VERSION ""

NS_ :

BS_:

BU_: PowertrainControlModule AtmosphericSensor SafetyRestraintSystem2 Aftertreatment_2_GasOutlet Aftertreatment_2_GasIntake DieselPartFilterControl Turbocharger SafetyRestraintSystem1 CabDisplay2 Aftertreatment_1_GasOutlet Aftertreatment_1_GasIntake OnBoardDataLogger OffBoardDiagnosticTool2 OffBoardDiagnosticTool1 FileServer ParkingBrakeController SeatController2 FanDriveController SteeringColumnUnit CommunicationUnitRadio CommunicationUnitSatellite CommunicationUnitCellular PropulsionBatteryCharger ChassisController2 ChassisController1 EngineValveControl AuxiliaryHeater2 AuxiliaryHeater1 ClutchUnit RampControl InformationSystem1 SuspensionSystemController2 OilSensor VehicleDynamicStability ExhaustEmissionController TransmissionDisplay2 TransmissionDisplay1 ClimateControl2 WaterPumpController RearAxleSteeringController LightingOperatorControl SeatController1 IgnitionController2 IgnitionController1 TirePressureController CabController2 CabController1 PneumaticSystemController SuspensionSystemController1 HydraulicPumpController EnduranceBrakingSystem RetarderExhaustEngine2 OnBoardDiagnosticUnit HeadwayController RetarderExhaustEngine1 CabDisplay1 ManagementComputer VirtualTerminal OffVehicleGateway PowerTakeOffFront HitchControl AuxiliaryValveControl BodyController TractorTrailerBridge1 StarterSystem ElectricalSystem VehicleSecurity VehicleNavigation AerodynamicControl ElectricalChargingSystem ClimateControl1 TripRecorder InstrumentCluster SuspensionDriveAxle2 SuspensionDriveAxle1 SuspensionSteerAxle SteeringController FuelSystem CruiseControl RetarderDriveline RetarderEngine BrakesDriveAxle2 BrakesDriveAxle1 BrakesSystemController BrakesSteerAxle AxleDrive2 AxleDrive1 AxleSteering PowerTakeOff ShiftConsoleSecondary ShiftConsolePrimary Transmission2 Transmission1 Engine2 Engine1

BO_ 2566663422 BCLC: 8 Vector__XXX
 SG_ TrlrBrkClprLnngClranceAxle5Right : 38|2@1+ (1,0) [0|3] "" Vector__XXX
 SG_ TrlrBrkClprLnngClaranceAxle5Left : 36|2@1+ (1,0) [0|3] "" Vector__XXX
 SG_ TrlrBrkClprLnngClranceAxle4Right : 34|2@1+ (1,0) [0|3] "" Vector__XXX
 SG_ TrlrBrkClprLnngClaranceAxle4Left : 32|2@1+ (1,0) [0|3] "" Vector__XXX
 SG_ TrlrBrkClprLnngClranceAxle3Right : 30|2@1+ (1,0) [0|3] "" Vector__XXX
 SG_ TrlrBrkClprLnngClaranceAxle3Left : 28|2@1+ (1,0) [0|3] "" Vector__XXX
 SG_ TrlrBrkClprLnngClranceAxle2Right : 26|2@1+ (1,0) [0|3] "" Vector__XXX
 SG_ TrlrBrkClprLnngClaranceAxle2Left : 24|2@1+ (1,0) [0|3] "" Vector__XXX
 SG_ TrlrBrkClprLnngClranceAxle1Right : 22|2@1+ (1,0) [0|3] "" Vector__XXX
 SG_ TrlrBrkClprLnngClaranceAxle1Left : 20|2@1+ (1,0) [0|3] "" Vector__XXX
 SG_ TrctrBrkClprLnngClrnceAxle5Right : 18|2@1+ (1,0) [0|3] "" Vector__XXX
 SG_ TrctrBrkClprLnngClranceAxle5Left : 16|2@1+ (1,0) [0|3] "" Vector__XXX
 SG_ TrctrBrkClprLnngClrnceAxle4Right : 14|2@1+ (1,0) [0|3] "" Vector__XXX
 SG_ TrctrBrkClprLnngClranceAxle4Left : 12|2@1+ (1,0) [0|3] "" Vector__XXX
 SG_ TrctrBrkClprLnngClrnceAxle3Right : 10|2@1+ (1,0) [0|3] "" Vector__XXX
 SG_ TrctrBrkClprLnngClranceAxle3Left : 8|2@1+ (1,0) [0|3] "" Vector__XXX
 SG_ TrctrBrkClprLnngClrnceAxle2Right : 6|2@1+ (1,0) [0|3] "" Vector__XXX
 SG_ TrctrBrkClprLnngClranceAxle2Left : 4|2@1+ (1,0) [0|3] "" Vector__XXX
 SG_ TrctrBrkClprLnngClrnceAxle1Right : 2|2@1+ (1,0) [0|3] "" Vector__XXX
 SG_ TrctrBrkClprLnngClranceAxle1Left : 0|2@1+ (1,0) [0|3] "" Vector__XXX

BO_ 2566663166 CCVS4: 8 Vector__XXX
 SG_ CruiseCtrlAdjustedMaxSpeed : 16|16@1+ (0.00390625,0) [0|250.996] "km/h" Vector__XXX
 SG_ AppliedVehicleSpeedLimit : 0|16@1+ (0.00390625,0) [0|250.996] "km/h" Vector__XXX

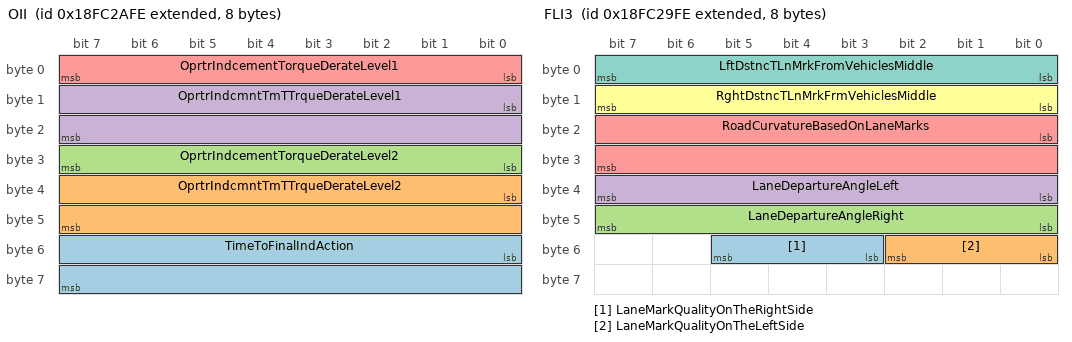
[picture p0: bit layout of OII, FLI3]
BO_ 2566662910 OII: 8 Vector__XXX
 SG_ TimeToFinalIndAction : 48|16@1+ (1,0) [0|64255] "min" Vector__XXX
 SG_ OprtrIndcmntTmTTrqueDerateLevel2 : 32|16@1+ (1,0) [0|64255] "min" Vector__XXX
 SG_ OprtrIndcementTorqueDerateLevel2 : 24|8@1+ (1,0) [0|250] "%" Vector__XXX
 SG_ OprtrIndcmntTmTTrqueDerateLevel1 : 8|16@1+ (1,0) [0|64255] "min" Vector__XXX
 SG_ OprtrIndcementTorqueDerateLevel1 : 0|8@1+ (1,0) [0|250] "%" Vector__XXX

BO_ 2566662654 FLI3: 8 Vector__XXX
 SG_ LaneMarkQualityOnTheRightSide : 51|3@1+ (1,0) [0|7] "" Vector__XXX
 SG_ LaneMarkQualityOnTheLeftSide : 48|3@1+ (1,0) [0|7] "" Vector__XXX
 SG_ LaneDepartureAngleRight : 40|8@1+ (0.1,-12.5) [-12.5|12.5] "deg" Vector__XXX
 SG_ LaneDepartureAngleLeft : 32|8@1+ (0.1,-12.5) [-12.5|12.5] "deg" Vector__XXX
 SG_ RoadCurvatureBasedOnLaneMarks : 16|16@1+ (0.0078125,-250) [-250|251.992] "1/km" Vector__XXX
 SG_ RghtDstncTLnMrkFrmVehiclesMiddle : 8|8@1+ (0.02,0) [0|5] "m" Vector__XXX
 SG_ LftDstncTLnMrkFromVehiclesMiddle : 0|8@1+ (0.02,0) [0|5] "m" Vector__XXX

BO_ 2566662142 A1DEFI2: 8 Vector__XXX
 SG_ Ctrl2Temp : 8|8@1+ (1,-40) [-40|210] "°C" Vector__XXX
 SG_ Ctrl1Temp : 0|8@1+ (1,-40) [-40|210] "°C" Vector__XXX

BO_ 2566661630 AT1T1I2: 8 Vector__XXX
 SG_ Htr2 : 16|8@1+ (0.4,0) [0|100] "%" Vector__XXX
 SG_ Temp2 : 8|8@1+ (1,-40) [-40|210] "°C" Vector__XXX
 SG_ Volume2 : 0|8@1+ (0.4,0) [0|100] "%" Vector__XXX

BO_ 2566661374 A2DEFT1: 8 Vector__XXX
 SG_ Ctrl2Temp : 8|8@1+ (1,-40) [-40|210] "°C" Vector__XXX
 SG_ CtrlTemp : 0|8@1+ (1,-40) [-40|210] "°C" Vector__XXX
 SG_ Htr2 : 16|8@1+ (0.4,0) [0|100] "%" Vector__XXX
 SG_ Temp2 : 8|8@1+ (1,-40) [-40|210] "°C" Vector__XXX
 SG_ Volume2 : 0|8@1+ (0.4,0) [0|100] "%" Vector__XXX

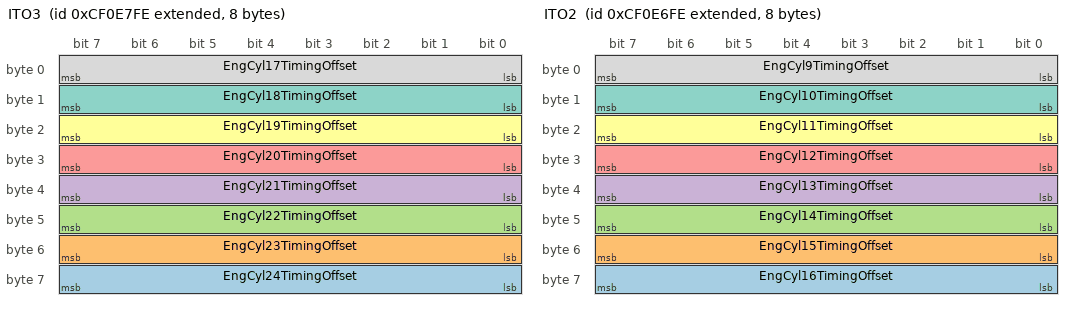
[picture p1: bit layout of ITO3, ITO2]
BO_ 2364598270 ITO3: 8 Vector__XXX
 SG_ EngCyl24TimingOffset : 56|8@1+ (0.1,-12.5) [-12.5|12.5] "deg" Vector__XXX
 SG_ EngCyl23TimingOffset : 48|8@1+ (0.1,-12.5) [-12.5|12.5] "deg" Vector__XXX
 SG_ EngCyl22TimingOffset : 40|8@1+ (0.1,-12.5) [-12.5|12.5] "deg" Vector__XXX
 SG_ EngCyl21TimingOffset : 32|8@1+ (0.1,-12.5) [-12.5|12.5] "deg" Vector__XXX
 SG_ EngCyl20TimingOffset : 24|8@1+ (0.1,-12.5) [-12.5|12.5] "deg" Vector__XXX
 SG_ EngCyl19TimingOffset : 16|8@1+ (0.1,-12.5) [-12.5|12.5] "deg" Vector__XXX
 SG_ EngCyl18TimingOffset : 8|8@1+ (0.1,-12.5) [-12.5|12.5] "deg" Vector__XXX
 SG_ EngCyl17TimingOffset : 0|8@1+ (0.1,-12.5) [-12.5|12.5] "deg" Vector__XXX

BO_ 2364598014 ITO2: 8 Vector__XXX
 SG_ EngCyl16TimingOffset : 56|8@1+ (0.1,-12.5) [-12.5|12.5] "deg" Vector__XXX
 SG_ EngCyl15TimingOffset : 48|8@1+ (0.1,-12.5) [-12.5|12.5] "deg" Vector__XXX
 SG_ EngCyl14TimingOffset : 40|8@1+ (0.1,-12.5) [-12.5|12.5] "deg" Vector__XXX
 SG_ EngCyl13TimingOffset : 32|8@1+ (0.1,-12.5) [-12.5|12.5] "deg" Vector__XXX
 SG_ EngCyl12TimingOffset : 24|8@1+ (0.1,-12.5) [-12.5|12.5] "deg" Vector__XXX
 SG_ EngCyl11TimingOffset : 16|8@1+ (0.1,-12.5) [-12.5|12.5] "deg" Vector__XXX
 SG_ EngCyl10TimingOffset : 8|8@1+ (0.1,-12.5) [-12.5|12.5] "deg" Vector__XXX
 SG_ EngCyl9TimingOffset : 0|8@1+ (0.1,-12.5) [-12.5|12.5] "deg" Vector__XXX

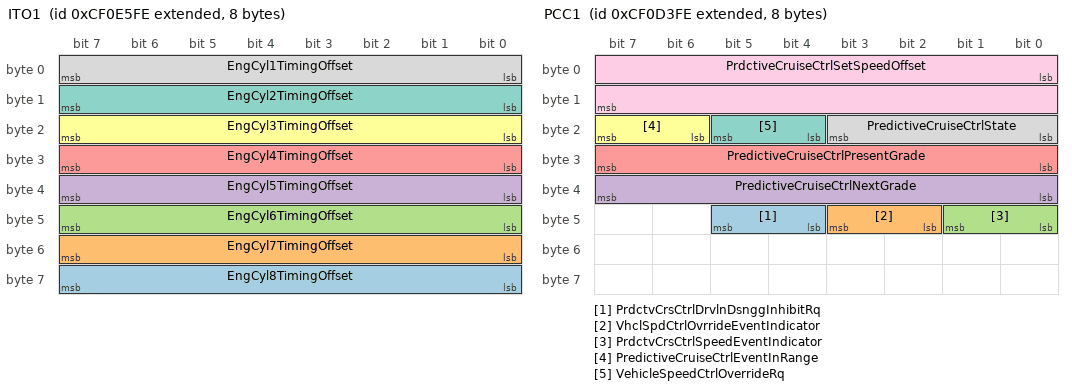
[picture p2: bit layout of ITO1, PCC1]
BO_ 2364597758 ITO1: 8 Vector__XXX
 SG_ EngCyl8TimingOffset : 56|8@1+ (0.1,-12.5) [-12.5|12.5] "deg" Vector__XXX
 SG_ EngCyl7TimingOffset : 48|8@1+ (0.1,-12.5) [-12.5|12.5] "deg" Vector__XXX
 SG_ EngCyl6TimingOffset : 40|8@1+ (0.1,-12.5) [-12.5|12.5] "deg" Vector__XXX
 SG_ EngCyl5TimingOffset : 32|8@1+ (0.1,-12.5) [-12.5|12.5] "deg" Vector__XXX
 SG_ EngCyl4TimingOffset : 24|8@1+ (0.1,-12.5) [-12.5|12.5] "deg" Vector__XXX
 SG_ EngCyl3TimingOffset : 16|8@1+ (0.1,-12.5) [-12.5|12.5] "deg" Vector__XXX
 SG_ EngCyl2TimingOffset : 8|8@1+ (0.1,-12.5) [-12.5|12.5] "deg" Vector__XXX
 SG_ EngCyl1TimingOffset : 0|8@1+ (0.1,-12.5) [-12.5|12.5] "deg" Vector__XXX

BO_ 2364593150 PCC1: 8 Vector__XXX
 SG_ PrdctvCrsCtrlDrvlnDsnggInhibitRq : 44|2@1+ (1,0) [0|3] "" Vector__XXX
 SG_ VhclSpdCtrlOvrrideEventIndicator : 42|2@1+ (1,0) [0|3] "" Vector__XXX
 SG_ PrdctvCrsCtrlSpeedEventIndicator : 40|2@1+ (1,0) [0|3] "" Vector__XXX
 SG_ PredictiveCruiseCtrlNextGrade : 32|8@1+ (0.125,-16) [-16|15.25] "%" Vector__XXX
 SG_ PredictiveCruiseCtrlPresentGrade : 24|8@1+ (0.125,-16) [-16|15.25] "%" Vector__XXX
 SG_ PredictiveCruiseCtrlEventInRange : 22|2@1+ (1,0) [0|3] "" Vector__XXX
 SG_ VehicleSpeedCtrlOverrideRq : 20|2@1+ (1,0) [0|3] "" Vector__XXX
 SG_ PredictiveCruiseCtrlState : 16|4@1+ (1,0) [0|15] "" Vector__XXX
 SG_ PrdctiveCruiseCtrlSetSpeedOffset : 0|16@1+ (0.00390625,-125) [-125|125.996] "km/h" Vector__XXX

BO_ 2364592894 EEC18: 8 Vector__XXX
 SG_ InAirSourceVlv : 16|2@1+ (1,0) [0|3] "" Vector__XXX
 SG_ EngCylHeadBypassActuator1Cmd : 0|16@1+ (0.0025,0) [0|160.6375] "%" Vector__XXX

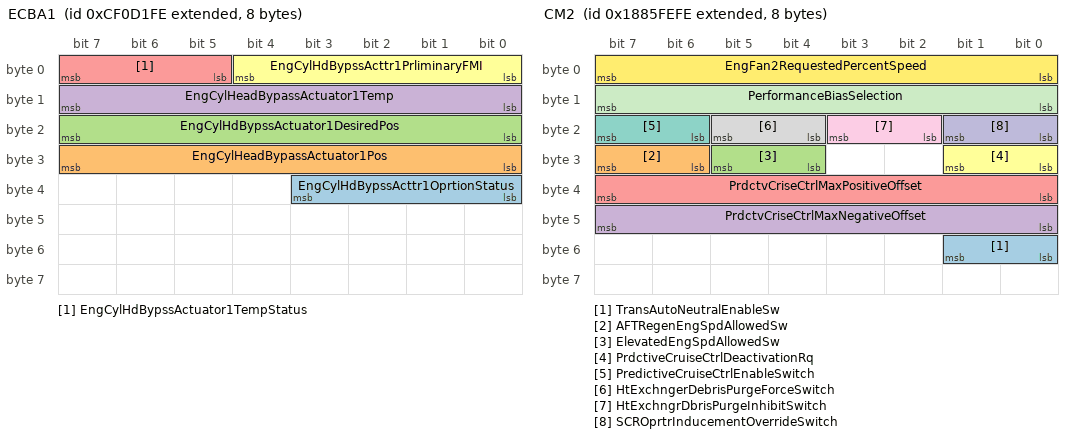
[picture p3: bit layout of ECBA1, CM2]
BO_ 2364592638 ECBA1: 8 Vector__XXX
 SG_ EngCylHdBypssActtr1OprtionStatus : 32|4@1+ (1,0) [0|15] "" Vector__XXX
 SG_ EngCylHeadBypassActuator1Pos : 24|8@1+ (0.4,0) [0|100] "%" Vector__XXX
 SG_ EngCylHdBypssActuator1DesiredPos : 16|8@1+ (0.4,0) [0|100] "%" Vector__XXX
 SG_ EngCylHeadBypassActuator1Temp : 8|8@1+ (1,-40) [-40|210] "°C" Vector__XXX
 SG_ EngCylHdBypssActuator1TempStatus : 5|3@1+ (1,0) [0|7] "" Vector__XXX
 SG_ EngCylHdBypssActtr1PrliminaryFMI : 0|5@1+ (1,0) [0|31] "" Vector__XXX

BO_ 2364592382 ECCR: 8 Vector__XXX
 SG_ EngCyl24ExcludeFromCombustionRq : 54|2@1+ (1,0) [0|3] "" Vector__XXX
 SG_ EngCyl23ExcludeFromCombustionRq : 52|2@1+ (1,0) [0|3] "" Vector__XXX
 SG_ EngCyl22ExcludeFromCombustionRq : 50|2@1+ (1,0) [0|3] "" Vector__XXX
 SG_ EngCyl21ExcludeFromCombustionRq : 48|2@1+ (1,0) [0|3] "" Vector__XXX
 SG_ EngCyl20ExcludeFromCombustionRq : 46|2@1+ (1,0) [0|3] "" Vector__XXX
 SG_ EngCyl19ExcludeFromCombustionRq : 44|2@1+ (1,0) [0|3] "" Vector__XXX
 SG_ EngCyl18ExcludeFromCombustionRq : 42|2@1+ (1,0) [0|3] "" Vector__XXX
 SG_ EngCyl17ExcludeFromCombustionRq : 40|2@1+ (1,0) [0|3] "" Vector__XXX
 SG_ EngCyl16ExcludeFromCombustionRq : 38|2@1+ (1,0) [0|3] "" Vector__XXX
 SG_ EngCyl15ExcludeFromCombustionRq : 36|2@1+ (1,0) [0|3] "" Vector__XXX
 SG_ EngCyl14ExcludeFromCombustionRq : 34|2@1+ (1,0) [0|3] "" Vector__XXX
 SG_ EngCyl13ExcludeFromCombustionRq : 32|2@1+ (1,0) [0|3] "" Vector__XXX
 SG_ EngCyl12ExcludeFromCombustionRq : 30|2@1+ (1,0) [0|3] "" Vector__XXX
 SG_ EngCyl11ExcludeFromCombustionRq : 28|2@1+ (1,0) [0|3] "" Vector__XXX
 SG_ EngCyl10ExcludeFromCombustionRq : 26|2@1+ (1,0) [0|3] "" Vector__XXX
 SG_ EngCyl9ExcludeFromCombustionRq : 24|2@1+ (1,0) [0|3] "" Vector__XXX
 SG_ EngCyl8ExcludeFromCombustionRq : 22|2@1+ (1,0) [0|3] "" Vector__XXX
 SG_ EngCyl7ExcludeFromCombustionRq : 20|2@1+ (1,0) [0|3] "" Vector__XXX
 SG_ EngCyl6ExcludeFromCombustionRq : 18|2@1+ (1,0) [0|3] "" Vector__XXX
 SG_ EngCyl5ExcludeFromCombustionRq : 16|2@1+ (1,0) [0|3] "" Vector__XXX
 SG_ EngCyl4ExcludeFromCombustionRq : 14|2@1+ (1,0) [0|3] "" Vector__XXX
 SG_ EngCyl3ExcludeFromCombustionRq : 12|2@1+ (1,0) [0|3] "" Vector__XXX
 SG_ EngCyl2ExcludeFromCombustionRq : 10|2@1+ (1,0) [0|3] "" Vector__XXX
 SG_ EngCyl1ExcludeFromCombustionRq : 8|2@1+ (1,0) [0|3] "" Vector__XXX
 SG_ NmbrOfEngCylndrsTExcldFrmCmbston : 0|8@1+ (1,0) [0|24] "" Vector__XXX

BO_ 2364567294 FPAC: 8 Vector__XXX
 SG_ EngFlInjctnPump2FuelCtrlValveCmd : 16|16@1+ (0.0025,0) [0|100] "%" Vector__XXX
 SG_ EngFlInjctnPump1FuelCtrlValveCmd : 0|16@1+ (0.0025,0) [0|100] "%" Vector__XXX

BO_ 2558918398 CM2: 8 Vector__XXX
 SG_ TransAutoNeutralEnableSw : 48|2@1+ (1,0) [0|3] "" Vector__XXX
 SG_ AFTRegenEngSpdAllowedSw : 30|2@1+ (1,0) [0|3] "" Vector__XXX
 SG_ ElevatedEngSpdAllowedSw : 28|2@1+ (1,0) [0|3] "" Vector__XXX
 SG_ PrdctvCriseCtrlMaxNegativeOffset : 40|8@1+ (0.125,-31.25) [-31.25|0] "km/h" Vector__XXX
 SG_ PrdctvCriseCtrlMaxPositiveOffset : 32|8@1+ (0.125,0) [0|31.25] "km/h" Vector__XXX
 SG_ PrdctiveCruiseCtrlDeactivationRq : 24|2@1+ (1,0) [0|3] "" Vector__XXX
 SG_ PredictiveCruiseCtrlEnableSwitch : 22|2@1+ (1,0) [0|3] "" Vector__XXX
 SG_ HtExchngerDebrisPurgeForceSwitch : 20|2@1+ (1,0) [0|3] "" Vector__XXX
 SG_ HtExchngrDbrisPurgeInhibitSwitch : 18|2@1+ (1,0) [0|3] "" Vector__XXX
 SG_ SCROprtrInducementOverrideSwitch : 16|2@1+ (1,0) [0|3] "" Vector__XXX
 SG_ PerformanceBiasSelection : 8|8@1+ (0.4,0) [0|100] "%" Vector__XXX
 SG_ EngFan2RequestedPercentSpeed : 0|8@1+ (0.4,0) [0|100] "%" Vector__XXX

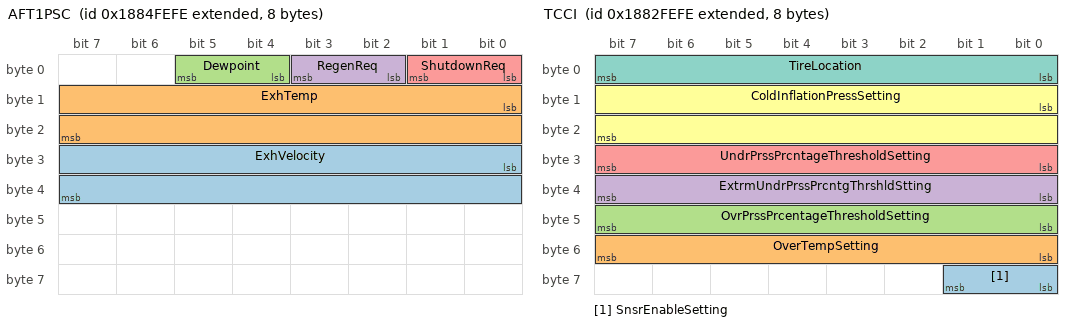
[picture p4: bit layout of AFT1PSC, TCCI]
BO_ 2558852862 AFT1PSC: 8 Vector__XXX
 SG_ ExhVelocity : 24|16@1+ (0.00390625,0) [0|250.996] "km/h" Vector__XXX
 SG_ ExhTemp : 8|16@1+ (0.03125,-273) [-273|1734.96875] "°C" Vector__XXX
 SG_ Dewpoint : 4|2@1+ (1,0) [0|3] "" Vector__XXX
 SG_ RegenReq : 2|2@1+ (1,0) [0|3] "" Vector__XXX
 SG_ ShutdownReq : 0|2@1+ (1,0) [0|3] "" Vector__XXX

BO_ 2558787326 PCIC: 8 Vector__XXX
 SG_ PayloadCorrectionFactorCmd : 24|8@1+ (1,-125) [-125|125] "%" Vector__XXX
 SG_ PayloadCalibCommandedWeight : 8|16@1+ (2,0) [0|128510] "kg" Vector__XXX
 SG_ PayloadCalibSetPointCmd : 0|4@1+ (1,0) [0|15] "" Vector__XXX

BO_ 2558721790 TCCI: 8 Vector__XXX
 SG_ SnsrEnableSetting : 56|2@1+ (1,0) [0|3] "" Vector__XXX
 SG_ OverTempSetting : 48|8@1+ (1,-40) [-40|210] "°C" Vector__XXX
 SG_ OvrPrssPrcentageThresholdSetting : 40|8@1+ (0.5,0) [0|125] "%" Vector__XXX
 SG_ ExtrmUndrPrssPrcntgThrshldStting : 32|8@1+ (0.5,0) [0|125] "%" Vector__XXX
 SG_ UndrPrssPrcntageThresholdSetting : 24|8@1+ (0.5,0) [0|125] "%" Vector__XXX
 SG_ ColdInflationPressSetting : 8|16@1+ (1,0) [0|64255] "kPa" Vector__XXX
 SG_ TireLocation : 0|8@1+ (1,0) [0|0] "" Vector__XXX

BO_ 2558656254 AFTSC: 8 Vector__XXX
 SG_ RqToPermitDEFDosingTestInjection : 4|3@1+ (1,0) [0|7] "" Vector__XXX
 SG_ RqToPermitDEFHydStiffnessCheck : 2|2@1+ (1,0) [0|3] "" Vector__XXX
 SG_ ThermalManagementInhReq : 0|2@1+ (1,0) [0|3] "" Vector__XXX

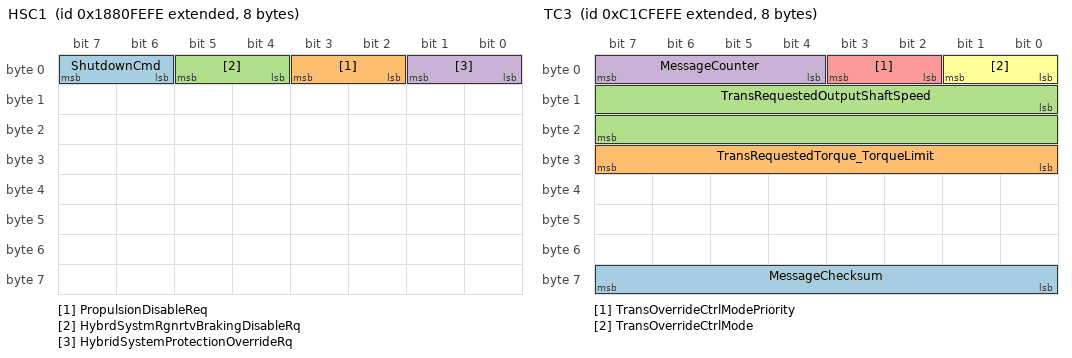
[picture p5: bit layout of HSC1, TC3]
BO_ 2558590718 HSC1: 8 Vector__XXX
 SG_ ShutdownCmd : 6|2@1+ (1,0) [0|3] "" Vector__XXX
 SG_ PropulsionDisableReq : 2|2@1+ (1,0) [0|3] "" Vector__XXX
 SG_ HybrdSystmRgnrtvBrakingDisableRq : 4|2@1+ (1,0) [0|3] "" Vector__XXX
 SG_ HybridSystemProtectionOverrideRq : 0|2@1+ (1,0) [0|3] "" Vector__XXX

BO_ 2350776062 EIC: 8 Vector__XXX
 SG_ EngTimingAdvance : 0|16@1+ (0.0078125,-200) [-200|301.99] "deg" Vector__XXX

BO_ 2350710526 TC3: 8 Vector__XXX
 SG_ MessageChecksum : 56|8@1+ (1,0) [0|255] "" Vector__XXX
 SG_ TransRequestedTorque_TorqueLimit : 24|8@1+ (1,-125) [-125|125] "%" Vector__XXX
 SG_ TransRequestedOutputShaftSpeed : 8|16@1+ (0.25,-8031.75) [-8031.375|8031.375] "rpm" Vector__XXX
 SG_ MessageCounter : 4|4@1+ (1,0) [0|15] "" Vector__XXX
 SG_ TransOverrideCtrlModePriority : 2|2@1+ (1,0) [0|3] "" Vector__XXX
 SG_ TransOverrideCtrlMode : 0|2@1+ (1,0) [0|3] "" Vector__XXX

BO_ 2582642430 PropA2: 8 Vector__XXX
 SG_ ManufacturerSpecificInformation : 0|64@1+ (1,0) [0|0] "" Vector__XXX

BO_ 2566836734 DM09: 8 Vector__XXX

BO_ 2566801918 GBSD: 8 Vector__XXX
 SG_ GroundBasedDirection : 56|2@1+ (1,0) [0|0] "" Vector__XXX
 SG_ GroundBasedImplementDistance : 16|32@1+ (1,0) [0|0] "" Vector__XXX
 SG_ GroundBasedImplementSpeed : 0|16@1+ (1,0) [0|0] "" Vector__XXX

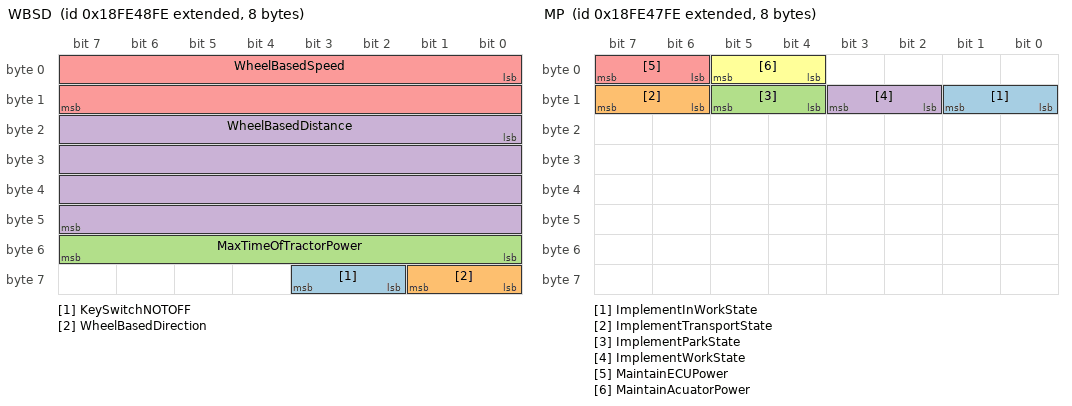
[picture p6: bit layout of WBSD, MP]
BO_ 2566801662 WBSD: 8 Vector__XXX
 SG_ KeySwitchNOTOFF : 58|2@1+ (1,0) [0|0] "" Vector__XXX
 SG_ WheelBasedDirection : 56|2@1+ (1,0) [0|0] "" Vector__XXX
 SG_ MaxTimeOfTractorPower : 48|8@1+ (1,0) [0|0] "" Vector__XXX
 SG_ WheelBasedDistance : 16|32@1+ (1,0) [0|0] "" Vector__XXX
 SG_ WheelBasedSpeed : 0|16@1+ (1,0) [0|0] "" Vector__XXX

BO_ 2566801406 MP: 8 Vector__XXX
 SG_ ImplementInWorkState : 8|2@1+ (1,0) [0|0] "" Vector__XXX
 SG_ ImplementTransportState : 14|2@1+ (1,0) [0|0] "" Vector__XXX
 SG_ ImplementParkState : 12|2@1+ (1,0) [0|0] "" Vector__XXX
 SG_ ImplementWorkState : 10|2@1+ (1,0) [0|0] "" Vector__XXX
 SG_ MaintainECUPower : 6|2@1+ (1,0) [0|0] "" Vector__XXX
 SG_ MaintainAcuatorPower : 4|2@1+ (1,0) [0|0] "" Vector__XXX

BO_ 2566801150 FHS: 8 Vector__XXX
 SG_ FrontDraft : 24|16@1+ (1,0) [0|0] "" Vector__XXX
 SG_ FrontNominalLowerLinkForce : 16|8@1+ (1,0) [0|0] "" Vector__XXX
 SG_ FrontHitchInworkIndication : 14|2@1+ (1,0) [0|0] "" Vector__XXX
 SG_ FrontHitchPos : 0|8@1+ (1,0) [0|0] "" Vector__XXX

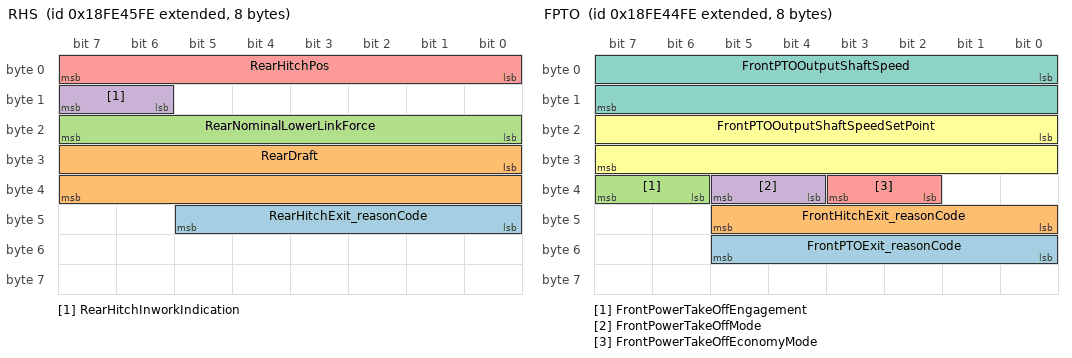
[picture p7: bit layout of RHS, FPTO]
BO_ 2566800894 RHS: 8 Vector__XXX
 SG_ RearHitchExit_reasonCode : 40|6@1+ (1,0) [0|0] "" Vector__XXX
 SG_ RearDraft : 24|16@1+ (1,0) [0|0] "" Vector__XXX
 SG_ RearNominalLowerLinkForce : 16|8@1+ (1,0) [0|0] "" Vector__XXX
 SG_ RearHitchInworkIndication : 14|2@1+ (1,0) [0|0] "" Vector__XXX
 SG_ RearHitchPos : 0|8@1+ (1,0) [0|0] "" Vector__XXX

BO_ 2566800638 FPTO: 8 Vector__XXX
 SG_ FrontPTOExit_reasonCode : 48|6@1+ (1,0) [0|0] "" Vector__XXX
 SG_ FrontHitchExit_reasonCode : 40|6@1+ (1,0) [0|0] "" Vector__XXX
 SG_ FrontPowerTakeOffEngagement : 38|2@1+ (1,0) [0|0] "" Vector__XXX
 SG_ FrontPowerTakeOffMode : 36|2@1+ (1,0) [0|0] "" Vector__XXX
 SG_ FrontPowerTakeOffEconomyMode : 34|2@1+ (1,0) [0|0] "" Vector__XXX
 SG_ FrontPTOOutputShaftSpeedSetPoint : 16|16@1+ (1,0) [0|0] "" Vector__XXX
 SG_ FrontPTOOutputShaftSpeed : 0|16@1+ (1,0) [0|0] "" Vector__XXX

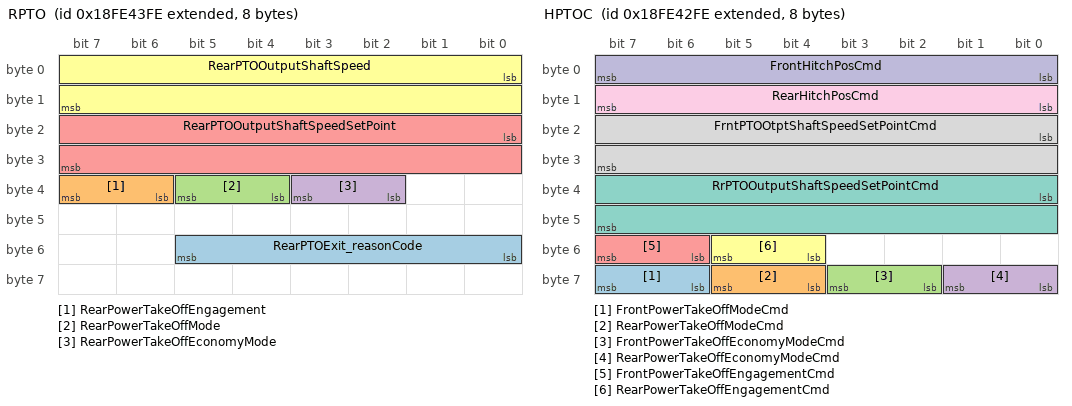
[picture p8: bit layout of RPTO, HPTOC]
BO_ 2566800382 RPTO: 8 Vector__XXX
 SG_ RearPTOExit_reasonCode : 48|6@1+ (1,0) [0|0] "" Vector__XXX
 SG_ RearPowerTakeOffEngagement : 38|2@1+ (1,0) [0|0] "" Vector__XXX
 SG_ RearPowerTakeOffMode : 36|2@1+ (1,0) [0|0] "" Vector__XXX
 SG_ RearPowerTakeOffEconomyMode : 34|2@1+ (1,0) [0|0] "" Vector__XXX
 SG_ RearPTOOutputShaftSpeedSetPoint : 16|16@1+ (1,0) [0|0] "" Vector__XXX
 SG_ RearPTOOutputShaftSpeed : 0|16@1+ (1,0) [0|0] "" Vector__XXX

BO_ 2566800126 HPTOC: 8 Vector__XXX
 SG_ FrontPowerTakeOffModeCmd : 62|2@1+ (1,0) [0|0] "" Vector__XXX
 SG_ RearPowerTakeOffModeCmd : 60|2@1+ (1,0) [0|0] "" Vector__XXX
 SG_ FrontPowerTakeOffEconomyModeCmd : 58|2@1+ (1,0) [0|0] "" Vector__XXX
 SG_ RearPowerTakeOffEconomyModeCmd : 56|2@1+ (1,0) [0|0] "" Vector__XXX
 SG_ FrontPowerTakeOffEngagementCmd : 54|2@1+ (1,0) [0|0] "" Vector__XXX
 SG_ RearPowerTakeOffEngagementCmd : 52|2@1+ (1,0) [0|0] "" Vector__XXX
 SG_ RrPTOOutputShaftSpeedSetPointCmd : 32|16@1+ (1,0) [0|0] "" Vector__XXX
 SG_ FrntPTOOtptShaftSpeedSetPointCmd : 16|16@1+ (1,0) [0|0] "" Vector__XXX
 SG_ RearHitchPosCmd : 8|8@1+ (1,0) [0|0] "" Vector__XXX
 SG_ FrontHitchPosCmd : 0|8@1+ (1,0) [0|0] "" Vector__XXX

BO_ 2566799358 AV15C: 8 Vector__XXX
 SG_ AuxValve15FailSafeModeCmd : 22|2@1+ (1,0) [0|0] "" Vector__XXX
 SG_ AuxValve15StateCmd : 16|4@1+ (1,0) [0|0] "" Vector__XXX
 SG_ AuxValve15PortFlowCmd : 0|8@1+ (1,0) [0|0] "" Vector__XXX

BO_ 2566799102 AV14C: 8 Vector__XXX
 SG_ AuxValve14FailSafeModeCmd : 22|2@1+ (1,0) [0|0] "" Vector__XXX
 SG_ AuxValve14StateCmd : 16|4@1+ (1,0) [0|0] "" Vector__XXX
 SG_ AuxValve14PortFlowCmd : 0|8@1+ (1,0) [0|0] "" Vector__XXX

BO_ 2566798846 AV13C: 8 Vector__XXX
 SG_ AuxValve13FailSafeModeCmd : 22|2@1+ (1,0) [0|0] "" Vector__XXX
 SG_ AuxValve13StateCmd : 16|4@1+ (1,0) [0|0] "" Vector__XXX
 SG_ AuxValve13PortFlowCmd : 0|8@1+ (1,0) [0|0] "" Vector__XXX

BO_ 2566798590 AV12C: 8 Vector__XXX
 SG_ AuxValve12FailSafeModeCmd : 22|2@1+ (1,0) [0|0] "" Vector__XXX
 SG_ AuxValve12StateCmd : 16|4@1+ (1,0) [0|0] "" Vector__XXX
 SG_ AuxValve12PortFlowCmd : 0|8@1+ (1,0) [0|0] "" Vector__XXX

BO_ 2566798334 AV11C: 8 Vector__XXX
 SG_ AuxValve11FailSafeModeCmd : 22|2@1+ (1,0) [0|0] "" Vector__XXX
 SG_ AuxValve11StateCmd : 16|4@1+ (1,0) [0|0] "" Vector__XXX
 SG_ AuxValve11PortFlowCmd : 0|8@1+ (1,0) [0|0] "" Vector__XXX

BO_ 2566798078 AV10C: 8 Vector__XXX
 SG_ AuxValve10FailSafeModeCmd : 22|2@1+ (1,0) [0|0] "" Vector__XXX
 SG_ AuxValve10StateCmd : 16|4@1+ (1,0) [0|0] "" Vector__XXX
 SG_ AuxValve10PortFlowCmd : 0|8@1+ (1,0) [0|0] "" Vector__XXX

BO_ 2566797822 AV09C: 8 Vector__XXX
 SG_ AuxValve9FailSafeModeCmd : 22|2@1+ (1,0) [0|0] "" Vector__XXX
 SG_ AuxValve9StateCmd : 16|4@1+ (1,0) [0|0] "" Vector__XXX
 SG_ AuxValve9PortFlowCmd : 0|8@1+ (1,0) [0|0] "" Vector__XXX

BO_ 2566797566 AV08C: 8 Vector__XXX
 SG_ AuxValve8FailSafeModeCmd : 22|2@1+ (1,0) [0|0] "" Vector__XXX
 SG_ AuxValve8StateCmd : 16|4@1+ (1,0) [0|0] "" Vector__XXX
 SG_ AuxValve8PortFlowCmd : 0|8@1+ (1,0) [0|0] "" Vector__XXX

BO_ 2566797310 AV07C: 8 Vector__XXX
 SG_ AuxValve7FailSafeModeCmd : 22|2@1+ (1,0) [0|0] "" Vector__XXX
 SG_ AuxValve7StateCmd : 16|4@1+ (1,0) [0|0] "" Vector__XXX
 SG_ AuxValve7PortFlowCmd : 0|8@1+ (1,0) [0|0] "" Vector__XXX

BO_ 2566797054 AV06C: 8 Vector__XXX
 SG_ AuxValve6FailSafeModeCmd : 22|2@1+ (1,0) [0|0] "" Vector__XXX
 SG_ AuxValve6StateCmd : 16|4@1+ (1,0) [0|0] "" Vector__XXX
 SG_ AuxValve6PortFlowCmd : 0|8@1+ (1,0) [0|0] "" Vector__XXX

BO_ 2566796798 AV05C: 8 Vector__XXX
 SG_ AuxValve5FailSafeModeCmd : 22|2@1+ (1,0) [0|0] "" Vector__XXX
 SG_ AuxValve5StateCmd : 16|4@1+ (1,0) [0|0] "" Vector__XXX
 SG_ AuxValve5PortFlowCmd : 0|8@1+ (1,0) [0|0] "" Vector__XXX

BO_ 2566796542 AV04C: 8 Vector__XXX
 SG_ AuxValve4FailSafeModeCmd : 22|2@1+ (1,0) [0|0] "" Vector__XXX
 SG_ AuxValve4StateCmd : 16|4@1+ (1,0) [0|0] "" Vector__XXX
 SG_ AuxValve4PortFlowCmd : 0|8@1+ (1,0) [0|0] "" Vector__XXX

BO_ 2566796286 AV03C: 8 Vector__XXX
 SG_ AuxValve3FailSafeModeCmd : 22|2@1+ (1,0) [0|0] "" Vector__XXX
 SG_ AuxValve3StateCmd : 16|4@1+ (1,0) [0|0] "" Vector__XXX
 SG_ AuxValve3PortFlowCmd : 0|8@1+ (1,0) [0|0] "" Vector__XXX

BO_ 2566796030 AV02C: 8 Vector__XXX
 SG_ AuxValve2FailSafeModeCmd : 22|2@1+ (1,0) [0|0] "" Vector__XXX
 SG_ AuxValve2StateCmd : 16|4@1+ (1,0) [0|0] "" Vector__XXX
 SG_ AuxValve2PortFlowCmd : 0|8@1+ (1,0) [0|0] "" Vector__XXX

BO_ 2566795774 AV01C: 8 Vector__XXX
 SG_ AuxValve1FailSafeModeCmd : 22|2@1+ (1,0) [0|0] "" Vector__XXX
 SG_ AuxValve1StateCmd : 16|4@1+ (1,0) [0|0] "" Vector__XXX
 SG_ AuxValve1PortFlowCmd : 0|8@1+ (1,0) [0|0] "" Vector__XXX

BO_ 2566795518 AV00C: 8 Vector__XXX
 SG_ AuxValve0FailSafeModeCmd : 22|2@1+ (1,0) [0|0] "" Vector__XXX
 SG_ AuxValve0StateCmd : 16|4@1+ (1,0) [0|0] "" Vector__XXX
 SG_ AuxValve0PortFlowCmd : 0|8@1+ (1,0) [0|0] "" Vector__XXX

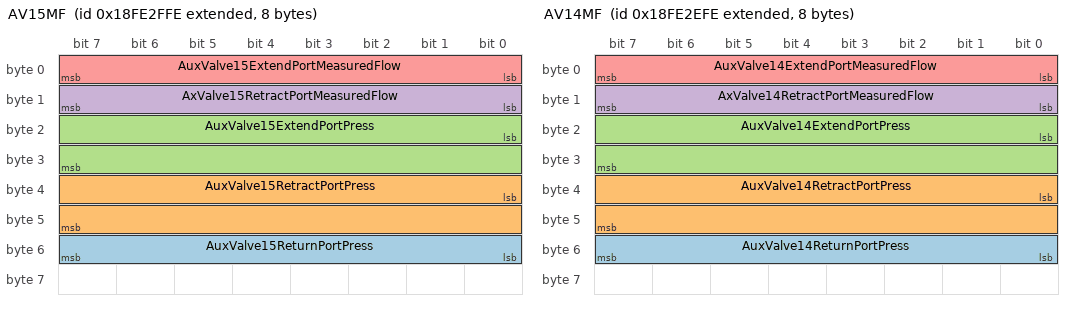
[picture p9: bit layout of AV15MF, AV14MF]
BO_ 2566795262 AV15MF: 8 Vector__XXX
 SG_ AuxValve15ReturnPortPress : 48|8@1+ (1,0) [0|0] "" Vector__XXX
 SG_ AuxValve15RetractPortPress : 32|16@1+ (1,0) [0|0] "" Vector__XXX
 SG_ AuxValve15ExtendPortPress : 16|16@1+ (1,0) [0|0] "" Vector__XXX
 SG_ AxValve15RetractPortMeasuredFlow : 8|8@1+ (1,0) [0|0] "" Vector__XXX
 SG_ AuxValve15ExtendPortMeasuredFlow : 0|8@1+ (1,0) [0|0] "" Vector__XXX

BO_ 2566795006 AV14MF: 8 Vector__XXX
 SG_ AuxValve14ReturnPortPress : 48|8@1+ (1,0) [0|0] "" Vector__XXX
 SG_ AuxValve14RetractPortPress : 32|16@1+ (1,0) [0|0] "" Vector__XXX
 SG_ AuxValve14ExtendPortPress : 16|16@1+ (1,0) [0|0] "" Vector__XXX
 SG_ AxValve14RetractPortMeasuredFlow : 8|8@1+ (1,0) [0|0] "" Vector__XXX
 SG_ AuxValve14ExtendPortMeasuredFlow : 0|8@1+ (1,0) [0|0] "" Vector__XXX

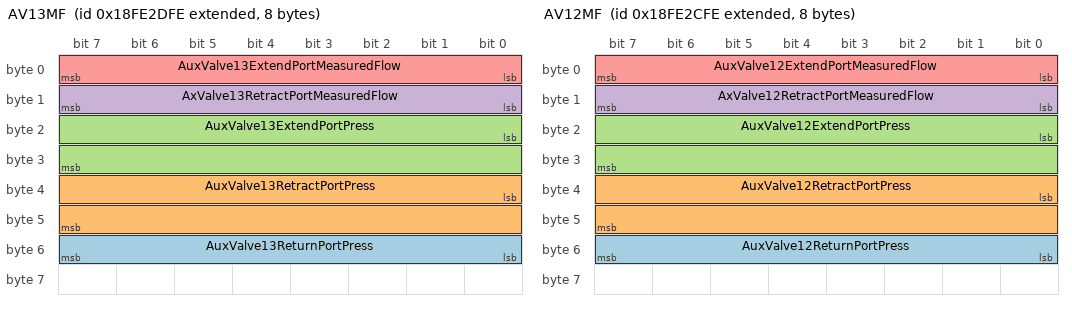
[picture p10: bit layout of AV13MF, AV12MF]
BO_ 2566794750 AV13MF: 8 Vector__XXX
 SG_ AuxValve13ReturnPortPress : 48|8@1+ (1,0) [0|0] "" Vector__XXX
 SG_ AuxValve13RetractPortPress : 32|16@1+ (1,0) [0|0] "" Vector__XXX
 SG_ AuxValve13ExtendPortPress : 16|16@1+ (1,0) [0|0] "" Vector__XXX
 SG_ AxValve13RetractPortMeasuredFlow : 8|8@1+ (1,0) [0|0] "" Vector__XXX
 SG_ AuxValve13ExtendPortMeasuredFlow : 0|8@1+ (1,0) [0|0] "" Vector__XXX

BO_ 2566794494 AV12MF: 8 Vector__XXX
 SG_ AuxValve12ReturnPortPress : 48|8@1+ (1,0) [0|0] "" Vector__XXX
 SG_ AuxValve12RetractPortPress : 32|16@1+ (1,0) [0|0] "" Vector__XXX
 SG_ AuxValve12ExtendPortPress : 16|16@1+ (1,0) [0|0] "" Vector__XXX
 SG_ AxValve12RetractPortMeasuredFlow : 8|8@1+ (1,0) [0|0] "" Vector__XXX
 SG_ AuxValve12ExtendPortMeasuredFlow : 0|8@1+ (1,0) [0|0] "" Vector__XXX

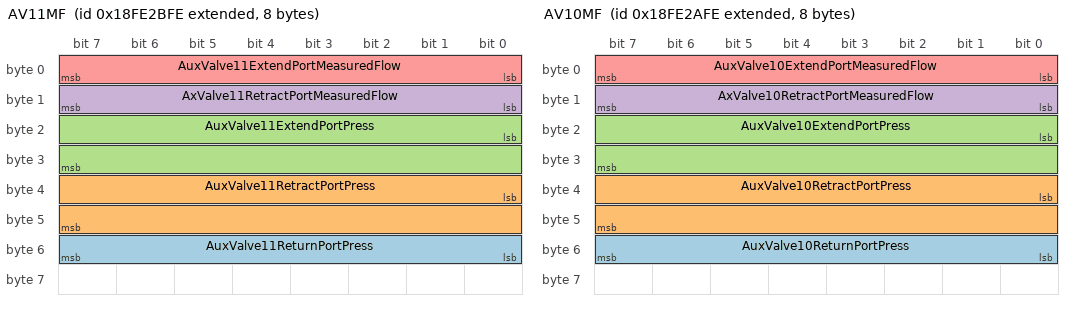
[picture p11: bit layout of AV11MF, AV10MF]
BO_ 2566794238 AV11MF: 8 Vector__XXX
 SG_ AuxValve11ReturnPortPress : 48|8@1+ (1,0) [0|0] "" Vector__XXX
 SG_ AuxValve11RetractPortPress : 32|16@1+ (1,0) [0|0] "" Vector__XXX
 SG_ AuxValve11ExtendPortPress : 16|16@1+ (1,0) [0|0] "" Vector__XXX
 SG_ AxValve11RetractPortMeasuredFlow : 8|8@1+ (1,0) [0|0] "" Vector__XXX
 SG_ AuxValve11ExtendPortMeasuredFlow : 0|8@1+ (1,0) [0|0] "" Vector__XXX

BO_ 2566793982 AV10MF: 8 Vector__XXX
 SG_ AuxValve10ReturnPortPress : 48|8@1+ (1,0) [0|0] "" Vector__XXX
 SG_ AuxValve10RetractPortPress : 32|16@1+ (1,0) [0|0] "" Vector__XXX
 SG_ AuxValve10ExtendPortPress : 16|16@1+ (1,0) [0|0] "" Vector__XXX
 SG_ AxValve10RetractPortMeasuredFlow : 8|8@1+ (1,0) [0|0] "" Vector__XXX
 SG_ AuxValve10ExtendPortMeasuredFlow : 0|8@1+ (1,0) [0|0] "" Vector__XXX

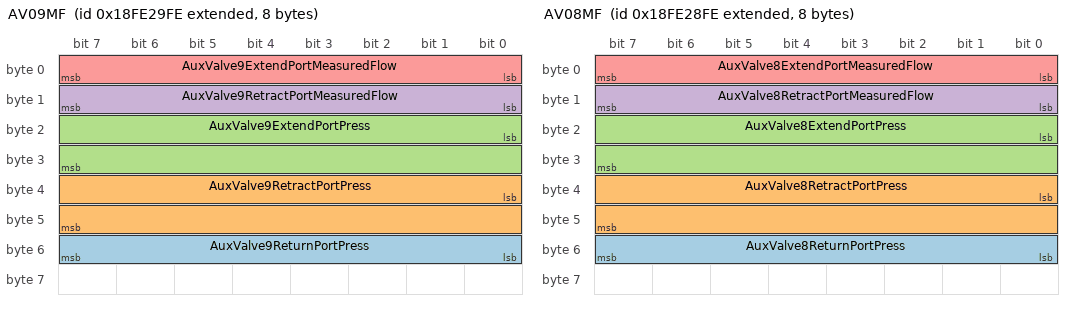
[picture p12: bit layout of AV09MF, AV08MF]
BO_ 2566793726 AV09MF: 8 Vector__XXX
 SG_ AuxValve9ReturnPortPress : 48|8@1+ (1,0) [0|0] "" Vector__XXX
 SG_ AuxValve9RetractPortPress : 32|16@1+ (1,0) [0|0] "" Vector__XXX
 SG_ AuxValve9ExtendPortPress : 16|16@1+ (1,0) [0|0] "" Vector__XXX
 SG_ AuxValve9RetractPortMeasuredFlow : 8|8@1+ (1,0) [0|0] "" Vector__XXX
 SG_ AuxValve9ExtendPortMeasuredFlow : 0|8@1+ (1,0) [0|0] "" Vector__XXX

BO_ 2566793470 AV08MF: 8 Vector__XXX
 SG_ AuxValve8ReturnPortPress : 48|8@1+ (1,0) [0|0] "" Vector__XXX
 SG_ AuxValve8RetractPortPress : 32|16@1+ (1,0) [0|0] "" Vector__XXX
 SG_ AuxValve8ExtendPortPress : 16|16@1+ (1,0) [0|0] "" Vector__XXX
 SG_ AuxValve8RetractPortMeasuredFlow : 8|8@1+ (1,0) [0|0] "" Vector__XXX
 SG_ AuxValve8ExtendPortMeasuredFlow : 0|8@1+ (1,0) [0|0] "" Vector__XXX

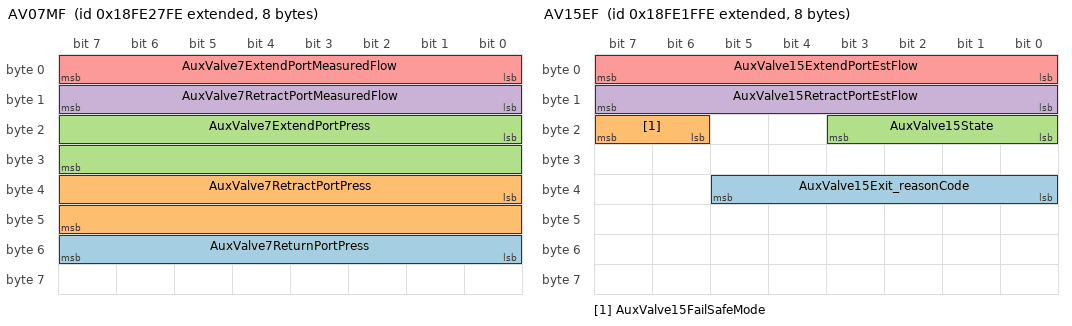
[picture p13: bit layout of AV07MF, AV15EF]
BO_ 2566793214 AV07MF: 8 Vector__XXX
 SG_ AuxValve7ReturnPortPress : 48|8@1+ (1,0) [0|0] "" Vector__XXX
 SG_ AuxValve7RetractPortPress : 32|16@1+ (1,0) [0|0] "" Vector__XXX
 SG_ AuxValve7ExtendPortPress : 16|16@1+ (1,0) [0|0] "" Vector__XXX
 SG_ AuxValve7RetractPortMeasuredFlow : 8|8@1+ (1,0) [0|0] "" Vector__XXX
 SG_ AuxValve7ExtendPortMeasuredFlow : 0|8@1+ (1,0) [0|0] "" Vector__XXX

BO_ 2566792958 AV06MF: 8 Vector__XXX
 SG_ AuxValve6ReturnPortPress : 48|8@1+ (1,0) [0|0] "" Vector__XXX
 SG_ AuxValve6RetractPortPress : 32|16@1+ (1,0) [0|0] "" Vector__XXX
 SG_ AuxValve6ExtendPortPress : 16|16@1+ (1,0) [0|0] "" Vector__XXX
 SG_ AuxValve6RetractPortMeasuredFlow : 8|8@1+ (1,0) [0|0] "" Vector__XXX
 SG_ AuxValve6ExtendPortMeasuredFlow : 0|8@1+ (1,0) [0|0] "" Vector__XXX

BO_ 2566792702 AV05MF: 8 Vector__XXX
 SG_ AuxValve5ReturnPortPress : 48|8@1+ (1,0) [0|0] "" Vector__XXX
 SG_ AuxValve5RetractPortPress : 32|16@1+ (1,0) [0|0] "" Vector__XXX
 SG_ AuxValve5ExtendPortPress : 16|16@1+ (1,0) [0|0] "" Vector__XXX
 SG_ AuxValve5RetractPortMeasuredFlow : 8|8@1+ (1,0) [0|0] "" Vector__XXX
 SG_ AuxValve5ExtendPortMeasuredFlow : 0|8@1+ (1,0) [0|0] "" Vector__XXX

BO_ 2566792446 AV04MF: 8 Vector__XXX
 SG_ AuxValve4ReturnPortPress : 48|8@1+ (1,0) [0|0] "" Vector__XXX
 SG_ AuxValve4RetractPortPress : 32|16@1+ (1,0) [0|0] "" Vector__XXX
 SG_ AuxValve4ExtendPortPress : 16|16@1+ (1,0) [0|0] "" Vector__XXX
 SG_ AuxValve4RetractPortMeasuredFlow : 8|8@1+ (1,0) [0|0] "" Vector__XXX
 SG_ AuxValve4ExtendPortMeasuredFlow : 0|8@1+ (1,0) [0|0] "" Vector__XXX

BO_ 2566792190 AV03MF: 8 Vector__XXX
 SG_ AuxValve3ReturnPortPress : 48|8@1+ (1,0) [0|0] "" Vector__XXX
 SG_ AuxValve3RetractPortPress : 32|16@1+ (1,0) [0|0] "" Vector__XXX
 SG_ AuxValve3ExtendPortPress : 16|16@1+ (1,0) [0|0] "" Vector__XXX
 SG_ AuxValve3RetractPortMeasuredFlow : 8|8@1+ (1,0) [0|0] "" Vector__XXX
 SG_ AuxValve3ExtendPortMeasuredFlow : 0|8@1+ (1,0) [0|0] "" Vector__XXX

BO_ 2566791934 AV02MF: 8 Vector__XXX
 SG_ AuxValve2ReturnPortPress : 48|8@1+ (1,0) [0|0] "" Vector__XXX
 SG_ AuxValve2RetractPortPress : 32|16@1+ (1,0) [0|0] "" Vector__XXX
 SG_ AuxValve2ExtendPortPress : 16|16@1+ (1,0) [0|0] "" Vector__XXX
 SG_ AuxValve2RetractPortMeasuredFlow : 8|8@1+ (1,0) [0|0] "" Vector__XXX
 SG_ AuxValve2ExtendPortMeasuredFlow : 0|8@1+ (1,0) [0|0] "" Vector__XXX

BO_ 2566791678 AV01MF: 8 Vector__XXX
 SG_ AuxValve1ReturnPortPress : 48|8@1+ (1,0) [0|0] "" Vector__XXX
 SG_ AuxValve1RetractPortPress : 32|16@1+ (1,0) [0|0] "" Vector__XXX
 SG_ AuxValve1ExtendPortPress : 16|16@1+ (1,0) [0|0] "" Vector__XXX
 SG_ AuxValve1RetractPortMeasuredFlow : 8|8@1+ (1,0) [0|0] "" Vector__XXX
 SG_ AuxValve1ExtendPortMeasuredFlow : 0|8@1+ (1,0) [0|0] "" Vector__XXX

BO_ 2566791422 AV00MF: 8 Vector__XXX
 SG_ AuxValve0ReturnPortPress : 48|8@1+ (1,0) [0|0] "" Vector__XXX
 SG_ AuxValve0RetractPortPress : 32|16@1+ (1,0) [0|0] "" Vector__XXX
 SG_ AuxValve0ExtendPortPress : 16|16@1+ (1,0) [0|0] "" Vector__XXX
 SG_ AuxValve0RetractPortMeasuredFlow : 8|8@1+ (1,0) [0|0] "" Vector__XXX
 SG_ AuxValve0ExtendPortMeasuredFlow : 0|8@1+ (1,0) [0|0] "" Vector__XXX

BO_ 2566791166 AV15EF: 8 Vector__XXX
 SG_ AuxValve15Exit_reasonCode : 32|6@1+ (1,0) [0|0] "" Vector__XXX
 SG_ AuxValve15FailSafeMode : 22|2@1+ (1,0) [0|0] "" Vector__XXX
 SG_ AuxValve15State : 16|4@1+ (1,0) [0|0] "" Vector__XXX
 SG_ AuxValve15RetractPortEstFlow : 8|8@1+ (1,0) [0|0] "" Vector__XXX
 SG_ AuxValve15ExtendPortEstFlow : 0|8@1+ (1,0) [0|0] "" Vector__XXX

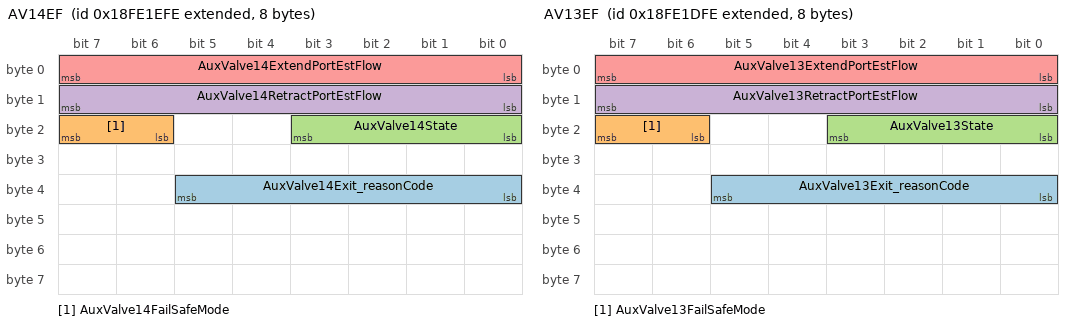
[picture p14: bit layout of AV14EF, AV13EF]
BO_ 2566790910 AV14EF: 8 Vector__XXX
 SG_ AuxValve14Exit_reasonCode : 32|6@1+ (1,0) [0|0] "" Vector__XXX
 SG_ AuxValve14FailSafeMode : 22|2@1+ (1,0) [0|0] "" Vector__XXX
 SG_ AuxValve14State : 16|4@1+ (1,0) [0|0] "" Vector__XXX
 SG_ AuxValve14RetractPortEstFlow : 8|8@1+ (1,0) [0|0] "" Vector__XXX
 SG_ AuxValve14ExtendPortEstFlow : 0|8@1+ (1,0) [0|0] "" Vector__XXX

BO_ 2566790654 AV13EF: 8 Vector__XXX
 SG_ AuxValve13Exit_reasonCode : 32|6@1+ (1,0) [0|0] "" Vector__XXX
 SG_ AuxValve13FailSafeMode : 22|2@1+ (1,0) [0|0] "" Vector__XXX
 SG_ AuxValve13State : 16|4@1+ (1,0) [0|0] "" Vector__XXX
 SG_ AuxValve13RetractPortEstFlow : 8|8@1+ (1,0) [0|0] "" Vector__XXX
 SG_ AuxValve13ExtendPortEstFlow : 0|8@1+ (1,0) [0|0] "" Vector__XXX

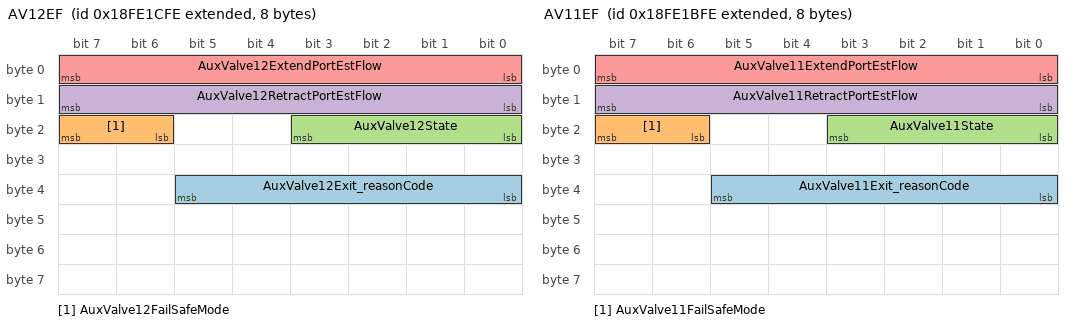
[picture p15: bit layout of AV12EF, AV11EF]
BO_ 2566790398 AV12EF: 8 Vector__XXX
 SG_ AuxValve12Exit_reasonCode : 32|6@1+ (1,0) [0|0] "" Vector__XXX
 SG_ AuxValve12FailSafeMode : 22|2@1+ (1,0) [0|0] "" Vector__XXX
 SG_ AuxValve12State : 16|4@1+ (1,0) [0|0] "" Vector__XXX
 SG_ AuxValve12RetractPortEstFlow : 8|8@1+ (1,0) [0|0] "" Vector__XXX
 SG_ AuxValve12ExtendPortEstFlow : 0|8@1+ (1,0) [0|0] "" Vector__XXX

BO_ 2566790142 AV11EF: 8 Vector__XXX
 SG_ AuxValve11Exit_reasonCode : 32|6@1+ (1,0) [0|0] "" Vector__XXX
 SG_ AuxValve11FailSafeMode : 22|2@1+ (1,0) [0|0] "" Vector__XXX
 SG_ AuxValve11State : 16|4@1+ (1,0) [0|0] "" Vector__XXX
 SG_ AuxValve11RetractPortEstFlow : 8|8@1+ (1,0) [0|0] "" Vector__XXX
 SG_ AuxValve11ExtendPortEstFlow : 0|8@1+ (1,0) [0|0] "" Vector__XXX

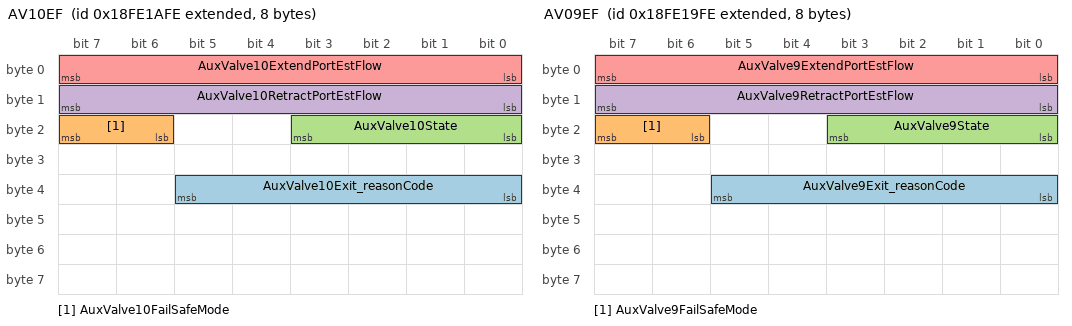
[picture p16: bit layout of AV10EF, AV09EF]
BO_ 2566789886 AV10EF: 8 Vector__XXX
 SG_ AuxValve10Exit_reasonCode : 32|6@1+ (1,0) [0|0] "" Vector__XXX
 SG_ AuxValve10FailSafeMode : 22|2@1+ (1,0) [0|0] "" Vector__XXX
 SG_ AuxValve10State : 16|4@1+ (1,0) [0|0] "" Vector__XXX
 SG_ AuxValve10RetractPortEstFlow : 8|8@1+ (1,0) [0|0] "" Vector__XXX
 SG_ AuxValve10ExtendPortEstFlow : 0|8@1+ (1,0) [0|0] "" Vector__XXX

BO_ 2566789630 AV09EF: 8 Vector__XXX
 SG_ AuxValve9Exit_reasonCode : 32|6@1+ (1,0) [0|0] "" Vector__XXX
 SG_ AuxValve9FailSafeMode : 22|2@1+ (1,0) [0|0] "" Vector__XXX
 SG_ AuxValve9State : 16|4@1+ (1,0) [0|0] "" Vector__XXX
 SG_ AuxValve9RetractPortEstFlow : 8|8@1+ (1,0) [0|0] "" Vector__XXX
 SG_ AuxValve9ExtendPortEstFlow : 0|8@1+ (1,0) [0|0] "" Vector__XXX

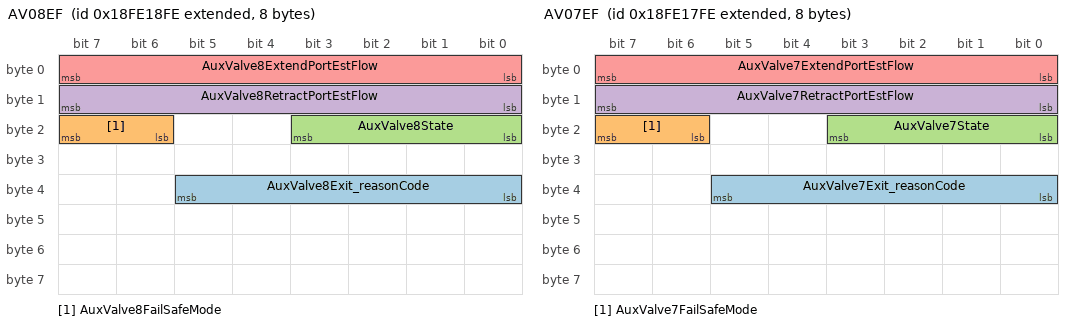
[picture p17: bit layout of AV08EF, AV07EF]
BO_ 2566789374 AV08EF: 8 Vector__XXX
 SG_ AuxValve8Exit_reasonCode : 32|6@1+ (1,0) [0|0] "" Vector__XXX
 SG_ AuxValve8FailSafeMode : 22|2@1+ (1,0) [0|0] "" Vector__XXX
 SG_ AuxValve8State : 16|4@1+ (1,0) [0|0] "" Vector__XXX
 SG_ AuxValve8RetractPortEstFlow : 8|8@1+ (1,0) [0|0] "" Vector__XXX
 SG_ AuxValve8ExtendPortEstFlow : 0|8@1+ (1,0) [0|0] "" Vector__XXX

BO_ 2566789118 AV07EF: 8 Vector__XXX
 SG_ AuxValve7Exit_reasonCode : 32|6@1+ (1,0) [0|0] "" Vector__XXX
 SG_ AuxValve7FailSafeMode : 22|2@1+ (1,0) [0|0] "" Vector__XXX
 SG_ AuxValve7State : 16|4@1+ (1,0) [0|0] "" Vector__XXX
 SG_ AuxValve7RetractPortEstFlow : 8|8@1+ (1,0) [0|0] "" Vector__XXX
 SG_ AuxValve7ExtendPortEstFlow : 0|8@1+ (1,0) [0|0] "" Vector__XXX

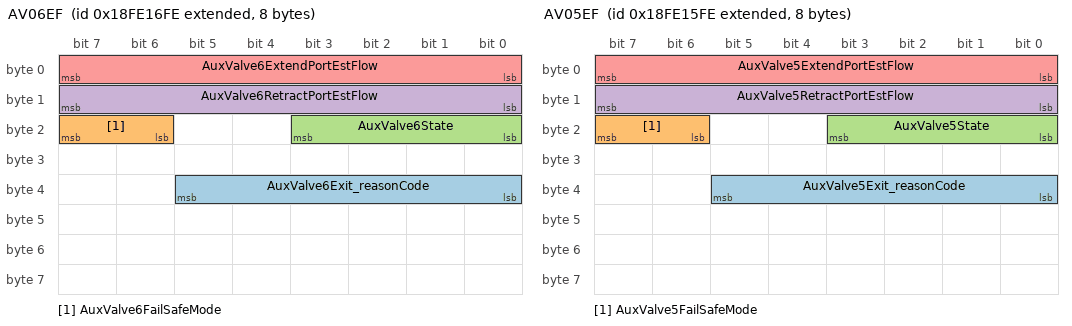
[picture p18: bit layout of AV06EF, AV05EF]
BO_ 2566788862 AV06EF: 8 Vector__XXX
 SG_ AuxValve6Exit_reasonCode : 32|6@1+ (1,0) [0|0] "" Vector__XXX
 SG_ AuxValve6FailSafeMode : 22|2@1+ (1,0) [0|0] "" Vector__XXX
 SG_ AuxValve6State : 16|4@1+ (1,0) [0|0] "" Vector__XXX
 SG_ AuxValve6RetractPortEstFlow : 8|8@1+ (1,0) [0|0] "" Vector__XXX
 SG_ AuxValve6ExtendPortEstFlow : 0|8@1+ (1,0) [0|0] "" Vector__XXX

BO_ 2566788606 AV05EF: 8 Vector__XXX
 SG_ AuxValve5Exit_reasonCode : 32|6@1+ (1,0) [0|0] "" Vector__XXX
 SG_ AuxValve5FailSafeMode : 22|2@1+ (1,0) [0|0] "" Vector__XXX
 SG_ AuxValve5State : 16|4@1+ (1,0) [0|0] "" Vector__XXX
 SG_ AuxValve5RetractPortEstFlow : 8|8@1+ (1,0) [0|0] "" Vector__XXX
 SG_ AuxValve5ExtendPortEstFlow : 0|8@1+ (1,0) [0|0] "" Vector__XXX

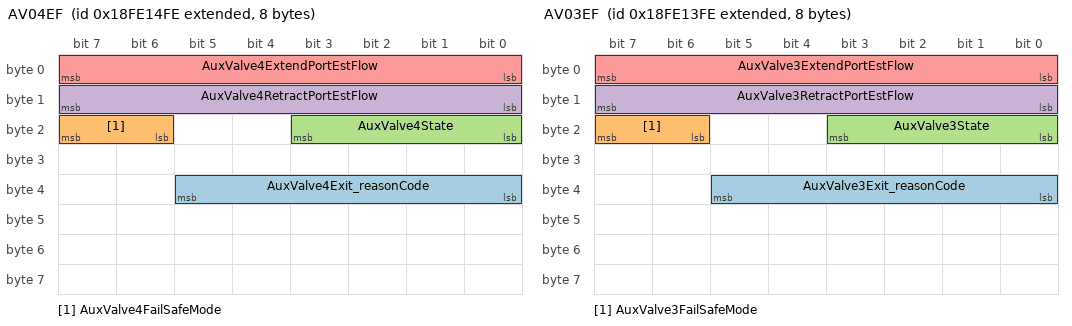
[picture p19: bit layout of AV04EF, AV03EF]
BO_ 2566788350 AV04EF: 8 Vector__XXX
 SG_ AuxValve4Exit_reasonCode : 32|6@1+ (1,0) [0|0] "" Vector__XXX
 SG_ AuxValve4FailSafeMode : 22|2@1+ (1,0) [0|0] "" Vector__XXX
 SG_ AuxValve4State : 16|4@1+ (1,0) [0|0] "" Vector__XXX
 SG_ AuxValve4RetractPortEstFlow : 8|8@1+ (1,0) [0|0] "" Vector__XXX
 SG_ AuxValve4ExtendPortEstFlow : 0|8@1+ (1,0) [0|0] "" Vector__XXX

BO_ 2566788094 AV03EF: 8 Vector__XXX
 SG_ AuxValve3Exit_reasonCode : 32|6@1+ (1,0) [0|0] "" Vector__XXX
 SG_ AuxValve3FailSafeMode : 22|2@1+ (1,0) [0|0] "" Vector__XXX
 SG_ AuxValve3State : 16|4@1+ (1,0) [0|0] "" Vector__XXX
 SG_ AuxValve3RetractPortEstFlow : 8|8@1+ (1,0) [0|0] "" Vector__XXX
 SG_ AuxValve3ExtendPortEstFlow : 0|8@1+ (1,0) [0|0] "" Vector__XXX

CM_ BO_ 2566663422 "Brake Caliper Lining Clearance
Refers to disc brake caliper lining clearance condition.";
CM_ SG_ 2566663422 TrlrBrkClprLnngClranceAxle5Right "Brake caliper lining clearance for right brake on trailer axle 5.

00 - Caliper lining clearance is adequate
01 - Caliper lining clearance is low
10 - Error
11 - Not available / not applicable";
CM_ SG_ 2566663422 TrlrBrkClprLnngClaranceAxle5Left "Brake caliper lining clearance for left brake on trailer axle 5.

00 - Caliper lining clearance is adequate
01 - Caliper lining clearance is low
10 - Error
11 - Not available / not applicable";
CM_ SG_ 2566663422 TrlrBrkClprLnngClranceAxle4Right "Brake caliper lining clearance for right brake on trailer axle 4.

00 - Caliper lining clearance is adequate
01 - Caliper lining clearance is low
10 - Error
11 - Not available / not applicable";
CM_ SG_ 2566663422 TrlrBrkClprLnngClaranceAxle4Left "Brake caliper lining clearance for left brake on trailer axle 4.

00 - Caliper lining clearance is adequate
01 - Caliper lining clearance is low
10 - Error
11 - Not available / not applicable";
CM_ SG_ 2566663422 TrlrBrkClprLnngClranceAxle3Right "Brake caliper lining clearance for right brake on trailer axle 3.

00 - Caliper lining clearance is adequate
01 - Caliper lining clearance is low
10 - Error
11 - Not available / not applicable";
CM_ SG_ 2566663422 TrlrBrkClprLnngClaranceAxle3Left "Brake caliper lining clearance for left brake on trailer axle 3.

00 - Caliper lining clearance is adequate
01 - Caliper lining clearance is low
10 - Error
11 - Not available / not applicable";
CM_ SG_ 2566663422 TrlrBrkClprLnngClranceAxle2Right "Brake caliper lining clearance for right brake on trailer axle 2.

00 - Caliper lining clearance is adequate
01 - Caliper lining clearance is low
10 - Error
11 - Not available / not applicable";
CM_ SG_ 2566663422 TrlrBrkClprLnngClaranceAxle2Left "Brake caliper lining clearance for left brake on trailer axle 2.

00 - Caliper lining clearance is adequate
01 - Caliper lining clearance is low
10 - Error
11 - Not available / not applicable";
CM_ SG_ 2566663422 TrlrBrkClprLnngClranceAxle1Right "Brake caliper lining clearance for right brake on trailer axle 1.

00 - Caliper lining clearance is adequate
01 - Caliper lining clearance is low
10 - Error
11 - Not available / not applicable";
CM_ SG_ 2566663422 TrlrBrkClprLnngClaranceAxle1Left "Brake caliper lining clearance for left brake on trailer axle 1.

00 - Caliper lining clearance is adequate
01 - Caliper lining clearance is low
10 - Error
11 - Not available / not applicable";
CM_ SG_ 2566663422 TrctrBrkClprLnngClrnceAxle5Right "Brake caliper lining clearance for right brake on tractor axle 5.

00 - Caliper lining clearance is adequate
01 - Caliper lining clearance is low
10 - Error
11 - Not available / not applicable";
CM_ SG_ 2566663422 TrctrBrkClprLnngClranceAxle5Left "Brake caliper lining clearance for left brake on tractor axle 5.

00 - Caliper lining clearance is adequate
01 - Caliper lining clearance is low
10 - Error
11 - Not available / not applicable";
CM_ SG_ 2566663422 TrctrBrkClprLnngClrnceAxle4Right "Brake caliper lining clearance for right brake on tractor axle 4.

00 - Caliper lining clearance is adequate
01 - Caliper lining clearance is low
10 - Error
11 - Not available / not applicable";
CM_ SG_ 2566663422 TrctrBrkClprLnngClranceAxle4Left "Brake caliper lining clearance for left brake on tractor axle 4.

00 - Caliper lining clearance is adequate
01 - Caliper lining clearance is low
10 - Error
11 - Not available / not applicable";
CM_ SG_ 2566663422 TrctrBrkClprLnngClrnceAxle3Right "Brake caliper lining clearance for right brake on tractor axle 3.

00 - Caliper lining clearance is adequate
01 - Caliper lining clearance is low
10 - Error
11 - Not available / not applicable";
CM_ SG_ 2566663422 TrctrBrkClprLnngClranceAxle3Left "Brake caliper lining clearance for left brake on tractor axle 3.

00 - Caliper lining clearance is adequate
01 - Caliper lining clearance is low
10 - Error
11 - Not available / not applicable";
CM_ SG_ 2566663422 TrctrBrkClprLnngClrnceAxle2Right "Brake caliper lining clearance for right brake on tractor axle 2.

00 - Caliper lining clearance is adequate
01 - Caliper lining clearance is low
10 - Error
11 - Not available / not applicable";
CM_ SG_ 2566663422 TrctrBrkClprLnngClranceAxle2Left "Brake caliper lining clearance for left brake on tractor axle 2.

00 - Caliper lining clearance is adequate
01 - Caliper lining clearance is low
10 - Error
11 - Not available / not applicable";
CM_ SG_ 2566663422 TrctrBrkClprLnngClrnceAxle1Right "Brake caliper lining clearance for right brake on tractor axle 1.

00 - Caliper lining clearance is adequate
01 - Caliper lining clearance is low
10 - Error
11 - Not available / not applicable";
CM_ SG_ 2566663422 TrctrBrkClprLnngClranceAxle1Left "Brake caliper lining clearance for left brake on tractor axle 1.

00 - Caliper lining clearance is adequate
01 - Caliper lining clearance is low
10 - Error
11 - Not available / not applicable";
CM_ BO_ 2566663166 "Cruise Control / Vehicle Speed 4
Cruise Control / Vehicle Speed 4";
CM_ SG_ 2566663166 CruiseCtrlAdjustedMaxSpeed "Present maximum vehicle velocity at which cruise can be set. This parameter is expected to change during run-time due to functionality that could influence the behavior of the cruise control algorithm. This functionality may include, but is not ...";
CM_ SG_ 2566663166 AppliedVehicleSpeedLimit "The vehicle speed limit in effect.

See SPN 2595 for alternate resolution.

Note:  If a maximum vehicle speed limit is not selected, then the first byte of this parameter will be equal to 0xFB.";
CM_ BO_ 2566662910 "Operator Inducement Information
Contains parameters related to operator inducement.";
CM_ SG_ 2566662910 TimeToFinalIndAction "Indicates the time until the inducement strategy enforces the final level of engine emissions operator inducement. The final level of inducement can include derating the engine, shutting down the engine, or restricting the engine to low idle.
See ...";
CM_ SG_ 2566662910 OprtrIndcmntTmTTrqueDerateLevel2 "This parameter provides the time until Operator Inducement Torque Derate Level 2 (SPN 7427) is activated.
When operator inducement is not active (SPN 5826 is 000), this parameter will be set to 0xFB00.  If this parameter decrements to 0, it will ...";
CM_ SG_ 2566662910 OprtrIndcementTorqueDerateLevel2 "The next torque derate that will be applied to the engine operation due to operator inducement after the torque derate specified in Operator Inducement Torque Derate Level 1 (SPN 7425) becomes active.
This parameter is a percentage of how much the ...";
CM_ SG_ 2566662910 OprtrIndcmntTmTTrqueDerateLevel1 "This parameter provides the time until Operator Inducement Torque Derate Level 1 (SPN 7425) is activated.
When operator inducement is not active (SPN 5826 is 000), this parameter will be set to 0xFB00.  If this parameter decrements to 0, it will ...";
CM_ SG_ 2566662910 OprtrIndcementTorqueDerateLevel1 "This is the first torque derate that will be applied to the engine operation due to operator inducement.  The torque derate indicated in this parameter will be applied when the value in Operator Inducement Time to Torque Derate Level 1 (SPN 7426) ...";
CM_ BO_ 2566662654 "Forward Lane Image 3
Forward Lane Image message 3 for computing results outside the optical sensor (e.g., data fusion)";
CM_ SG_ 2566662654 LaneMarkQualityOnTheRightSide "The quality of the nearest lane mark on the right side of the vehicle.
000 = no lane marks detected
001 = low reliablity of detected lane marks
010 = good reliablity of detected lane marks
011 = perfect recognition of lane marks
100 - 101 = ...";
CM_ SG_ 2566662654 LaneMarkQualityOnTheLeftSide "The quality of the nearest lane mark on the left side of the vehicle.
000 = no lane marks detected
001 = low reliablity of detected lane marks
010 = good reliablity of detected lane marks
011 = perfect recognition of lane marks
100 - 101 = ...";
CM_ SG_ 2566662654 LaneDepartureAngleRight "Angle between right lane mark and vehicle driving direction. The angle is positive while vehicle is moving towards the lane marks, and negative if not. Measured values outside the limits are represented by signal value 251.
Parameter specific ...";
CM_ SG_ 2566662654 LaneDepartureAngleLeft "Angle between left lane mark and vehicle driving direction. The angle is positive while vehicle is moving towards the lane marks, and negative if not. Measured values outside the limits are represented by signal value 251.
Parameter specific values ...";
CM_ SG_ 2566662654 RoadCurvatureBasedOnLaneMarks "The road curvature parameter is based on lane marks as measured by the FLI.  It is the mean value of the road curvature of the lane marks on the left and right side of the lane. In case one of the lane mark is not recognized anymore, the value is ...";
CM_ SG_ 2566662654 RghtDstncTLnMrkFrmVehiclesMiddle "Distance between middle of the vehicle front and the inner/left edge of the nearest lane mark on the right side as measured from the Forward Lane Imager. The value represents the lane width at camera position. Measured values greater than 5 m ...";
CM_ SG_ 2566662654 LftDstncTLnMrkFromVehiclesMiddle "Distance between middle of the vehicle front and the inner/right edge of the nearest lane mark on the left side as measured from the Forward Lane Imager. The value represents the lane width at camera position. Measured values greater than 5 m ...";
CM_ BO_ 2566662142 "Aftertreatment 1 Diesel Exhaust Fluid Information 2
Sensor Information which measures temperature, concentration, and conductivity of the diesel exhaust fluid of the aftertreatment 1 system.";
CM_ SG_ 2566662142 Ctrl2Temp "Temperature of the diesel exhaust fluid at the aftertreatment 1 diesel exhaust fluid controller 2.";
CM_ SG_ 2566662142 Ctrl1Temp "Temperature of the diesel exhaust fluid at the aftertreatment 1 diesel exhaust fluid controller.
For controllers that have more exhaust emissions control functions than only diesel exhaust fluid control, see SPN 5486 - exhaust emission control ECU ...";
CM_ BO_ 2566661630 "Aftertreatment 1 Diesel Exhaust Fluid Tank 1 Information 2
Contains information on various tank levels";
CM_ SG_ 2566661630 Htr2 "Percentage of heating applied to the second diesel exhaust fluid tank heater on aftertreatment 1. A value of 0% means no heating applied, a value of 100% means full heating applied. The diesel exhaust fluid tank heater warms the diesel exhaust fluid ...";
CM_ SG_ 2566661630 Temp2 "The second temperature of aftertreatment 1 diesel exhaust fluid in the storage tank.";
CM_ SG_ 2566661630 Volume2 "Second measurement of the ratio of volume of diesel exhaust fluid to the total volume of the diesel exhaust fluid storage container for aftertreatment system 1 (exhaust bank 1).  0% is empty and 100% is full.  See SPN 1761 and SPN 3517 for alternate ...";
CM_ BO_ 2566661374 "Aftertreatment 2 Diesel Exhaust Fluid Tank 1 Information 2
This message contains diesel exhaust fluid tank 1 information for aftertreatment system 2 (or bank 2).  The first tank for the aftertreatment sytem is primary reagent storage tank.";
CM_ SG_ 2566661374 Ctrl2Temp "Temperature of the diesel exhaust fluid at the aftertreatment 2 diesel exhaust fluid controller 2.";
CM_ SG_ 2566661374 CtrlTemp "Temperature of the diesel exhaust fluid at the aftertreatment 2 diesel exhaust fluid controller.";
CM_ SG_ 2566661374 Htr2 "Percentage of heating applied to the second diesel exhaust fluid tank heater on aftertreatment 2. A value of 0% means no heating applied, a value of 100% means full heating applied. The diesel exhaust fluid tank heater warms the diesel exhaust fluid ...";
CM_ SG_ 2566661374 Temp2 "The second temperature of aftertreatment 2 diesel exhaust fluid in the storage tank.";
CM_ SG_ 2566661374 Volume2 "Second measurement of the ratio of volume of diesel exhaust fluid to the total volume of the diesel exhaust fluid storage container for aftertreatment system 2 (exhaust bank 2).  0% is empty and 100% is full.  See SPN 4426 and SPN 4428 for alternate ...";
CM_ BO_ 2364598270 "Engine Ignition Timing Offset 3
This PGN contains timing offsets for cylinders 17-24.

These timing offsets are relative to the commanded engine timing advance (SPN 7355).";
CM_ SG_ 2364598270 EngCyl24TimingOffset "The ignition timing offset for Cylinder 24 from the engine timing advance (SPN 7355) as a command to the ignition control module. Positive values command an increasingly advanced timing.";
CM_ SG_ 2364598270 EngCyl23TimingOffset "The ignition timing offset for Cylinder 23 from the engine timing advance (SPN 7355) as a command to the ignition control module. Positive values command an increasingly advanced timing.";
CM_ SG_ 2364598270 EngCyl22TimingOffset "The ignition timing offset for Cylinder 22 from the engine timing advance (SPN 7355) as a command to the ignition control module. Positive values command an increasingly advanced timing.";
CM_ SG_ 2364598270 EngCyl21TimingOffset "The ignition timing offset for Cylinder 21 from the engine timing advance (SPN 7355) as a command to the ignition control module. Positive values command an increasingly advanced timing.";
CM_ SG_ 2364598270 EngCyl20TimingOffset "The ignition timing offset for Cylinder 20 from the engine timing advance (SPN 7355) as a command to the ignition control module. Positive values command an increasingly advanced timing.";
CM_ SG_ 2364598270 EngCyl19TimingOffset "The ignition timing offset for Cylinder 19 from the engine timing advance (SPN 7355) as a command to the ignition control module. Positive values command an increasingly advanced timing.";
CM_ SG_ 2364598270 EngCyl18TimingOffset "The ignition timing offset for Cylinder 18 from the engine timing advance (SPN 7355) as a command to the ignition control module. Positive values command an increasingly advanced timing.";
CM_ SG_ 2364598270 EngCyl17TimingOffset "The ignition timing offset for Cylinder 17 from the engine timing advance (SPN 7355) as a command to the ignition control module. Positive values command an increasingly advanced timing.";
CM_ BO_ 2364598014 "Engine Ignition Timing Offset 2
This PGN contains timing offsets for cylinders 9-16.

These timing offsets are relative to the commanded engine timing advance (SPN 7355).";
CM_ SG_ 2364598014 EngCyl16TimingOffset "The ignition timing offset for Cylinder 16 from the engine timing advance (SPN 7355) as a command to the ignition control module. Positive values command an increasingly advanced timing.";
CM_ SG_ 2364598014 EngCyl15TimingOffset "The ignition timing offset for Cylinder 15 from the engine timing advance (SPN 7355) as a command to the ignition control module. Positive values command an increasingly advanced timing.";
CM_ SG_ 2364598014 EngCyl14TimingOffset "The ignition timing offset for Cylinder 14 from the engine timing advance (SPN 7355) as a command to the ignition control module. Positive values command an increasingly advanced timing.";
CM_ SG_ 2364598014 EngCyl13TimingOffset "The ignition timing offset for Cylinder 13 from the engine timing advance (SPN 7355) as a command to the ignition control module. Positive values command an increasingly advanced timing.";
CM_ SG_ 2364598014 EngCyl12TimingOffset "The ignition timing offset for Cylinder 12 from the engine timing advance (SPN 7355) as a command to the ignition control module. Positive values command an increasingly advanced timing.";
CM_ SG_ 2364598014 EngCyl11TimingOffset "The ignition timing offset for Cylinder 11 from the engine timing advance (SPN 7355) as a command to the ignition control module. Positive values command an increasingly advanced timing.";
CM_ SG_ 2364598014 EngCyl10TimingOffset "The ignition timing offset for Cylinder 10 from the engine timing advance (SPN 7355) as a command to the ignition control module. Positive values command an increasingly advanced timing.";
CM_ SG_ 2364598014 EngCyl9TimingOffset "The ignition timing offset for Cylinder 9 from the engine timing advance (SPN 7355) as a command to the ignition control module. Positive values command an increasingly advanced timing.";
CM_ BO_ 2364597758 "Engine Ignition Timing Offset 1
This PGN contains timing offsets for cylinders 1-8.

These timing offsets are relative to the commanded engine timing advance (SPN 7355).";
CM_ SG_ 2364597758 EngCyl8TimingOffset "The ignition timing offset for Cylinder 8 from the engine timing advance (SPN 7355) as a command to the ignition control module. Positive values command an increasingly advanced timing.";
CM_ SG_ 2364597758 EngCyl7TimingOffset "The ignition timing offset for Cylinder 7 from the engine timing advance (SPN 7355) as a command to the ignition control module. Positive values command an increasingly advanced timing.";
CM_ SG_ 2364597758 EngCyl6TimingOffset "The ignition timing offset for Cylinder 6 from the engine timing advance (SPN 7355) as a command to the ignition control module. Positive values command an increasingly advanced timing.";
CM_ SG_ 2364597758 EngCyl5TimingOffset "The ignition timing offset for Cylinder 5 from the engine timing advance (SPN 7355) as a command to the ignition control module. Positive values command an increasingly advanced timing.";
CM_ SG_ 2364597758 EngCyl4TimingOffset "The ignition timing offset for Cylinder 4 from the engine timing advance (SPN 7355) as a command to the ignition control module. Positive values command an increasingly advanced timing.";
CM_ SG_ 2364597758 EngCyl3TimingOffset "The ignition timing offset for Cylinder 3 from the engine timing advance (SPN 7355) as a command to the ignition control module. Positive values command an increasingly advanced timing.";
CM_ SG_ 2364597758 EngCyl2TimingOffset "The ignition timing offset for Cylinder 2 from the engine timing advance (SPN 7355) as a command to the ignition control module. Positive values command an increasingly advanced timing.";
CM_ SG_ 2364597758 EngCyl1TimingOffset "The ignition timing offset for Cylinder 1 from the engine timing advance (SPN 7355) as a command to the ignition control module. Positive values command an increasingly advanced timing.";
CM_ BO_ 2364593150 "Predictive Cruise Control 1
Contains parameters related to predictive cruise control. Predictive cruise control is the process of varying the set point used by the cruise control algorithm based on external factors (e.g., anticipated road grade).";
CM_ SG_ 2364593150 PrdctvCrsCtrlDrvlnDsnggInhibitRq "Request to temporarily inhibit a fuel saving feature that would normally open the driveline. Under certain conditions and with knowledge of the terrain, inhibiting this feature may improve fuel economy.
SPN 683 Disengage Driveline Request has ...";
CM_ SG_ 2364593150 VhclSpdCtrlOvrrideEventIndicator "Indicates to the operator that a Speed Control override event is active.  'Speed Control' refers to retarders or methods of automatically limiting vehicle speed, for instance on downhill grades.  An active event indicates that vehicle speed may ...";
CM_ SG_ 2364593150 PrdctvCrsCtrlSpeedEventIndicator "Indicates to the operator that a predictive cruise control (PCC) speed event is active. Typically, this will correspond to a Predictive Cruise Control Set Speed Offset (SPN 7316) request to increase or decrease vehicle speed from the nominal cruise ...";
CM_ SG_ 2364593150 PredictiveCruiseCtrlNextGrade "Road grade at next predictive cruise control (PCC) event. Positive numbers indicate uphill grade, negative are downhill for vehicle direction of travel. For grades beyond the limits of the parameter, the limit value shall be reported.";
CM_ SG_ 2364593150 PredictiveCruiseCtrlPresentGrade "Road grade at present vehicle position. Positive numbers indicate uphill grade, negative are downhill for present vehicle direction of travel. For grades beyond the limits of the parameter, the limit value shall be reported.";
CM_ SG_ 2364593150 PredictiveCruiseCtrlEventInRange "Indicates that an event, such as a grade, is detected within the range of the predictive cruise control (PCC) look-ahead distance.
00 - No PCC event in range
01 - PCC event in range
10 - Error
11 - Not available
Note:  Intended to be sent ...";
CM_ SG_ 2364593150 VehicleSpeedCtrlOverrideRq "Speed control override requested. Indicates that the minimum restriction of speed is desired, for instance when travelling downhill towards an impending uphill grade. This is not a request to inhibit engine brakes (or other speed limiting device) ...";
CM_ SG_ 2364593150 PredictiveCruiseCtrlState "Indicates the state of the PCC controller.
If this parameter is 0001, the cruise control set point may be modified by the Predictive Cruise Control Set Speed Offset (SPN 7316) . For states other than 0001, the value in Predictive Cruise Control Set ...";
CM_ SG_ 2364593150 PrdctiveCruiseCtrlSetSpeedOffset "The amount by which the actual set point used by the cruise control algorithm should be changed as determined by external factors (e.g., anticipated road grade).
If SPN 7317 indicates Enabled (0001b) and if the cruise control algorithm determines ...";
CM_ BO_ 2364592894 "Engine Electronic Controller 18
Transmits command information for the actuators associated with engine.";
CM_ SG_ 2364592894 InAirSourceVlv "Status of the actuator/valve in the airbox used to source engine intake air from either the engine compartment or external to the vehicle.

00 - Off
01 - On
10 - Error
11 - Not available";
CM_ SG_ 2364592894 EngCylHeadBypassActuator1Cmd "Command to cylinder head bypass actuator 1, normalized to percent, where 0% nominally represents fully closed (No Flow) and 100% represents fully open (Max Flow). The purpose of the cylinder bypass valve is to release the air at the high pressure ...";
CM_ BO_ 2364592638 "Engine Cylinder Head Bypass Actuator 1
Transmits information about Engine Cylinder Head Bypass Actuator. The cylinder head bypass
valve is used to release the air at the high pressure compressor outlet into turbocharger turbine inlet
when intake ...";
CM_ SG_ 2364592638 EngCylHdBypssActtr1OprtionStatus "Identifies the status of Engine Cylinder Head Bypass Actuator 1.
Cylinder head bypass valve is used to release the air at the high pressure compressor outlet into turbocharger turbine inlet when intake pressure exceeds exhaust pressure at lower ...";
CM_ SG_ 2364592638 EngCylHeadBypassActuator1Pos "Actual position of Engine Cylinder Head Bypass actuator, where 0% represents fully closed and 100% represents fully open.
Cylinder Head bypass valve is used to release the air at the high pressure compressor outlet into turbocharger turbine inlet ...";
CM_ SG_ 2364592638 EngCylHdBypssActuator1DesiredPos "Requested position of Engine Cylinder Head Bypass actuator by engine ECM, where 0% represents bypass fully closed and 100% represents fully open. This is the position that the device is attempting to achieve.
Cylinder Head bypass valve is used to ...";
CM_ SG_ 2364592638 EngCylHeadBypassActuator1Temp "Temperature of the Engine Cylinder Head Bypass Actuator 1 drive circuitry. Temperature excursions may affect the torque output.
Cylinder Head bypass valve is used to release the air at the high pressure compressor outlet into turbocharger turbine ...";
CM_ SG_ 2364592638 EngCylHdBypssActuator1TempStatus "Identifies the status of the Engine Cylinder Head Bypass Blowoff Actuator 1 drive circuitry temperature. Temperature excursions may affect the torque output.
Cylinder Head bypass valve is used to release the air at the high pressure compressor ...";
CM_ SG_ 2364592638 EngCylHdBypssActtr1PrliminaryFMI "Identifies the applicable J1939-73 FMI detected in Engine Cylinder Head Bypass Actuator 1 by the manufacturer's software. When there is no failure FMI 31 is transmitted. When there are multiple failures, the most severe is transmitted.
Cylinder ...";
CM_ BO_ 2364592382 "Engine Cylinder Combustion Request
Transmits combustion related requests";
CM_ SG_ 2364592382 EngCyl24ExcludeFromCombustionRq "Request to the engine ECU to exclude (skip or cut-out) cylinder 24 from combustion.

00 Exclude from Combustion
01 Include for Combustion
10 Reserved
11 Not available/Do not care";
CM_ SG_ 2364592382 EngCyl23ExcludeFromCombustionRq "Request to the engine ECU to exclude (skip or cut-out) cylinder 23 from combustion.

00 Exclude from Combustion
01 Include for Combustion
10 Reserved
11 Not available/Do not care";
CM_ SG_ 2364592382 EngCyl22ExcludeFromCombustionRq "Request to the engine ECU to exclude (skip or cut-out) cylinder 22 from combustion.

00 Exclude from Combustion
01 Include for Combustion
10 Reserved
11 Not available/Do not care";
CM_ SG_ 2364592382 EngCyl21ExcludeFromCombustionRq "Request to the engine ECU to exclude (skip or cut-out) cylinder 21 from combustion.

00 Exclude from Combustion
01 Include for Combustion
10 Reserved
11 Not available/Do not care";
CM_ SG_ 2364592382 EngCyl20ExcludeFromCombustionRq "Request to the engine ECU to exclude (skip or cut-out) cylinder 20 from combustion.

00 Exclude from Combustion
01 Include for Combustion
10 Reserved
11 Not available/Do not care";
CM_ SG_ 2364592382 EngCyl19ExcludeFromCombustionRq "Request to the engine ECU to exclude (skip or cut-out) cylinder 19 from combustion.

00 Exclude from Combustion
01 Include for Combustion
10 Reserved
11 Not available/Do not care";
CM_ SG_ 2364592382 EngCyl18ExcludeFromCombustionRq "Request to the engine ECU to exclude (skip or cut-out) cylinder 18 from combustion.

00 Exclude from Combustion
01 Include for Combustion
10 Reserved
11 Not available/Do not care";
CM_ SG_ 2364592382 EngCyl17ExcludeFromCombustionRq "Request to the engine ECU to exclude (skip or cut-out) cylinder 17 from combustion.

00 Exclude from Combustion
01 Include for Combustion
10 Reserved
11 Not available/Do not care";
CM_ SG_ 2364592382 EngCyl16ExcludeFromCombustionRq "Request to the engine ECU to exclude (skip or cut-out) cylinder 16 from combustion.

00 Exclude from Combustion
01 Include for Combustion
10 Reserved
11 Not available/Do not care";
CM_ SG_ 2364592382 EngCyl15ExcludeFromCombustionRq "Request to the engine ECU to exclude (skip or cut-out) cylinder 15 from combustion.

00 Exclude from Combustion
01 Include for Combustion
10 Reserved
11 Not available/Do not care";
CM_ SG_ 2364592382 EngCyl14ExcludeFromCombustionRq "Request to the engine ECU to exclude (skip or cut-out) cylinder 14 from combustion.

00 Exclude from Combustion
01 Include for Combustion
10 Reserved
11 Not available/Do not care";
CM_ SG_ 2364592382 EngCyl13ExcludeFromCombustionRq "Request to the engine ECU to exclude (skip or cut-out) cylinder 13 from combustion.

00 Exclude from Combustion
01 Include for Combustion
10 Reserved
11 Not available/Do not care";
CM_ SG_ 2364592382 EngCyl12ExcludeFromCombustionRq "Request to the engine ECU to exclude (skip or cut-out) cylinder 12 from combustion.

00 Exclude from Combustion
01 Include for Combustion
10 Reserved
11 Not available/Do not care";
CM_ SG_ 2364592382 EngCyl11ExcludeFromCombustionRq "Request to the engine ECU to exclude (skip or cut-out) cylinder 11 from combustion.

00 Exclude from Combustion
01 Include for Combustion
10 Reserved
11 Not available/Do not care";
CM_ SG_ 2364592382 EngCyl10ExcludeFromCombustionRq "Request to the engine ECU to exclude (skip or cut-out) cylinder 10 from combustion.

00 Exclude from Combustion
01 Include for Combustion
10 Reserved
11 Not available/Do not care";
CM_ SG_ 2364592382 EngCyl9ExcludeFromCombustionRq "Request to the engine ECU to exclude (skip or cut-out) cylinder 9 from combustion.

00 Exclude from Combustion
01 Include for Combustion
10 Reserved
11 Not available/Do not care";
CM_ SG_ 2364592382 EngCyl8ExcludeFromCombustionRq "Request to the engine ECU to exclude (skip or cut-out) cylinder 8 from combustion.

00 Exclude from Combustion
01 Include for Combustion
10 Reserved
11 Not available/Do not care";
CM_ SG_ 2364592382 EngCyl7ExcludeFromCombustionRq "Request to the engine ECU to exclude (skip or cut-out) cylinder 7 from combustion.

00 Exclude from Combustion
01 Include for Combustion
10 Reserved
11 Not available/Do not care";
CM_ SG_ 2364592382 EngCyl6ExcludeFromCombustionRq "Request to the engine ECU to exclude (skip or cut-out) cylinder 6 from combustion.

00 Exclude from Combustion
01 Include for Combustion
10 Reserved
11 Not available/Do not care";
CM_ SG_ 2364592382 EngCyl5ExcludeFromCombustionRq "Request to the engine ECU to exclude (skip or cut-out) cylinder 5 from combustion.

00 Exclude from Combustion
01 Include for Combustion
10 Reserved
11 Not available/Do not care";
CM_ SG_ 2364592382 EngCyl4ExcludeFromCombustionRq "Request to the engine ECU to exclude (skip or cut-out) cylinder 4 from combustion.

00 Exclude from Combustion
01 Include for Combustion
10 Reserved
11 Not available/Do not care";
CM_ SG_ 2364592382 EngCyl3ExcludeFromCombustionRq "Request to the engine ECU to exclude (skip or cut-out) cylinder 3 from combustion.

00 Exclude from Combustion
01 Include for Combustion
10 Reserved
11 Not available/Do not care";
CM_ SG_ 2364592382 EngCyl2ExcludeFromCombustionRq "Request to the engine ECU to exclude (skip or cut-out) cylinder 2 from combustion.

00 Exclude from Combustion
01 Include for Combustion
10 Reserved
11 Not available/Do not care";
CM_ SG_ 2364592382 EngCyl1ExcludeFromCombustionRq "Request to the engine ECU to exclude (skip or cut-out) cylinder 1 from combustion.

00 Exclude from Combustion
01 Include for Combustion
10 Reserved
11 Not available/Do not care";
CM_ SG_ 2364592382 NmbrOfEngCylndrsTExcldFrmCmbston "Request to the engine ECU for the number of cylinders to exclude from combustion (cut-out or skip) for a given instance in time.  The engine ECU can decide on the cylinders to exclude from combustion.  One of the use cases would be sending this ...";
CM_ BO_ 2364567294 "Fuel Pump Actuator Control Command
Used to transmit the commanded % position for the Fuel Pump control valve.";
CM_ SG_ 2364567294 EngFlInjctnPump2FuelCtrlValveCmd "The control command to fuel control valve in fuel pump 2, normalized to percent, where 0% represents fully closed and 100% represents fully open.";
CM_ SG_ 2364567294 EngFlInjctnPump1FuelCtrlValveCmd "The control command to fuel control valve in fuel pump 1, normalized to percent, where 0% represents fully closed and 100% represents fully open.";
CM_ BO_ 2558918398 "Cab Message 2
Message containing parameters originating from the vehicle cab.";
CM_ SG_ 2558918398 TransAutoNeutralEnableSw "This enable switch is for optional use with interfaces using SPN 7695 [Transmission Auto-Neutral (Manual Return) Request] or another vehicle input configured for Auto-Neutral (Manual Return) functionality. When supported by the vehicle system and ...";
CM_ SG_ 2558918398 AFTRegenEngSpdAllowedSw "If this parameter is 01, then the aftertreatment control system is permitted to perform an aftertreatment regeneration, but the aftertreatment control system is not allowed to take control of the engine speed for the purposes of regeneration. A ...";
CM_ SG_ 2558918398 ElevatedEngSpdAllowedSw "Indicates the state of a switch to indicate the control system is permitted to automatically elevate the engine speed as needed for strategies such as cold mode, aftertreatment regeneration, etc. This is not a direct command to increase the engine ...";
CM_ SG_ 2558918398 PrdctvCriseCtrlMaxNegativeOffset "Maximum speed decrease that the predictive cruise control (PCC) is allowed to request. This may be adjusted by the operator (either directly or indirectly) to tailor the performance of the PCC system.
This parameter is used in conjunction with ...";
CM_ SG_ 2558918398 PrdctvCriseCtrlMaxPositiveOffset "Maximum speed increase that the predictive cruise control (PCC) is allowed to request. This may be adjusted by the operator (either directly or indirectly) to tailor the performance of the PCC system.
This parameter is used in conjunction with ...";
CM_ SG_ 2558918398 PrdctiveCruiseCtrlDeactivationRq "Indicates that the operator has requested to deactivate the predictive cruise control (PCC) function.
If enabled, the PCC device may still provide notification of events in range, road grade, and other information. But if requested to be ...";
CM_ SG_ 2558918398 PredictiveCruiseCtrlEnableSwitch "Indicates whether predictive cruise control (PCC) is enabled. When not enabled, the predictive cruise control does not calculate a speed offset or identify predictive cruise events, and the predictive cruise control state (SPN 7317) shall not be ...";
CM_ SG_ 2558918398 HtExchngerDebrisPurgeForceSwitch "Indicates the state of a switch available to the operator that forces the system to purge the debris from the heat exchanger.
00   not active
01   active
10   error
11   not available
This SPN would be 'not active' when purging the debris from ...";
CM_ SG_ 2558918398 HtExchngrDbrisPurgeInhibitSwitch "Indicates the state of a switch available to the operator that will inhibit the system from purging the debris from the heat exchanger.
00   not active
01   active
10   error
11   not available
This SPN would be 'not active' when purging the ...";
CM_ SG_ 2558918398 SCROprtrInducementOverrideSwitch "The position of the operator inducement override switch. This switch function allows the operator to override an operator inducement derate.
See EU Commission directive 2012/46/EU. Appendix 1 Section 5.5 for more information.
00 Off
01 On
10 ...";
CM_ SG_ 2558918398 PerformanceBiasSelection "Indicates the operating bias toward performance of the power source.
0% Functionality is biased toward fuel economy as much as possible.
50% Functionality is biased toward neither fuel economy or performance.
100% Functionality is biased toward ...";
CM_ SG_ 2558918398 EngFan2RequestedPercentSpeed "Fan speed of the second fan in the system as a ratio of the actual fan drive (current speed) to the fully engaged fan drive (maximum fan speed). A two state fan (off/on) will use 0% and 100% respectively.  A three state fan (off/intermediate/on) ...";
CM_ BO_ 2558852862 "Aftertreatment 1 Particulate Sensor Control
This PGN contains parameters used to control the particulate sensor and to provide data that the particulate sensor needs to operate.";
CM_ SG_ 2558852862 ExhVelocity "Velocity of the exhaust gas near the particulate sensor.";
CM_ SG_ 2558852862 ExhTemp "This is the temperature in the exhaust stream that is closest to the particulate sensor. This could be a calculated value or read from another sensor. The ECU transmitting this message to the particulate sensor controller will be aware of the ...";
CM_ SG_ 2558852862 Dewpoint "Indicates that the temperature near the particulate sensor has exceeded the dew point.

00 - Dewpoint has not been reached
01 - Dewpoint has been reached
10 - SAE reserved
11 - Not available";
CM_ SG_ 2558852862 RegenReq "Another ECU would send this to request that the particulate sensor perform a regeneration of the sensor.  A request would be considered active when this parameter transitions from 00 to 01.
00 - Regeneration not requested
01 - Regeneration ...";
CM_ SG_ 2558852862 ShutdownReq "Aftertreatment 1 particulate sensor shutdown request.

00 - Shutdown request not active
01 - Shutdown request active
10 - SAE reserved
11 - Not available";
CM_ BO_ 2558787326 "Payload Calibration Information Command
Calibration setting commands for the Payload Measurement System.";
CM_ SG_ 2558787326 PayloadCorrectionFactorCmd "The payload correction factor is used to fine tune the sensor gain value.
Correction factor calibration of the Payload Measurement system is performed through a Payload Calibration Set Point SPN value of Correction Point and the Payload Correction ...";
CM_ SG_ 2558787326 PayloadCalibCommandedWeight "The true known mass of real load weight applicable for the calibration point specified in SPN 6871 and used for calibrating Payload system.
Multipoint calibration of the Payload Measurement system is perfomed by loading the machine with up to 10 ...";
CM_ SG_ 2558787326 PayloadCalibSetPointCmd "Specifies the current payload point being calibrated. The data specified in the 'Payload Calibration Commanded Weight' SPN (SPN 6872) or 'Payload Correction Factor Command' SPN (SPN 6873) shall be used for calibrating this specified payload point ...";
CM_ BO_ 2558721790 "Tire Configuration Command Information
Details the attributes for the tire monitoring settings for the tires.";
CM_ SG_ 2558721790 SnsrEnableSetting "Command signal used to enable/disable the tire sensor. On receipt of this command, the tire sensor may either be enabled or disabled.

00 Off / Isolate / Disable
01 On / Enable
10 Reserved / Not Defined
11 Don't Care / Take No Action";
CM_ SG_ 2558721790 OverTempSetting "Configurable constant temperature above which an over temperature alert will trigger.";
CM_ SG_ 2558721790 OvrPrssPrcentageThresholdSetting "Configurable percentage deviation from the set cold inflation pressure, for the over tire pressure alert.";
CM_ SG_ 2558721790 ExtrmUndrPrssPrcntgThrshldStting "Configurable percent deviation from the set cold inflation pressure, for the extreme under tire pressure alert.";
CM_ SG_ 2558721790 UndrPrssPrcntageThresholdSetting "Configurable percent deviation from the set cold inflation pressure, for the under tire pressure alert.";
CM_ SG_ 2558721790 ColdInflationPressSetting "Configurable value of the cold inflation pressure of the tire. Cold inflation pressure is the default/reference inflation pressure suggested by the manufacturer for a specific tire.";
CM_ SG_ 2558721790 TireLocation "The location of monitored tire on the vehicle.
The high order 4 bits indicate the vehicle axle position of the tire, counting front to back on the vehicle, with the value 0 representing the front axle on the vehicle. If the upper 4 bits have a ...";
CM_ BO_ 2558656254 "Aftertreatment System Control
Used to request the aftertreatment system to perform or inhibit certain operations.";
CM_ SG_ 2558656254 RqToPermitDEFDosingTestInjection "A request to permit the DEF dosing test injection. The request continues to be broadcast until the test injection is finished or the corresponding permission status indicates an error.
000 = no request
001 = request to permit DEF Dosing Test ...";
CM_ SG_ 2558656254 RqToPermitDEFHydStiffnessCheck "A request to permit the DEF hydraulic stiffness check. The request continues to be broadcast until the stiffness check is finished or the corresponding permission status indicates an error.
00 = no request
01 = request to permit DEF hydraulic ...";
CM_ SG_ 2558656254 ThermalManagementInhReq "Provides state of inhibit request for Aftertreatment thermal management from external system.
Aftertreatment Thermal Management indicates that the exhaust temperatures have been controlled for expected functioning of the aftertreatment system - ...";
CM_ BO_ 2558590718 "Hybrid System Control 1
This messages is sent to the hybrid system to control hybrid related features.";
CM_ SG_ 2558590718 ShutdownCmd "Indicates the Hybrid System Shutdown Request state.  The signal gives network controllers the ability to disable all hybrid system functionality including propulsion, regenerative braking, and hybrid powered accessories.  For electric hybrids, the ...";
CM_ SG_ 2558590718 PropulsionDisableReq "Indicates the Hybrid System Disable Request state.  The signal gives network controllers the ability to disable the propulsion aspect of hybrid system operation when this request is on.  However, hybrid powered accessories may be on and the engine ...";
CM_ SG_ 2558590718 HybrdSystmRgnrtvBrakingDisableRq "Indicates the hybrid system regenerative braking disable request state.  This signal gives network controllers the ability to disable all regenerative braking.  This is not the operator controlled switch that performs regenerative braking disable ...";
CM_ SG_ 2558590718 HybridSystemProtectionOverrideRq "Indicates the hybrid system protection override request state.  This request allows overriding of hybrid system protection
features and failure modes allowing hybrid systems to continue to operate, if possible. This is not the physical switch that ...";
CM_ BO_ 2350776062 "Engine Ignition Controller
Commanded engine ignition timing advance";
CM_ SG_ 2350776062 EngTimingAdvance "Ignition timing as a command to the ignition control module.  Positive values command an increasingly advanced timing from TDC. The same timing applies to all cylinders. Use SPN 7356 - SPN 7379 for cylinder specific timing offsets from this timing.";
CM_ BO_ 2350710526 "Transmission Control 3
This message is used to control the output speed and/or torque of a transmission.
For example, this message could be directed toward a continuously variable transmission (CVT) where output speed and torque are not directly ...";
CM_ SG_ 2350710526 MessageChecksum "The message checksum is used to verify the signal path from the transmitting device to the receiving device.
The message checksum is calculated using the first 7 data bytes, the message counter and the bytes of the message identifier. It is ...";
CM_ SG_ 2350710526 TransRequestedTorque_TorqueLimit "Parameter provided to the transmission in the torque/speed control message for controlling or limiting the output torque.
Note:  0% to 125% for (positive) powered torque requests, -125% to 0% for (negative) retarding torque requests.  Does not ...";
CM_ SG_ 2350710526 TransRequestedOutputShaftSpeed "Used to request output shaft speed of the transmission which has a output through a driveline to the wheels of a machine/vehicle.";
CM_ SG_ 2350710526 MessageCounter "The message counter is used to detect situations where the transmitting ECU malfunction repeats the same frame all the time.  The receiver of the information may use the counter parameter to detect this situation.
Note:  The initial value of the 4 ...";
CM_ SG_ 2350710526 TransOverrideCtrlModePriority "This field is used as an input to the transmission to determine the priority of the Override Control Mode received in the Torque/Speed Control message.  The default is 11 (Low priority).  It is not required to use the same priority during the entire ...";
CM_ SG_ 2350710526 TransOverrideCtrlMode "The override control mode defines the type of control mode used to control transmission operation.
00 = Override disabled - Disable any existing control commanded by the source of this command.
01 = Speed control - Control speed to the included ...";
CM_ BO_ 2582642430 "Proprietary A2
This proprietary PG uses the Destination Specific PDU Format allowing manufacturers to direct their proprietary communications to a specific destination node.";
CM_ BO_ 2566836734 "Oxygen Sensor Test Results
SAE J1939 will not specify an implementation for this DM.  Oxygen sensor test and results should be communicated using DM7 and DM8";
CM_ BO_ 2566801918 "Ground-based Speed and Distance
This message is normally sent by the Tractor ECU on the implement bus on construction and agricultural implements and provides to connected systems, the current measured ground speed.";
CM_ SG_ 2566801918 GroundBasedDirection "A measured signal indicating either forward or reverse as the direction of travel.  When speed is zero, indicate the last travel direction until a different direction is detected.

00 Reverse
01 Forward
10 Error indication
11 Not available";
CM_ SG_ 2566801918 GroundBasedImplementDistance "Actual distance travelled by a machine based on measurements from a sensor such as RADAR.  When distance exceeds 4 211 081.215 m, the value should be reset to zero and incremented as additional distance accrues.";
CM_ SG_ 2566801918 GroundBasedImplementSpeed "Actual ground speed of a machine, measured by a sensor such as RADAR.";
CM_ BO_ 2566801662 "Wheel-based Speed and Distance
This message is sent by the Tractor ECU on the implement bus on construction and agricultural implements and provides to connected systems, the current measured wheel-based speed.";
CM_ SG_ 2566801662 KeySwitchNOTOFF "Indicates the Key Switch of the tractor or power unit is NOT in the Off position. This does not indicate unforeseen power interruption such as those caused by starting the engine or due to connector intermittents.
00 Key Switch Off
01 Key Switch ...";
CM_ SG_ 2566801662 WheelBasedDirection "A measured signal indicating either forward or reverse as the direction of travel.  When speed is zero, indicate the last travel direction until a different direction is detected or selected and engaged.
00 Reverse
01 Forward
10 Error indication
 ...";
CM_ SG_ 2566801662 MaxTimeOfTractorPower "The maximum time of remaining tractor or power unit supplied electrical power at the current load.";
CM_ SG_ 2566801662 WheelBasedDistance "The distance travelled by a machine as calculated from wheel or tail shaft speed.  When distance exceeds 4211081,215 m, the value should be reset to zero and incremented as additional distance accrues.";
CM_ SG_ 2566801662 WheelBasedSpeed "A value of the speed of a machine as calculated from the measured wheel or tail shaft speed.";
CM_ BO_ 2566801406 "Maintain Power
This message is sent by any ECU connected to the implement bus requesting that the Tractor ECU not switch off the power for the next 2 seconds.";
CM_ SG_ 2566801406 ImplementInWorkState "Indicates that an implement is connected to a tractor or power unit and is 'in-work'.

00   Implement is 'out of work'
01   Implement is 'in-work'
10   Error indication
11   Not available";
CM_ SG_ 2566801406 ImplementTransportState "Indicates the transport state of an implement connected to a tractor or power unit.

00 Implement may Not be transported 
01 Implement may be transported
10 Error indication
11 Not available";
CM_ SG_ 2566801406 ImplementParkState "Indicates the state of an implement where it may be disconnected from a tractor or power unit.

00 Implement may Not be disconnected 
01 Implement may be disconnected
10 Error indication
11 Not available";
CM_ SG_ 2566801406 ImplementWorkState "Indicates that an implement is connected to a tractor or power unit and is ready for work

00 Implement is Not ready for field work 
01 Implement is ready for field work
10 Error indication
11 Not available";
CM_ SG_ 2566801406 MaintainECUPower "Request to the Tractor ECU to maintain ECU_PWR power for the next 2 seconds.

00 No Further Requirement for ECU_PWR
01 Requirement for 2 more seconds of ECU_PWR
10 Reserved 
11 Don't Care";
CM_ SG_ 2566801406 MaintainAcuatorPower "Request to the Tractor ECU to maintain PWR power for the next 2 seconds.

00 No Further Requirement for PWR
01 Requirement for 2 more seconds of PWR
10 Reserved 
11 Don't Care";
CM_ BO_ 2566801150 "Secondary or Front Hitch Status
This message provides the measurement of the current front hitch parameters.";
CM_ SG_ 2566801150 FrontDraft "The apparent horizontal force applied to the front hitch by an implement.  A positive value indicates force applied to the tractor opposed to heading.";
CM_ SG_ 2566801150 FrontNominalLowerLinkForce "This measurement provides an indication of draft at the lower links of the front three point hitch. Nominal lower link force may be expected to be approximately linear with respect to draft and may be proportional to draft for a single hitch ...";
CM_ SG_ 2566801150 FrontHitchInworkIndication "A measured signal indicating that the front hitch is positioned below (in-work) or above (out-of-work) an adjustable switching threshold.

00 Hitch position is out-of-work 
01 Hitch position is in-work
10 Error indication
11 Not available";
CM_ SG_ 2566801150 FrontHitchPos "The measured position of the front three-point-hitch.  Expressed as a percentage of full travel.  Zero percent indicates the full down position, and 100%, the full up position.";
CM_ BO_ 2566800894 "Primary or Rear Hitch Status
This message provides the measurement of the current rear hitch parameters.";
CM_ SG_ 2566800894 RearHitchExit_reasonCode "This parameter indicates why the Rear Hitch cannot accept remote commands or has most recently stopped accepting remote commands.
0-No reason/all clear
1-Operator presence not detected
2-Implement released control of function
3-Operator override ...";
CM_ SG_ 2566800894 RearDraft "The apparent horizontal force applied to the rear hitch by an implement.  A positive value indicates force applied to the tractor opposed to heading.";
CM_ SG_ 2566800894 RearNominalLowerLinkForce "This measurement provides an indication of draft at the lower links of the rear three point hitch. Nominal lower link force may be expected to be approximately linear with respect to draft and may be proportional to draft for a single hitch ...";
CM_ SG_ 2566800894 RearHitchInworkIndication "A measured signal indicating that the rear hitch is positioned below (in-work) or above (out-of-work) an adjustable switching threshold.  The method of determining switching threshold is not standardise and will be determined by machine designers.
 ...";
CM_ SG_ 2566800894 RearHitchPos "The measured position of the rear three-point-hitch.  Expressed as a percentage of full travel.  Zero percent indicates the full down position, and 100%, the full up position.";
CM_ BO_ 2566800638 "Secondary or Front Power Take off Output Shaft
This message provides the measurement of the current secondary or front PTO output shaft parameters.";
CM_ SG_ 2566800638 FrontPTOExit_reasonCode "This parameter indicates why the Front PTO cannot accept remote commands or has most recently stopped accepting remote commands.
0-No reason/all clear
1-Operator presence not detected
2-Implement released control of function
3-Operator override ...";
CM_ SG_ 2566800638 FrontHitchExit_reasonCode "This parameter indicates why the Front Hitch cannot accept remote commands or has most recently stopped accepting remote commands.
0-No reason/all clear
1-Operator presence not detected
2-Implement released control of function
3-Operator ...";
CM_ SG_ 2566800638 FrontPowerTakeOffEngagement "A measured signal indicating that the front power take off is engaged or disengage.

00 Power take off disengaged
01 Power take off engaged
10 Error indication
11 Not available";
CM_ SG_ 2566800638 FrontPowerTakeOffMode "A measured signal indicating that the front power take off mode is either 540 or 1000 rpm. 

00 Power take off mode is 540
01 Power take off mode is 1000
10 Error indication
11 Not available";
CM_ SG_ 2566800638 FrontPowerTakeOffEconomyMode "A measured signal indicating that the front power take off economy mode is engaged or disengaged. Economy mode PTO operate at 540 or 1000 rpm at a lower engine rpm.
00 Power take off economy mode is disengaged
01 Power take off economy mode is ...";
CM_ SG_ 2566800638 FrontPTOOutputShaftSpeedSetPoint "The measured value of the set point of the rotational speed of the front power take off (PTO) output shaft.";
CM_ SG_ 2566800638 FrontPTOOutputShaftSpeed "The measured rotational speed of the front power take off (PTO) output shaft. For existing tractors that monitor PTO speed prior to the engagement clutch, the PTO speed would only be valid when PTO is engaged and not available when PTO disengaged.";
CM_ BO_ 2566800382 "Primary or Rear Power Take off Output Shaft
This message provides the measurement of the current primary or rear PTO output shaft parameters.";
CM_ SG_ 2566800382 RearPTOExit_reasonCode "This parameter indicates why the Rear PTO cannot accept remote commands or has most recently stopped accepting remote commands.
0-No reason/all clear
1-Operator presence not detected
2-Implement released control of function
3-Operator override ...";
CM_ SG_ 2566800382 RearPowerTakeOffEngagement "A measured signal indicating that the rear power take off is engaged or disengage.

00 Power take off disengaged
01 Power take off engaged
10 Error indication
11 Not available";
CM_ SG_ 2566800382 RearPowerTakeOffMode "A measured signal indicating that the rear power take off mode is either 540 or 1000 rpm. 

00 Power take off mode is 540
01 Power take off mode is 1000
10 Error indication
11 Not available";
CM_ SG_ 2566800382 RearPowerTakeOffEconomyMode "A measured signal indicating that the rear power take off economy mode is engaged or disengaged. Economy mode PTO operate at 540 or 1000 rpm at a lower engine rpm.
00 Power take off economy mode is disengaged
01 Power take off economy mode is ...";
CM_ SG_ 2566800382 RearPTOOutputShaftSpeedSetPoint "The measured value of the set point of the rotational speed of the rear power take off (PTO) output shaft.";
CM_ SG_ 2566800382 RearPTOOutputShaftSpeed "The measured rotational speed of the rear power take off (PTO) output shaft. For existing tractors that monitor PTO speed prior to the engagement clutch, the PTO speed would only be valid when PTO is engaged and not available when PTO disengaged.";
CM_ BO_ 2566800126 "Hitch and PTO Commands
This message provides control of the hitch position, PTO shaft set point speed and PTO engagement.";
CM_ SG_ 2566800126 FrontPowerTakeOffModeCmd "The command to select the mode of the front power take off .

00 Select 540 rpm mode
01 Select 1000 rpm mode 
10 Reserved
11 Don't Care";
CM_ SG_ 2566800126 RearPowerTakeOffModeCmd "The command to select the mode of the rear power take off .

00 Select 540 rpm mode
01 Select 1000 rpm mode 
10 Reserved
11 Don't Care";
CM_ SG_ 2566800126 FrontPowerTakeOffEconomyModeCmd "The command to engage or disengage the front power take off‘s economy mode.

00 Disengage Power take off‘s economy mode
01 Engage Power take off‘s economy mode
10 Reserved
11 Don't Care";
CM_ SG_ 2566800126 RearPowerTakeOffEconomyModeCmd "The command to engage or disengage the rear power take off‘s economy mode.

00 Disengage Power take off‘s economy mode
01 Engage Power take off‘s economy mode
10 Reserved
11 Don't Care";
CM_ SG_ 2566800126 FrontPowerTakeOffEngagementCmd "The command to engage or disengage the front power take off .

00 Disengage Power take off
01 Engage Power take off 
10 Reserved
11 Don't Care";
CM_ SG_ 2566800126 RearPowerTakeOffEngagementCmd "The command to engage or disengage the rear power take off .

00 Disengage Power take off
01 Engage Power take off 
10 Reserved
11 Don't Care";
CM_ SG_ 2566800126 RrPTOOutputShaftSpeedSetPointCmd "The command to set the rotational speed of the rear power take off (PTO) output shaft.";
CM_ SG_ 2566800126 FrntPTOOtptShaftSpeedSetPointCmd "The command to set the rotational speed of the front power take off (PTO) output shaft.";
CM_ SG_ 2566800126 RearHitchPosCmd "Command to allow the position of the rear three-point-hitch to be set.  Expressed as a percentage of full travel.  Zero percent indicates the full down position, and 100%, the full up position.";
CM_ SG_ 2566800126 FrontHitchPosCmd "Command to allow the position of the front three-point-hitch to be set.  Expressed as a percentage of full travel.  Zero percent indicates the full down position, and 100%, the full up position.";
CM_ BO_ 2566799358 "Auxiliary Valve Number 15 Command
This message provides control of the flow through the auxiliary valves.";
CM_ SG_ 2566799358 AuxValve15FailSafeModeCmd "Command for setting the fail safe mode of an auxiliary valve.

00 Block
01 Float
10 Reserved
11 Don't Care";
CM_ SG_ 2566799358 AuxValve15StateCmd "Command for setting the auxiliary valve state.  With float enabled, hydraulic fluid may flow to or from the tractor as driven by the implement.

0000 Block
0001 Extend
0010 Retract
0011 Float
0100-1110 Reserved
1111 Don't Care";
CM_ SG_ 2566799358 AuxValve15PortFlowCmd "The command to set the flow through the  extend or retract port of an auxiliary valve of a tractor, expressed as a percentage of full flow.  Zero percent indicates no flow, 100% indicates maximum flow, flow returns to the tractor through the ...";
CM_ BO_ 2566799102 "Auxiliary Valve Number 14 Command
This message provides control of the flow through the auxiliary valves.";
CM_ SG_ 2566799102 AuxValve14FailSafeModeCmd "Command for setting the fail safe mode of an auxiliary valve.

00 Block
01 Float
10 Reserved
11 Don't Care";
CM_ SG_ 2566799102 AuxValve14StateCmd "Command for setting the auxiliary valve state.  With float enabled, hydraulic fluid may flow to or from the tractor as driven by the implement.

0000 Block
0001 Extend
0010 Retract
0011 Float
0100-1110 Reserved
1111 Don't Care";
CM_ SG_ 2566799102 AuxValve14PortFlowCmd "The command to set the flow through the  extend or retract port of an auxiliary valve of a tractor, expressed as a percentage of full flow.  Zero percent indicates no flow, 100% indicates maximum flow, flow returns to the tractor through the ...";
CM_ BO_ 2566798846 "Auxiliary Valve Number 13 Command
This message provides control of the flow through the auxiliary valves.";
CM_ SG_ 2566798846 AuxValve13FailSafeModeCmd "Command for setting the fail safe mode of an auxiliary valve.

00 Block
01 Float
10 Reserved
11 Don't Care";
CM_ SG_ 2566798846 AuxValve13StateCmd "Command for setting the auxiliary valve state.  With float enabled, hydraulic fluid may flow to or from the tractor as driven by the implement.

0000 Block
0001 Extend
0010 Retract
0011 Float
0100-1110 Reserved
1111 Don't Care";
CM_ SG_ 2566798846 AuxValve13PortFlowCmd "The command to set the flow through the  extend or retract port of an auxiliary valve of a tractor, expressed as a percentage of full flow.  Zero percent indicates no flow, 100% indicates maximum flow, flow returns to the tractor through the ...";
CM_ BO_ 2566798590 "Auxiliary Valve Number 12 Command
This message provides control of the flow through the auxiliary valves.";
CM_ SG_ 2566798590 AuxValve12FailSafeModeCmd "Command for setting the fail safe mode of an auxiliary valve.

00 Block
01 Float
10 Reserved
11 Don't Care";
CM_ SG_ 2566798590 AuxValve12StateCmd "Command for setting the auxiliary valve state.  With float enabled, hydraulic fluid may flow to or from the tractor as driven by the implement.

0000 Block
0001 Extend
0010 Retract
0011 Float
0100-1110 Reserved
1111 Don't Care";
CM_ SG_ 2566798590 AuxValve12PortFlowCmd "The command to set the flow through the  extend or retract port of an auxiliary valve of a tractor, expressed as a percentage of full flow.  Zero percent indicates no flow, 100% indicates maximum flow, flow returns to the tractor through the ...";
CM_ BO_ 2566798334 "Auxiliary Valve Number 11 Command
This message provides control of the flow through the auxiliary valves.";
CM_ SG_ 2566798334 AuxValve11FailSafeModeCmd "Command for setting the fail safe mode of an auxiliary valve.

00 Block
01 Float
10 Reserved
11 Don't Care";
CM_ SG_ 2566798334 AuxValve11StateCmd "Command for setting the auxiliary valve state.  With float enabled, hydraulic fluid may flow to or from the tractor as driven by the implement.

0000 Block
0001 Extend
0010 Retract
0011 Float
0100-1110 Reserved
1111 Don't Care";
CM_ SG_ 2566798334 AuxValve11PortFlowCmd "The command to set the flow through the  extend or retract port of an auxiliary valve of a tractor, expressed as a percentage of full flow.  Zero percent indicates no flow, 100% indicates maximum flow, flow returns to the tractor through the ...";
CM_ BO_ 2566798078 "Auxiliary Valve Number 10 Command
This message provides control of the flow through the auxiliary valves.";
CM_ SG_ 2566798078 AuxValve10FailSafeModeCmd "Command for setting the fail safe mode of an auxiliary valve.

00 Block
01 Float
10 Reserved
11 Don't Care";
CM_ SG_ 2566798078 AuxValve10StateCmd "Command for setting the auxiliary valve state.  With float enabled, hydraulic fluid may flow to or from the tractor as driven by the implement.

0000 Block
0001 Extend
0010 Retract
0011 Float
0100-1110 Reserved
1111 Don't Care";
CM_ SG_ 2566798078 AuxValve10PortFlowCmd "The command to set the flow through the  extend or retract port of an auxiliary valve of a tractor, expressed as a percentage of full flow.  Zero percent indicates no flow, 100% indicates maximum flow, flow returns to the tractor through the ...";
CM_ BO_ 2566797822 "Auxiliary Valve Number 9 Command
This message provides control of the flow through the auxiliary valves.";
CM_ SG_ 2566797822 AuxValve9FailSafeModeCmd "Command for setting the fail safe mode of an auxiliary valve.

00 Block
01 Float
10 Reserved
11 Don't Care";
CM_ SG_ 2566797822 AuxValve9StateCmd "Command for setting the auxiliary valve state.  With float enabled, hydraulic fluid may flow to or from the tractor as driven by the implement.

0000 Block
0001 Extend
0010 Retract
0011 Float
0100-1110 Reserved
1111 Don't Care";
CM_ SG_ 2566797822 AuxValve9PortFlowCmd "The command to set the flow through the  extend or retract port of an auxiliary valve of a tractor, expressed as a percentage of full flow.  Zero percent indicates no flow, 100% indicates maximum flow, flow returns to the tractor through the ...";
CM_ BO_ 2566797566 "Auxiliary Valve Number 8 Command
This message provides control of the flow through the auxiliary valves.";
CM_ SG_ 2566797566 AuxValve8FailSafeModeCmd "Command for setting the fail safe mode of an auxiliary valve.

00 Block
01 Float
10 Reserved
11 Don't Care";
CM_ SG_ 2566797566 AuxValve8StateCmd "Command for setting the auxiliary valve state.  With float enabled, hydraulic fluid may flow to or from the tractor as driven by the implement.

0000 Block
0001 Extend
0010 Retract
0011 Float
0100-1110 Reserved
1111 Don't Care";
CM_ SG_ 2566797566 AuxValve8PortFlowCmd "The command to set the flow through the  extend or retract port of an auxiliary valve of a tractor, expressed as a percentage of full flow.  Zero percent indicates no flow, 100% indicates maximum flow, flow returns to the tractor through the ...";
CM_ BO_ 2566797310 "Auxiliary Valve Number 7 Command
This message provides control of the flow through the auxiliary valves.";
CM_ SG_ 2566797310 AuxValve7FailSafeModeCmd "Command for setting the fail safe mode of an auxiliary valve.

00 Block
01 Float
10 Reserved
11 Don't Care";
CM_ SG_ 2566797310 AuxValve7StateCmd "Command for setting the auxiliary valve state.  With float enabled, hydraulic fluid may flow to or from the tractor as driven by the implement.

0000 Block
0001 Extend
0010 Retract
0011 Float
0100-1110 Reserved
1111 Don't Care";
CM_ SG_ 2566797310 AuxValve7PortFlowCmd "The command to set the flow through the  extend or retract port of an auxiliary valve of a tractor, expressed as a percentage of full flow.  Zero percent indicates no flow, 100% indicates maximum flow, flow returns to the tractor through the ...";
CM_ BO_ 2566797054 "Auxiliary Valve Number 6 Command
This message provides control of the flow through the auxiliary valves.";
CM_ SG_ 2566797054 AuxValve6FailSafeModeCmd "Command for setting the fail safe mode of an auxiliary valve.

00 Block
01 Float
10 Reserved
11 Don't Care";
CM_ SG_ 2566797054 AuxValve6StateCmd "Command for setting the auxiliary valve state.  With float enabled, hydraulic fluid may flow to or from the tractor as driven by the implement.

0000 Block
0001 Extend
0010 Retract
0011 Float
0100-1110 Reserved
1111 Don't Care";
CM_ SG_ 2566797054 AuxValve6PortFlowCmd "The command to set the flow through the  extend or retract port of an auxiliary valve of a tractor, expressed as a percentage of full flow.  Zero percent indicates no flow, 100% indicates maximum flow, flow returns to the tractor through the ...";
CM_ BO_ 2566796798 "Auxiliary Valve Number 5 Command
This message provides control of the flow through the auxiliary valves.";
CM_ SG_ 2566796798 AuxValve5FailSafeModeCmd "Command for setting the fail safe mode of an auxiliary valve.

00 Block
01 Float
10 Reserved
11 Don't Care";
CM_ SG_ 2566796798 AuxValve5StateCmd "Command for setting the auxiliary valve state.  With float enabled, hydraulic fluid may flow to or from the tractor as driven by the implement.

0000 Block
0001 Extend
0010 Retract
0011 Float
0100-1110 Reserved
1111 Don't Care";
CM_ SG_ 2566796798 AuxValve5PortFlowCmd "The command to set the flow through the  extend or retract port of an auxiliary valve of a tractor, expressed as a percentage of full flow.  Zero percent indicates no flow, 100% indicates maximum flow, flow returns to the tractor through the ...";
CM_ BO_ 2566796542 "Auxiliary Valve Number 4 Command
This message provides control of the flow through the auxiliary valves.";
CM_ SG_ 2566796542 AuxValve4FailSafeModeCmd "Command for setting the fail safe mode of an auxiliary valve.

00 Block
01 Float
10 Reserved
11 Don't Care";
CM_ SG_ 2566796542 AuxValve4StateCmd "Command for setting the auxiliary valve state.  With float enabled, hydraulic fluid may flow to or from the tractor as driven by the implement.

0000 Block
0001 Extend
0010 Retract
0011 Float
0100-1110 Reserved
1111 Don't Care";
CM_ SG_ 2566796542 AuxValve4PortFlowCmd "The command to set the flow through the  extend or retract port of an auxiliary valve of a tractor, expressed as a percentage of full flow.  Zero percent indicates no flow, 100% indicates maximum flow, flow returns to the tractor through the ...";
CM_ BO_ 2566796286 "Auxiliary Valve Number 3 Command
This message provides control of the flow through the auxiliary valves.";
CM_ SG_ 2566796286 AuxValve3FailSafeModeCmd "Command for setting the fail safe mode of an auxiliary valve.

00 Block
01 Float
10 Reserved
11 Don't Care";
CM_ SG_ 2566796286 AuxValve3StateCmd "Command for setting the auxiliary valve state.  With float enabled, hydraulic fluid may flow to or from the tractor as driven by the implement.

0000 Block
0001 Extend
0010 Retract
0011 Float
0100-1110 Reserved
1111 Don't Care";
CM_ SG_ 2566796286 AuxValve3PortFlowCmd "The command to set the flow through the  extend or retract port of an auxiliary valve of a tractor, expressed as a percentage of full flow.  Zero percent indicates no flow, 100% indicates maximum flow, flow returns to the tractor through the ...";
CM_ BO_ 2566796030 "Auxiliary Valve Number 2 Command
This message provides control of the flow through the auxiliary valves.";
CM_ SG_ 2566796030 AuxValve2FailSafeModeCmd "Command for setting the fail safe mode of an auxiliary valve.

00 Block
01 Float
10 Reserved
11 Don't Care";
CM_ SG_ 2566796030 AuxValve2StateCmd "Command for setting the auxiliary valve state.  With float enabled, hydraulic fluid may flow to or from the tractor as driven by the implement.

0000 Block
0001 Extend
0010 Retract
0011 Float
0100-1110 Reserved
1111 Don't Care";
CM_ SG_ 2566796030 AuxValve2PortFlowCmd "The command to set the flow through the  extend or retract port of an auxiliary valve of a tractor, expressed as a percentage of full flow.  Zero percent indicates no flow, 100% indicates maximum flow, flow returns to the tractor through the ...";
CM_ BO_ 2566795774 "Auxiliary Valve Number 1 Command
This message provides control of the flow through the auxiliary valves.";
CM_ SG_ 2566795774 AuxValve1FailSafeModeCmd "Command for setting the fail safe mode of an auxiliary valve.

00 Block
01 Float
10 Reserved
11 Don't Care";
CM_ SG_ 2566795774 AuxValve1StateCmd "Command for setting the auxiliary valve state.  With float enabled, hydraulic fluid may flow to or from the tractor as driven by the implement.

0000 Block
0001 Extend
0010 Retract
0011 Float
0100-1110 Reserved
1111 Don't Care";
CM_ SG_ 2566795774 AuxValve1PortFlowCmd "The command to set the flow through the  extend or retract port of an auxiliary valve of a tractor, expressed as a percentage of full flow.  Zero percent indicates no flow, 100% indicates maximum flow, flow returns to the tractor through the ...";
CM_ BO_ 2566795518 "Auxiliary Valve Number 0 Command
This message provides control of the flow through the auxiliary valves.";
CM_ SG_ 2566795518 AuxValve0FailSafeModeCmd "Command for setting the fail safe mode of an auxiliary valve.

00 Block
01 Float
10 Reserved
11 Don't Care";
CM_ SG_ 2566795518 AuxValve0StateCmd "Command for setting the auxiliary valve state.  With float enabled, hydraulic fluid may flow to or from the tractor as driven by the implement.

0000 Block
0001 Extend
0010 Retract
0011 Float
0100-1110 Reserved
1111 Don't Care";
CM_ SG_ 2566795518 AuxValve0PortFlowCmd "The command to set the flow through the  extend or retract port of an auxiliary valve of a tractor, expressed as a percentage of full flow.  Zero percent indicates no flow, 100% indicates maximum flow, flow returns to the tractor through the ...";
CM_ BO_ 2566795262 "Auxiliary Valve Number 15 Measured Flow
This message provides the measurement of specified auxiliary valve.";
CM_ SG_ 2566795262 AuxValve15ReturnPortPress "The measured nominal pressure at the return port of an auxiliary valve of a tractor.";
CM_ SG_ 2566795262 AuxValve15RetractPortPress "The measured nominal pressure at the retract port of an auxiliary valve of a tractor.";
CM_ SG_ 2566795262 AuxValve15ExtendPortPress "The measured nominal pressure at the extend port of an auxiliary valve of a tractor.";
CM_ SG_ 2566795262 AxValve15RetractPortMeasuredFlow "The measured flow through the retract port of an auxiliary valve of a tractor, expressed as a percentage of full flow.  Zero percent indicates no flow, 100% indicates maximum flow, -100% indicates maximum flow returning to the tractor through the ...";
CM_ SG_ 2566795262 AuxValve15ExtendPortMeasuredFlow "The measured flow through the extend port of an auxiliary valve of a tractor, expressed as a percentage of full flow.  Zero percent indicates no flow, 100% indicates maximum flow, -100% indicates maximum flow returning to the tractor through the ...";
CM_ BO_ 2566795006 "Auxiliary Valve Number 14 Measured Flow
This message provides the measurement of specified auxiliary valve.";
CM_ SG_ 2566795006 AuxValve14ReturnPortPress "The measured nominal pressure at the return port of an auxiliary valve of a tractor.";
CM_ SG_ 2566795006 AuxValve14RetractPortPress "The measured nominal pressure at the retract port of an auxiliary valve of a tractor.";
CM_ SG_ 2566795006 AuxValve14ExtendPortPress "The measured nominal pressure at the extend port of an auxiliary valve of a tractor.";
CM_ SG_ 2566795006 AxValve14RetractPortMeasuredFlow "The measured flow through the retract port of an auxiliary valve of a tractor, expressed as a percentage of full flow.  Zero percent indicates no flow, 100% indicates maximum flow, -100% indicates maximum flow returning to the tractor through the ...";
CM_ SG_ 2566795006 AuxValve14ExtendPortMeasuredFlow "The measured flow through the extend port of an auxiliary valve of a tractor, expressed as a percentage of full flow.  Zero percent indicates no flow, 100% indicates maximum flow, -100% indicates maximum flow returning to the tractor through the ...";
CM_ BO_ 2566794750 "Auxiliary Valve Number 13 Measured Flow
This message provides the measurement of specified auxiliary valve.";
CM_ SG_ 2566794750 AuxValve13ReturnPortPress "The measured nominal pressure at the return port of an auxiliary valve of a tractor.";
CM_ SG_ 2566794750 AuxValve13RetractPortPress "The measured nominal pressure at the retract port of an auxiliary valve of a tractor.";
CM_ SG_ 2566794750 AuxValve13ExtendPortPress "The measured nominal pressure at the extend port of an auxiliary valve of a tractor.";
CM_ SG_ 2566794750 AxValve13RetractPortMeasuredFlow "The measured flow through the retract port of an auxiliary valve of a tractor, expressed as a percentage of full flow.  Zero percent indicates no flow, 100% indicates maximum flow, -100% indicates maximum flow returning to the tractor through the ...";
CM_ SG_ 2566794750 AuxValve13ExtendPortMeasuredFlow "The measured flow through the extend port of an auxiliary valve of a tractor, expressed as a percentage of full flow.  Zero percent indicates no flow, 100% indicates maximum flow, -100% indicates maximum flow returning to the tractor through the ...";
CM_ BO_ 2566794494 "Auxiliary Valve Number 12 Measured Flow
This message provides the measurement of specified auxiliary valve.";
CM_ SG_ 2566794494 AuxValve12ReturnPortPress "The measured nominal pressure at the return port of an auxiliary valve of a tractor.";
CM_ SG_ 2566794494 AuxValve12RetractPortPress "The measured nominal pressure at the retract port of an auxiliary valve of a tractor.";
CM_ SG_ 2566794494 AuxValve12ExtendPortPress "The measured nominal pressure at the extend port of an auxiliary valve of a tractor.";
CM_ SG_ 2566794494 AxValve12RetractPortMeasuredFlow "The measured flow through the retract port of an auxiliary valve of a tractor, expressed as a percentage of full flow.  Zero percent indicates no flow, 100% indicates maximum flow, -100% indicates maximum flow returning to the tractor through the ...";
CM_ SG_ 2566794494 AuxValve12ExtendPortMeasuredFlow "The measured flow through the extend port of an auxiliary valve of a tractor, expressed as a percentage of full flow.  Zero percent indicates no flow, 100% indicates maximum flow, -100% indicates maximum flow returning to the tractor through the ...";
CM_ BO_ 2566794238 "Auxiliary Valve Number 11 Measured Flow
This message provides the measurement of specified auxiliary valve.";
CM_ SG_ 2566794238 AuxValve11ReturnPortPress "The measured nominal pressure at the return port of an auxiliary valve of a tractor.";
CM_ SG_ 2566794238 AuxValve11RetractPortPress "The measured nominal pressure at the retract port of an auxiliary valve of a tractor.";
CM_ SG_ 2566794238 AuxValve11ExtendPortPress "The measured nominal pressure at the extend port of an auxiliary valve of a tractor.";
CM_ SG_ 2566794238 AxValve11RetractPortMeasuredFlow "The measured flow through the retract port of an auxiliary valve of a tractor, expressed as a percentage of full flow.  Zero percent indicates no flow, 100% indicates maximum flow, -100% indicates maximum flow returning to the tractor through the ...";
CM_ SG_ 2566794238 AuxValve11ExtendPortMeasuredFlow "The measured flow through the extend port of an auxiliary valve of a tractor, expressed as a percentage of full flow.  Zero percent indicates no flow, 100% indicates maximum flow, -100% indicates maximum flow returning to the tractor through the ...";
CM_ BO_ 2566793982 "Auxiliary Valve Number 10 Measured Flow
This message provides the measurement of specified auxiliary valve.";
CM_ SG_ 2566793982 AuxValve10ReturnPortPress "The measured nominal pressure at the return port of an auxiliary valve of a tractor.";
CM_ SG_ 2566793982 AuxValve10RetractPortPress "The measured nominal pressure at the retract port of an auxiliary valve of a tractor.";
CM_ SG_ 2566793982 AuxValve10ExtendPortPress "The measured nominal pressure at the extend port of an auxiliary valve of a tractor.";
CM_ SG_ 2566793982 AxValve10RetractPortMeasuredFlow "The measured flow through the retract port of an auxiliary valve of a tractor, expressed as a percentage of full flow.  Zero percent indicates no flow, 100% indicates maximum flow, -100% indicates maximum flow returning to the tractor through the ...";
CM_ SG_ 2566793982 AuxValve10ExtendPortMeasuredFlow "The measured flow through the extend port of an auxiliary valve of a tractor, expressed as a percentage of full flow.  Zero percent indicates no flow, 100% indicates maximum flow, -100% indicates maximum flow returning to the tractor through the ...";
CM_ BO_ 2566793726 "Auxiliary Valve Number 9 Measured Flow
This message provides the measurement of specified auxiliary valve.";
CM_ SG_ 2566793726 AuxValve9ReturnPortPress "The measured nominal pressure at the return port of an auxiliary valve of a tractor.";
CM_ SG_ 2566793726 AuxValve9RetractPortPress "The measured nominal pressure at the retract port of an auxiliary valve of a tractor.";
CM_ SG_ 2566793726 AuxValve9ExtendPortPress "The measured nominal pressure at the extend port of an auxiliary valve of a tractor.";
CM_ SG_ 2566793726 AuxValve9RetractPortMeasuredFlow "The measured flow through the retract port of an auxiliary valve of a tractor, expressed as a percentage of full flow.  Zero percent indicates no flow, 100% indicates maximum flow, -100% indicates maximum flow returning to the tractor through the ...";
CM_ SG_ 2566793726 AuxValve9ExtendPortMeasuredFlow "The measured flow through the extend port of an auxiliary valve of a tractor, expressed as a percentage of full flow.  Zero percent indicates no flow, 100% indicates maximum flow, -100% indicates maximum flow returning to the tractor through the ...";
CM_ BO_ 2566793470 "Auxiliary Valve Number 8 Measured Flow
This message provides the measurement of specified auxiliary valve.";
CM_ SG_ 2566793470 AuxValve8ReturnPortPress "The measured nominal pressure at the return port of an auxiliary valve of a tractor.";
CM_ SG_ 2566793470 AuxValve8RetractPortPress "The measured nominal pressure at the retract port of an auxiliary valve of a tractor.";
CM_ SG_ 2566793470 AuxValve8ExtendPortPress "The measured nominal pressure at the extend port of an auxiliary valve of a tractor.";
CM_ SG_ 2566793470 AuxValve8RetractPortMeasuredFlow "The measured flow through the retract port of an auxiliary valve of a tractor, expressed as a percentage of full flow.  Zero percent indicates no flow, 100% indicates maximum flow, -100% indicates maximum flow returning to the tractor through the ...";
CM_ SG_ 2566793470 AuxValve8ExtendPortMeasuredFlow "The measured flow through the extend port of an auxiliary valve of a tractor, expressed as a percentage of full flow.  Zero percent indicates no flow, 100% indicates maximum flow, -100% indicates maximum flow returning to the tractor through the ...";
CM_ BO_ 2566793214 "Auxiliary Valve Number 7 Measured Flow
This message provides the measurement of specified auxiliary valve.";
CM_ SG_ 2566793214 AuxValve7ReturnPortPress "The measured nominal pressure at the return port of an auxiliary valve of a tractor.";
CM_ SG_ 2566793214 AuxValve7RetractPortPress "The measured nominal pressure at the retract port of an auxiliary valve of a tractor.";
CM_ SG_ 2566793214 AuxValve7ExtendPortPress "The measured nominal pressure at the extend port of an auxiliary valve of a tractor.";
CM_ SG_ 2566793214 AuxValve7RetractPortMeasuredFlow "The measured flow through the retract port of an auxiliary valve of a tractor, expressed as a percentage of full flow.  Zero percent indicates no flow, 100% indicates maximum flow, -100% indicates maximum flow returning to the tractor through the ...";
CM_ SG_ 2566793214 AuxValve7ExtendPortMeasuredFlow "The measured flow through the extend port of an auxiliary valve of a tractor, expressed as a percentage of full flow.  Zero percent indicates no flow, 100% indicates maximum flow, -100% indicates maximum flow returning to the tractor through the ...";
CM_ BO_ 2566792958 "Auxiliary Valve Number 6 Measured Flow
This message provides the measurement of specified auxiliary valve.";
CM_ SG_ 2566792958 AuxValve6ReturnPortPress "The measured nominal pressure at the return port of an auxiliary valve of a tractor.";
CM_ SG_ 2566792958 AuxValve6RetractPortPress "The measured nominal pressure at the retract port of an auxiliary valve of a tractor.";
CM_ SG_ 2566792958 AuxValve6ExtendPortPress "The measured nominal pressure at the extend port of an auxiliary valve of a tractor.";
CM_ SG_ 2566792958 AuxValve6RetractPortMeasuredFlow "The measured flow through the retract port of an auxiliary valve of a tractor, expressed as a percentage of full flow.  Zero percent indicates no flow, 100% indicates maximum flow, -100% indicates maximum flow returning to the tractor through the ...";
CM_ SG_ 2566792958 AuxValve6ExtendPortMeasuredFlow "The measured flow through the extend port of an auxiliary valve of a tractor, expressed as a percentage of full flow.  Zero percent indicates no flow, 100% indicates maximum flow, -100% indicates maximum flow returning to the tractor through the ...";
CM_ BO_ 2566792702 "Auxiliary Valve Number 5 Measured Flow
This message provides the measurement of specified auxiliary valve.";
CM_ SG_ 2566792702 AuxValve5ReturnPortPress "The measured nominal pressure at the return port of an auxiliary valve of a tractor.";
CM_ SG_ 2566792702 AuxValve5RetractPortPress "The measured nominal pressure at the retract port of an auxiliary valve of a tractor.";
CM_ SG_ 2566792702 AuxValve5ExtendPortPress "The measured nominal pressure at the extend port of an auxiliary valve of a tractor.";
CM_ SG_ 2566792702 AuxValve5RetractPortMeasuredFlow "The measured flow through the retract port of an auxiliary valve of a tractor, expressed as a percentage of full flow.  Zero percent indicates no flow, 100% indicates maximum flow, -100% indicates maximum flow returning to the tractor through the ...";
CM_ SG_ 2566792702 AuxValve5ExtendPortMeasuredFlow "The measured flow through the extend port of an auxiliary valve of a tractor, expressed as a percentage of full flow.  Zero percent indicates no flow, 100% indicates maximum flow, -100% indicates maximum flow returning to the tractor through the ...";
CM_ BO_ 2566792446 "Auxiliary Valve Number 4 Measured Flow
This message provides the measurement of specified auxiliary valve.";
CM_ SG_ 2566792446 AuxValve4ReturnPortPress "The measured nominal pressure at the return port of an auxiliary valve of a tractor.";
CM_ SG_ 2566792446 AuxValve4RetractPortPress "The measured nominal pressure at the retract port of an auxiliary valve of a tractor.";
CM_ SG_ 2566792446 AuxValve4ExtendPortPress "The measured nominal pressure at the extend port of an auxiliary valve of a tractor.";
CM_ SG_ 2566792446 AuxValve4RetractPortMeasuredFlow "The measured flow through the retract port of an auxiliary valve of a tractor, expressed as a percentage of full flow.  Zero percent indicates no flow, 100% indicates maximum flow, -100% indicates maximum flow returning to the tractor through the ...";
CM_ SG_ 2566792446 AuxValve4ExtendPortMeasuredFlow "The measured flow through the extend port of an auxiliary valve of a tractor, expressed as a percentage of full flow.  Zero percent indicates no flow, 100% indicates maximum flow, -100% indicates maximum flow returning to the tractor through the ...";
CM_ BO_ 2566792190 "Auxiliary Valve Number 3 Measured Flow
This message provides the measurement of specified auxiliary valve.";
CM_ SG_ 2566792190 AuxValve3ReturnPortPress "The measured nominal pressure at the return port of an auxiliary valve of a tractor.";
CM_ SG_ 2566792190 AuxValve3RetractPortPress "The measured nominal pressure at the retract port of an auxiliary valve of a tractor.";
CM_ SG_ 2566792190 AuxValve3ExtendPortPress "The measured nominal pressure at the extend port of an auxiliary valve of a tractor.";
CM_ SG_ 2566792190 AuxValve3RetractPortMeasuredFlow "The measured flow through the retract port of an auxiliary valve of a tractor, expressed as a percentage of full flow.  Zero percent indicates no flow, 100% indicates maximum flow, -100% indicates maximum flow returning to the tractor through the ...";
CM_ SG_ 2566792190 AuxValve3ExtendPortMeasuredFlow "The measured flow through the extend port of an auxiliary valve of a tractor, expressed as a percentage of full flow.  Zero percent indicates no flow, 100% indicates maximum flow, -100% indicates maximum flow returning to the tractor through the ...";
CM_ BO_ 2566791934 "Auxiliary Valve Number 2 Measured Flow
This message provides the measurement of specified auxiliary valve.";
CM_ SG_ 2566791934 AuxValve2ReturnPortPress "The measured nominal pressure at the return port of an auxiliary valve of a tractor.";
CM_ SG_ 2566791934 AuxValve2RetractPortPress "The measured nominal pressure at the retract port of an auxiliary valve of a tractor.";
CM_ SG_ 2566791934 AuxValve2ExtendPortPress "The measured nominal pressure at the extend port of an auxiliary valve of a tractor.";
CM_ SG_ 2566791934 AuxValve2RetractPortMeasuredFlow "The measured flow through the retract port of an auxiliary valve of a tractor, expressed as a percentage of full flow.  Zero percent indicates no flow, 100% indicates maximum flow, -100% indicates maximum flow returning to the tractor through the ...";
CM_ SG_ 2566791934 AuxValve2ExtendPortMeasuredFlow "The measured flow through the extend port of an auxiliary valve of a tractor, expressed as a percentage of full flow.  Zero percent indicates no flow, 100% indicates maximum flow, -100% indicates maximum flow returning to the tractor through the ...";
CM_ BO_ 2566791678 "Auxiliary Valve Number 1 Measured Flow
This message provides the measurement of specified auxiliary valve.";
CM_ SG_ 2566791678 AuxValve1ReturnPortPress "The measured nominal pressure at the return port of an auxiliary valve of a tractor.";
CM_ SG_ 2566791678 AuxValve1RetractPortPress "The measured nominal pressure at the retract port of an auxiliary valve of a tractor.";
CM_ SG_ 2566791678 AuxValve1ExtendPortPress "The measured nominal pressure at the extend port of an auxiliary valve of a tractor.";
CM_ SG_ 2566791678 AuxValve1RetractPortMeasuredFlow "The measured flow through the retract port of an auxiliary valve of a tractor, expressed as a percentage of full flow.  Zero percent indicates no flow, 100% indicates maximum flow, -100% indicates maximum flow returning to the tractor through the ...";
CM_ SG_ 2566791678 AuxValve1ExtendPortMeasuredFlow "The measured flow through the extend port of an auxiliary valve of a tractor, expressed as a percentage of full flow.  Zero percent indicates no flow, 100% indicates maximum flow, -100% indicates maximum flow returning to the tractor through the ...";
CM_ BO_ 2566791422 "Auxiliary Valve Number 0 Measured Flow
This message provides the measurement of specified auxiliary valve.";
CM_ SG_ 2566791422 AuxValve0ReturnPortPress "The measured nominal pressure at the return port of an auxiliary valve of a tractor.";
CM_ SG_ 2566791422 AuxValve0RetractPortPress "The measured nominal pressure at the retract port of an auxiliary valve of a tractor.";
CM_ SG_ 2566791422 AuxValve0ExtendPortPress "The measured nominal pressure at the extend port of an auxiliary valve of a tractor.";
CM_ SG_ 2566791422 AuxValve0RetractPortMeasuredFlow "The measured flow through the retract port of an auxiliary valve of a tractor, expressed as a percentage of full flow.  Zero percent indicates no flow, 100% indicates maximum flow, -100% indicates maximum flow returning to the tractor through the ...";
CM_ SG_ 2566791422 AuxValve0ExtendPortMeasuredFlow "The measured flow through the extend port of an auxiliary valve of a tractor, expressed as a percentage of full flow.  Zero percent indicates no flow, 100% indicates maximum flow, -100% indicates maximum flow returning to the tractor through the ...";
CM_ BO_ 2566791166 "Auxiliary Valve Number 15 Estimated Flow
This message provides the estimated flow of specified auxiliary valve.";
CM_ SG_ 2566791166 AuxValve15Exit_reasonCode "This parameter indicates why the Auxiliary Valve 15 cannot accept remote commands or has most recently stopped accepting remote commands.
0-No reason/all clear
1-Operator presence not detected
2-Implement released control of function
3-Operator ...";
CM_ SG_ 2566791166 AuxValve15FailSafeMode "The measured state the fail safe mode of an auxiliary valve.

00 Block
01 Float
10 Error
11 Not available";
CM_ SG_ 2566791166 AuxValve15State "The measured state of the auxiliary valve.   With float enabled, hydraulic fluid may flow to or from the tractor as driven by the implement.

0000 Blocked
0001 Extend
0010 Retract
0011 Floating
0100-1110 Reserved
1111 Don't Care";
CM_ SG_ 2566791166 AuxValve15RetractPortEstFlow "The value reported by the controller of flow through the retract port of an auxiliary valve of a tractor which could be based on the commanded position of the valve.  Zero percent indicates no flow, 100%, maximum flow, -100% maximum flow returning ...";
CM_ SG_ 2566791166 AuxValve15ExtendPortEstFlow "The value reported by the controller of flow through the extend port of an auxiliary valve of a tractor which could be based on the commanded position of the valve.  Zero percent indicates no flow, 100%, maximum flow, -100% maximum flow returning to ...";
CM_ BO_ 2566790910 "Auxiliary Valve Number 14 Estimated Flow
This message provides the estimated flow of specified auxiliary valve.";
CM_ SG_ 2566790910 AuxValve14Exit_reasonCode "This parameter indicates why the Auxiliary Valve 14 cannot accept remote commands or has most recently stopped accepting remote commands.
0-No reason/all clear
1-Operator presence not detected
2-Implement released control of function
3-Operator ...";
CM_ SG_ 2566790910 AuxValve14FailSafeMode "The measured state the fail safe mode of an auxiliary valve.

00 Block
01 Float
10 Error indication
11 Not available";
CM_ SG_ 2566790910 AuxValve14State "The measured state of the auxiliary valve.   With float enabled, hydraulic fluid may flow to or from the tractor as driven by the implement.

0000 Blocked
0001 Extend
0010 Retract
0011 Floating
0100-1110 Reserved
1111 Don't Care";
CM_ SG_ 2566790910 AuxValve14RetractPortEstFlow "The value reported by the controller of flow through the retract port of an auxiliary valve of a tractor which could be based on the commanded position of the valve.  Zero percent indicates no flow, 100%, maximum flow, -100% maximum flow returning ...";
CM_ SG_ 2566790910 AuxValve14ExtendPortEstFlow "The value reported by the controller of flow through the extend port of an auxiliary valve of a tractor which could be based on the commanded position of the valve.  Zero percent indicates no flow, 100%, maximum flow, -100% maximum flow returning to ...";
CM_ BO_ 2566790654 "Auxiliary Valve Number 13 Estimated Flow
This message provides the estimated flow of specified auxiliary valve.";
CM_ SG_ 2566790654 AuxValve13Exit_reasonCode "This parameter indicates why the Auxiliary Valve 13 cannot accept remote commands or has most recently stopped accepting remote commands.
0-No reason/all clear
1-Operator presence not detected
2-Implement released control of function
3-Operator ...";
CM_ SG_ 2566790654 AuxValve13FailSafeMode "The measured state the fail safe mode of an auxiliary valve.

00 Block
01 Float
10 Error indication
11 Not available";
CM_ SG_ 2566790654 AuxValve13State "The measured state of the auxiliary valve.   With float enabled, hydraulic fluid may flow to or from the tractor as driven by the implement.

0000 Blocked
0001 Extend
0010 Retract
0011 Floating
0100-1110 Reserved
1111 Don't Care";
CM_ SG_ 2566790654 AuxValve13RetractPortEstFlow "The value reported by the controller of flow through the retract port of an auxiliary valve of a tractor which could be based on the commanded position of the valve.  Zero percent indicates no flow, 100%, maximum flow, -100% maximum flow returning ...";
CM_ SG_ 2566790654 AuxValve13ExtendPortEstFlow "The value reported by the controller of flow through the extend port of an auxiliary valve of a tractor which could be based on the commanded position of the valve.  Zero percent indicates no flow, 100%, maximum flow, -100% maximum flow returning to ...";
CM_ BO_ 2566790398 "Auxiliary Valve Number 12 Estimated Flow
This message provides the estimated flow of specified auxiliary valve.";
CM_ SG_ 2566790398 AuxValve12Exit_reasonCode "This parameter indicates why the Auxiliary Valve 12 cannot accept remote commands or has most recently stopped accepting remote commands.
0-No reason/all clear
1-Operator presence not detected
2-Implement released control of function
3-Operator ...";
CM_ SG_ 2566790398 AuxValve12FailSafeMode "The measured state the fail safe mode of an auxiliary valve.

00 Block
01 Float
10 Error indication
11 Not available";
CM_ SG_ 2566790398 AuxValve12State "The measured state of the auxiliary valve.   With float enabled, hydraulic fluid may flow to or from the tractor as driven by the implement.

0000 Blocked
0001 Extend
0010 Retract
0011 Floating
0100-1110 Reserved
1111 Don't Care";
CM_ SG_ 2566790398 AuxValve12RetractPortEstFlow "The value reported by the controller of flow through the retract port of an auxiliary valve of a tractor which could be based on the commanded position of the valve.  Zero percent indicates no flow, 100%, maximum flow, -100% maximum flow returning ...";
CM_ SG_ 2566790398 AuxValve12ExtendPortEstFlow "The value reported by the controller of flow through the extend port of an auxiliary valve of a tractor which could be based on the commanded position of the valve.  Zero percent indicates no flow, 100%, maximum flow, -100% maximum flow returning to ...";
CM_ BO_ 2566790142 "Auxiliary Valve Number 11 Estimated Flow
This message provides the estimated flow of specified auxiliary valve.";
CM_ SG_ 2566790142 AuxValve11Exit_reasonCode "This parameter indicates why the Auxiliary Valve 11 cannot accept remote commands or has most recently stopped accepting remote commands.
0-No reason/all clear
1-Operator presence not detected
2-Implement released control of function
3-Operator ...";
CM_ SG_ 2566790142 AuxValve11FailSafeMode "The measured state the fail safe mode of an auxiliary valve.

00 Block
01 Float
10 Error indication
11 Not available";
CM_ SG_ 2566790142 AuxValve11State "The measured state of the auxiliary valve.   With float enabled, hydraulic fluid may flow to or from the tractor as driven by the implement.

0000 Blocked
0001 Extend
0010 Retract
0011 Floating
0100-1110 Reserved
1111 Don't Care";
CM_ SG_ 2566790142 AuxValve11RetractPortEstFlow "The value reported by the controller of flow through the retract port of an auxiliary valve of a tractor which could be based on the commanded position of the valve.  Zero percent indicates no flow, 100%, maximum flow, -100% maximum flow returning ...";
CM_ SG_ 2566790142 AuxValve11ExtendPortEstFlow "The value reported by the controller of flow through the extend port of an auxiliary valve of a tractor which could be based on the commanded position of the valve.  Zero percent indicates no flow, 100%, maximum flow, -100% maximum flow returning to ...";
CM_ BO_ 2566789886 "Auxiliary Valve Number 10 Estimated Flow
This message provides the estimated flow of specified auxiliary valve.";
CM_ SG_ 2566789886 AuxValve10Exit_reasonCode "This parameter indicates why the Auxiliary Valve 10 cannot accept remote commands or has most recently stopped accepting remote commands.
0-No reason/all clear
1-Operator presence not detected
2-Implement released control of function
3-Operator ...";
CM_ SG_ 2566789886 AuxValve10FailSafeMode "The measured state the fail safe mode of an auxiliary valve.

00 Block
01 Float
10 Error indication
11 Not available";
CM_ SG_ 2566789886 AuxValve10State "The measured state of the auxiliary valve.   With float enabled, hydraulic fluid may flow to or from the tractor as driven by the implement.

0000 Blocked
0001 Extend
0010 Retract
0011 Floating
0100-1110 Reserved
1111 Don't Care";
CM_ SG_ 2566789886 AuxValve10RetractPortEstFlow "The value reported by the controller of flow through the retract port of an auxiliary valve of a tractor which could be based on the commanded position of the valve.  Zero percent indicates no flow, 100%, maximum flow, -100% maximum flow returning ...";
CM_ SG_ 2566789886 AuxValve10ExtendPortEstFlow "The value reported by the controller of flow through the extend port of an auxiliary valve of a tractor which could be based on the commanded position of the valve.  Zero percent indicates no flow, 100%, maximum flow, -100% maximum flow returning to ...";
CM_ BO_ 2566789630 "Auxiliary Valve Number 9 Estimated Flow
This message provides the estimated flow of specified auxiliary valve.";
CM_ SG_ 2566789630 AuxValve9Exit_reasonCode "This parameter indicates why the Auxiliary Valve 9 cannot accept remote commands or has most recently stopped accepting remote commands.
0-No reason/all clear
1-Operator presence not detected
2-Implement released control of function
3-Operator ...";
CM_ SG_ 2566789630 AuxValve9FailSafeMode "The measured state the fail safe mode of an auxiliary valve.

00 Block
01 Float
10 Error indication
11 Not available";
CM_ SG_ 2566789630 AuxValve9State "The measured state of the auxiliary valve.   With float enabled, hydraulic fluid may flow to or from the tractor as driven by the implement.

0000 Blocked
0001 Extend
0010 Retract
0011 Floating
0100-1110 Reserved
1111 Don't Care";
CM_ SG_ 2566789630 AuxValve9RetractPortEstFlow "The value reported by the controller of flow through the retract port of an auxiliary valve of a tractor which could be based on the commanded position of the valve.  Zero percent indicates no flow, 100%, maximum flow, -100% maximum flow returning ...";
CM_ SG_ 2566789630 AuxValve9ExtendPortEstFlow "The value reported by the controller of flow through the extend port of an auxiliary valve of a tractor which could be based on the commanded position of the valve.  Zero percent indicates no flow, 100%, maximum flow, -100% maximum flow returning to ...";
CM_ BO_ 2566789374 "Auxiliary Valve Number 8 Estimated Flow
This message provides the estimated flow of specified auxiliary valve.";
CM_ SG_ 2566789374 AuxValve8Exit_reasonCode "This parameter indicates why the Auxiliary Valve 8 cannot accept remote commands or has most recently stopped accepting remote commands.
0-No reason/all clear
1-Operator presence not detected
2-Implement released control of function
3-Operator ...";
CM_ SG_ 2566789374 AuxValve8FailSafeMode "The measured state the fail safe mode of an auxiliary valve.

00 Block
01 Float
10 Error indication
11 Not available";
CM_ SG_ 2566789374 AuxValve8State "The measured state of the auxiliary valve.   With float enabled, hydraulic fluid may flow to or from the tractor as driven by the implement.

0000 Blocked
0001 Extend
0010 Retract
0011 Floating
0100-1110 Reserved
1111 Don't Care";
CM_ SG_ 2566789374 AuxValve8RetractPortEstFlow "The value reported by the controller of flow through the retract port of an auxiliary valve of a tractor which could be based on the commanded position of the valve.  Zero percent indicates no flow, 100%, maximum flow, -100% maximum flow returning ...";
CM_ SG_ 2566789374 AuxValve8ExtendPortEstFlow "The value reported by the controller of flow through the extend port of an auxiliary valve of a tractor which could be based on the commanded position of the valve.  Zero percent indicates no flow, 100%, maximum flow, -100% maximum flow returning to ...";
CM_ BO_ 2566789118 "Auxiliary Valve Number 7 Estimated Flow
This message provides the estimated flow of specified auxiliary valve.";
CM_ SG_ 2566789118 AuxValve7Exit_reasonCode "This parameter indicates why the Auxiliary Valve 7 cannot accept remote commands or has most recently stopped accepting remote commands.
0-No reason/all clear
1-Operator presence not detected
2-Implement released control of function
3-Operator ...";
CM_ SG_ 2566789118 AuxValve7FailSafeMode "The measured state the fail safe mode of an auxiliary valve.

00 Block
01 Float
10 Error indication
11 Not available";
CM_ SG_ 2566789118 AuxValve7State "The measured state of the auxiliary valve.   With float enabled, hydraulic fluid may flow to or from the tractor as driven by the implement.

0000 Blocked
0001 Extend
0010 Retract
0011 Floating
0100-1110 Reserved
1111 Don't Care";
CM_ SG_ 2566789118 AuxValve7RetractPortEstFlow "The value reported by the controller of flow through the retract port of an auxiliary valve of a tractor which could be based on the commanded position of the valve.  Zero percent indicates no flow, 100%, maximum flow, -100% maximum flow returning ...";
CM_ SG_ 2566789118 AuxValve7ExtendPortEstFlow "The value reported by the controller of flow through the extend port of an auxiliary valve of a tractor which could be based on the commanded position of the valve.  Zero percent indicates no flow, 100%, maximum flow, -100% maximum flow returning to ...";
CM_ BO_ 2566788862 "Auxiliary Valve Number 6 Estimated Flow
This message provides the estimated flow of specified auxiliary valve.";
CM_ SG_ 2566788862 AuxValve6Exit_reasonCode "This parameter indicates why the Auxiliary Valve 6 cannot accept remote commands or has most recently stopped accepting remote commands.
0-No reason/all clear
1-Operator presence not detected
2-Implement released control of function
3-Operator ...";
CM_ SG_ 2566788862 AuxValve6FailSafeMode "The measured state the fail safe mode of an auxiliary valve.

00 Block
01 Float
10 Error indication
11 Not available";
CM_ SG_ 2566788862 AuxValve6State "The measured state of the auxiliary valve.   With float enabled, hydraulic fluid may flow to or from the tractor as driven by the implement.

0000 Blocked
0001 Extend
0010 Retract
0011 Floating
0100-1110 Reserved
1111 Don't Care";
CM_ SG_ 2566788862 AuxValve6RetractPortEstFlow "The value reported by the controller of flow through the retract port of an auxiliary valve of a tractor which could be based on the commanded position of the valve.  Zero percent indicates no flow, 100%, maximum flow, -100% maximum flow returning ...";
CM_ SG_ 2566788862 AuxValve6ExtendPortEstFlow "The value reported by the controller of flow through the extend port of an auxiliary valve of a tractor which could be based on the commanded position of the valve.  Zero percent indicates no flow, 100%, maximum flow, -100% maximum flow returning to ...";
CM_ BO_ 2566788606 "Auxiliary Valve Number 5 Estimated Flow
This message provides the estimated flow of specified auxiliary valve.";
CM_ SG_ 2566788606 AuxValve5Exit_reasonCode "This parameter indicates why the Auxiliary Valve 5 cannot accept remote commands or has most recently stopped accepting remote commands.
0-No reason/all clear
1-Operator presence not detected
2-Implement released control of function
3-Operator ...";
CM_ SG_ 2566788606 AuxValve5FailSafeMode "The measured state the fail safe mode of an auxiliary valve.

00 Block
01 Float
10 Error indication
11 Not available";
CM_ SG_ 2566788606 AuxValve5State "The measured state of the auxiliary valve.   With float enabled, hydraulic fluid may flow to or from the tractor as driven by the implement.

0000 Blocked
0001 Extend
0010 Retract
0011 Floating
0100-1110 Reserved
1111 Don't Care";
CM_ SG_ 2566788606 AuxValve5RetractPortEstFlow "The value reported by the controller of flow through the retract port of an auxiliary valve of a tractor which could be based on the commanded position of the valve.  Zero percent indicates no flow, 100%, maximum flow, -100% maximum flow returning ...";
CM_ SG_ 2566788606 AuxValve5ExtendPortEstFlow "The value reported by the controller of flow through the extend port of an auxiliary valve of a tractor which could be based on the commanded position of the valve.  Zero percent indicates no flow, 100%, maximum flow, -100% maximum flow returning to ...";
CM_ BO_ 2566788350 "Auxiliary Valve Number 4 Estimated Flow
This message provides the estimated flow of specified auxiliary valve.";
CM_ SG_ 2566788350 AuxValve4Exit_reasonCode "This parameter indicates why the Auxiliary Valve 4 cannot accept remote commands or has most recently stopped accepting remote commands.
0-No reason/all clear
1-Operator presence not detected
2-Implement released control of function
3-Operator ...";
CM_ SG_ 2566788350 AuxValve4FailSafeMode "The measured state the fail safe mode of an auxiliary valve.

00 Block
01 Float
10 Error indication
11 Not available";
CM_ SG_ 2566788350 AuxValve4State "The measured state of the auxiliary valve.   With float enabled, hydraulic fluid may flow to or from the tractor as driven by the implement.

0000 Blocked
0001 Extend
0010 Retract
0011 Floating
0100-1110 Reserved
1111 Don't Care";
CM_ SG_ 2566788350 AuxValve4RetractPortEstFlow "The value reported by the controller of flow through the retract port of an auxiliary valve of a tractor which could be based on the commanded position of the valve.  Zero percent indicates no flow, 100%, maximum flow, -100% maximum flow returning ...";
CM_ SG_ 2566788350 AuxValve4ExtendPortEstFlow "The value reported by the controller of flow through the extend port of an auxiliary valve of a tractor which could be based on the commanded position of the valve.  Zero percent indicates no flow, 100%, maximum flow, -100% maximum flow returning to ...";
CM_ BO_ 2566788094 "Auxiliary Valve Number 3 Estimated Flow
This message provides the estimated flow of specified auxiliary valve.";
CM_ SG_ 2566788094 AuxValve3Exit_reasonCode "This parameter indicates why the Auxiliary Valve 3 cannot accept remote commands or has most recently stopped accepting remote commands.
0-No reason/all clear
1-Operator presence not detected
2-Implement released control of function
3-Operator ...";
CM_ SG_ 2566788094 AuxValve3FailSafeMode "The measured state the fail safe mode of an auxiliary valve.

00 Block
01 Float
10 Error indication
11 Not available";
CM_ SG_ 2566788094 AuxValve3State "The measured state of the auxiliary valve.   With float enabled, hydraulic fluid may flow to or from the tractor as driven by the implement.

0000 Blocked
0001 Extend
0010 Retract
0011 Floating
0100-1110 Reserved
1111 Don't Care";
CM_ SG_ 2566788094 AuxValve3RetractPortEstFlow "The value reported by the controller of flow through the retract port of an auxiliary valve of a tractor which could be based on the commanded position of the valve.  Zero percent indicates no flow, 100%, maximum flow, -100% maximum flow returning ...";
CM_ SG_ 2566788094 AuxValve3ExtendPortEstFlow "The value reported by the controller of flow through the extend port of an auxiliary valve of a tractor which could be based on the commanded position of the valve.  Zero percent indicates no flow, 100%, maximum flow, -100% maximum flow returning to ...";
BA_DEF_ SG_  "SigType" ENUM  "Default","Range","RangeSigned","ASCII","Discrete","Control","ReferencePGN","DTC","StringDelimiter","StringLength","StringLengthControl","MessageCounter","MessageChecksum";
BA_DEF_ SG_  "GenSigStartValue" INT 0 2147483647;
BA_DEF_ SG_  "GenSigSendType" ENUM  "Cyclic","OnWrite","OnWriteWithRepetition","OnChange","OnChangeWithRepetition","IfActive","IfActiveWithRepetition","NoSigSendType";
BA_DEF_ SG_  "GenSigILSupport" ENUM  "No","Yes";
BA_DEF_ SG_  "GenSigEVName" STRING ;
BA_DEF_ SG_  "SPN" INT 0 524287;
BA_DEF_ BO_  "TpJ1939VarDlc" ENUM  "No","Yes";
BA_DEF_ BO_  "GenMsgStartDelayTime" INT 0 100000;
BA_DEF_ BO_  "GenMsgILSupport" ENUM  "No","Yes";
BA_DEF_ BO_  "GenMsgDelayTime" INT 0 1000;
BA_DEF_ BO_  "GenMsgRequestable" INT 0 1;
BA_DEF_ BO_  "GenMsgSendType" ENUM  "cyclic","NotUsed","NotUsed","NotUsed","NotUsed","NotUsed","NotUsed","IfActive","noMsgSendType";
BA_DEF_ BO_  "VFrameFormat" ENUM  "StandardCAN","ExtendedCAN","reserved","J1939PG";
BA_DEF_ BO_  "GenMsgCycleTime" INT 0 3600000;
BA_DEF_ BO_  "SendOnChange" ENUM  "No","Yes";
BA_DEF_ SG_  "SystemSignalLongSymbol" STRING ;
BA_DEF_DEF_  "SigType" "Default";
BA_DEF_DEF_  "GenSigStartValue" 0;
BA_DEF_DEF_  "GenSigSendType" "NoSigSendType";
BA_DEF_DEF_  "GenSigILSupport" "Yes";
BA_DEF_DEF_  "GenSigEVName" "Env@Nodename_@Signame";
BA_DEF_DEF_  "SPN" 0;
BA_DEF_DEF_  "TpJ1939VarDlc" "No";
BA_DEF_DEF_  "GenMsgStartDelayTime" 0;
BA_DEF_DEF_  "GenMsgILSupport" "Yes";
BA_DEF_DEF_  "GenMsgDelayTime" 0;
BA_DEF_DEF_  "GenMsgRequestable" 1;
BA_DEF_DEF_  "GenMsgSendType" "noMsgSendType";
BA_DEF_DEF_  "VFrameFormat" "J1939PG";
BA_DEF_DEF_  "GenMsgCycleTime" 0;
BA_DEF_DEF_  "SendOnChange" "No";
BA_DEF_DEF_  "SystemSignalLongSymbol" "";
BA_ "GenMsgSendType" BO_ 2566663422 0;
BA_ "GenMsgCycleTime" BO_ 2566663422 1000;
BA_ "GenMsgSendType" BO_ 2566663166 0;
BA_ "GenMsgCycleTime" BO_ 2566663166 1000;
BA_ "GenMsgSendType" BO_ 2566662910 0;
BA_ "GenMsgCycleTime" BO_ 2566662910 10000;
BA_ "GenMsgSendType" BO_ 2566662654 0;
BA_ "GenMsgCycleTime" BO_ 2566662654 100;
BA_ "GenMsgSendType" BO_ 2566662142 0;
BA_ "GenMsgCycleTime" BO_ 2566662142 1000;
BA_ "GenMsgSendType" BO_ 2566661630 0;
BA_ "GenMsgCycleTime" BO_ 2566661630 1000;
BA_ "GenMsgSendType" BO_ 2566661374 0;
BA_ "GenMsgCycleTime" BO_ 2566661374 1000;
BA_ "GenMsgSendType" BO_ 2364593150 0;
BA_ "GenMsgCycleTime" BO_ 2364593150 100;
BA_ "GenMsgSendType" BO_ 2364592894 0;
BA_ "GenMsgCycleTime" BO_ 2364592894 100;
BA_ "GenMsgSendType" BO_ 2364592638 0;
BA_ "GenMsgCycleTime" BO_ 2364592638 100;
BA_ "GenMsgSendType" BO_ 2364592382 0;
BA_ "GenMsgCycleTime" BO_ 2364592382 1000;
BA_ "GenMsgSendType" BO_ 2364567294 0;
BA_ "GenMsgCycleTime" BO_ 2364567294 50;
BA_ "GenMsgDelayTime" BO_ 2558918398 100;
BA_ "GenMsgSendType" BO_ 2558918398 0;
BA_ "GenMsgCycleTime" BO_ 2558918398 1000;
BA_ "GenMsgSendType" BO_ 2558852862 0;
BA_ "GenMsgCycleTime" BO_ 2558852862 200;
BA_ "GenMsgDelayTime" BO_ 2558656254 100;
BA_ "GenMsgSendType" BO_ 2558656254 0;
BA_ "GenMsgCycleTime" BO_ 2558656254 1000;
BA_ "GenMsgDelayTime" BO_ 2558590718 100;
BA_ "GenMsgSendType" BO_ 2558590718 0;
BA_ "GenMsgCycleTime" BO_ 2558590718 1000;
BA_ "GenMsgDelayTime" BO_ 2350710526 10;
BA_ "GenMsgSendType" BO_ 2350710526 0;
BA_ "GenMsgCycleTime" BO_ 2350710526 100;
BA_ "TpJ1939VarDlc" BO_ 2582642430 1;
BA_ "SigType" SG_ 2566663422 TrlrBrkClprLnngClranceAxle5Right 4;
BA_ "SPN" SG_ 2566663422 TrlrBrkClprLnngClranceAxle5Right 7415;
BA_ "SigType" SG_ 2566663422 TrlrBrkClprLnngClaranceAxle5Left 4;
BA_ "SPN" SG_ 2566663422 TrlrBrkClprLnngClaranceAxle5Left 7414;
BA_ "SigType" SG_ 2566663422 TrlrBrkClprLnngClranceAxle4Right 4;
BA_ "SPN" SG_ 2566663422 TrlrBrkClprLnngClranceAxle4Right 7413;
BA_ "SigType" SG_ 2566663422 TrlrBrkClprLnngClaranceAxle4Left 4;
BA_ "SPN" SG_ 2566663422 TrlrBrkClprLnngClaranceAxle4Left 7412;
BA_ "SigType" SG_ 2566663422 TrlrBrkClprLnngClranceAxle3Right 4;
BA_ "SPN" SG_ 2566663422 TrlrBrkClprLnngClranceAxle3Right 7411;
BA_ "SigType" SG_ 2566663422 TrlrBrkClprLnngClaranceAxle3Left 4;
BA_ "SPN" SG_ 2566663422 TrlrBrkClprLnngClaranceAxle3Left 7410;
BA_ "SigType" SG_ 2566663422 TrlrBrkClprLnngClranceAxle2Right 4;
BA_ "SPN" SG_ 2566663422 TrlrBrkClprLnngClranceAxle2Right 7409;
BA_ "SigType" SG_ 2566663422 TrlrBrkClprLnngClaranceAxle2Left 4;
BA_ "SPN" SG_ 2566663422 TrlrBrkClprLnngClaranceAxle2Left 7408;
BA_ "SigType" SG_ 2566663422 TrlrBrkClprLnngClranceAxle1Right 4;
BA_ "SPN" SG_ 2566663422 TrlrBrkClprLnngClranceAxle1Right 7407;
BA_ "SigType" SG_ 2566663422 TrlrBrkClprLnngClaranceAxle1Left 4;
BA_ "SPN" SG_ 2566663422 TrlrBrkClprLnngClaranceAxle1Left 7406;
BA_ "SigType" SG_ 2566663422 TrctrBrkClprLnngClrnceAxle5Right 4;
BA_ "SPN" SG_ 2566663422 TrctrBrkClprLnngClrnceAxle5Right 7405;
BA_ "SigType" SG_ 2566663422 TrctrBrkClprLnngClranceAxle5Left 4;
BA_ "SPN" SG_ 2566663422 TrctrBrkClprLnngClranceAxle5Left 7404;
BA_ "SigType" SG_ 2566663422 TrctrBrkClprLnngClrnceAxle4Right 4;
BA_ "SPN" SG_ 2566663422 TrctrBrkClprLnngClrnceAxle4Right 7403;
BA_ "SigType" SG_ 2566663422 TrctrBrkClprLnngClranceAxle4Left 4;
BA_ "SPN" SG_ 2566663422 TrctrBrkClprLnngClranceAxle4Left 7402;
BA_ "SigType" SG_ 2566663422 TrctrBrkClprLnngClrnceAxle3Right 4;
BA_ "SPN" SG_ 2566663422 TrctrBrkClprLnngClrnceAxle3Right 7401;
BA_ "SigType" SG_ 2566663422 TrctrBrkClprLnngClranceAxle3Left 4;
BA_ "SPN" SG_ 2566663422 TrctrBrkClprLnngClranceAxle3Left 7400;
BA_ "SigType" SG_ 2566663422 TrctrBrkClprLnngClrnceAxle2Right 4;
BA_ "SPN" SG_ 2566663422 TrctrBrkClprLnngClrnceAxle2Right 7399;
BA_ "SigType" SG_ 2566663422 TrctrBrkClprLnngClranceAxle2Left 4;
BA_ "SPN" SG_ 2566663422 TrctrBrkClprLnngClranceAxle2Left 7398;
BA_ "SigType" SG_ 2566663422 TrctrBrkClprLnngClrnceAxle1Right 4;
BA_ "SPN" SG_ 2566663422 TrctrBrkClprLnngClrnceAxle1Right 7397;
BA_ "SigType" SG_ 2566663422 TrctrBrkClprLnngClranceAxle1Left 4;
BA_ "SPN" SG_ 2566663422 TrctrBrkClprLnngClranceAxle1Left 7396;
BA_ "SigType" SG_ 2566663166 CruiseCtrlAdjustedMaxSpeed 1;
BA_ "SPN" SG_ 2566663166 CruiseCtrlAdjustedMaxSpeed 7495;
BA_ "SigType" SG_ 2566663166 AppliedVehicleSpeedLimit 1;
BA_ "SPN" SG_ 2566663166 AppliedVehicleSpeedLimit 7420;
BA_ "SigType" SG_ 2566662910 TimeToFinalIndAction 1;
BA_ "SPN" SG_ 2566662910 TimeToFinalIndAction 7719;
BA_ "SigType" SG_ 2566662910 OprtrIndcmntTmTTrqueDerateLevel2 1;
BA_ "SPN" SG_ 2566662910 OprtrIndcmntTmTTrqueDerateLevel2 7428;
BA_ "SigType" SG_ 2566662910 OprtrIndcementTorqueDerateLevel2 1;
BA_ "SPN" SG_ 2566662910 OprtrIndcementTorqueDerateLevel2 7427;
BA_ "SigType" SG_ 2566662910 OprtrIndcmntTmTTrqueDerateLevel1 1;
BA_ "SPN" SG_ 2566662910 OprtrIndcmntTmTTrqueDerateLevel1 7426;
BA_ "SigType" SG_ 2566662910 OprtrIndcementTorqueDerateLevel1 1;
BA_ "SPN" SG_ 2566662910 OprtrIndcementTorqueDerateLevel1 7425;
BA_ "SPN" SG_ 2566662654 LaneMarkQualityOnTheRightSide 7482;
BA_ "SPN" SG_ 2566662654 LaneMarkQualityOnTheLeftSide 7481;
BA_ "SigType" SG_ 2566662654 LaneDepartureAngleRight 1;
BA_ "SPN" SG_ 2566662654 LaneDepartureAngleRight 7480;
BA_ "SigType" SG_ 2566662654 LaneDepartureAngleLeft 1;
BA_ "SPN" SG_ 2566662654 LaneDepartureAngleLeft 7479;
BA_ "SigType" SG_ 2566662654 RoadCurvatureBasedOnLaneMarks 1;
BA_ "SPN" SG_ 2566662654 RoadCurvatureBasedOnLaneMarks 7478;
BA_ "SigType" SG_ 2566662654 RghtDstncTLnMrkFrmVehiclesMiddle 1;
BA_ "SPN" SG_ 2566662654 RghtDstncTLnMrkFrmVehiclesMiddle 7477;
BA_ "SigType" SG_ 2566662654 LftDstncTLnMrkFromVehiclesMiddle 1;
BA_ "SPN" SG_ 2566662654 LftDstncTLnMrkFromVehiclesMiddle 7476;
BA_ "SigType" SG_ 2566662142 Ctrl2Temp 1;
BA_ "SPN" SG_ 2566662142 Ctrl2Temp 7528;
BA_ "SigType" SG_ 2566662142 Ctrl1Temp 1;
BA_ "SPN" SG_ 2566662142 Ctrl1Temp 5480;
BA_ "SigType" SG_ 2566661630 Htr2 1;
BA_ "SPN" SG_ 2566661630 Htr2 7573;
BA_ "SigType" SG_ 2566661630 Temp2 1;
BA_ "SPN" SG_ 2566661630 Temp2 7572;
BA_ "SigType" SG_ 2566661630 Volume2 1;
BA_ "SPN" SG_ 2566661630 Volume2 7530;
BA_ "SigType" SG_ 2566661374 Ctrl2Temp 1;
BA_ "SPN" SG_ 2566661374 Ctrl2Temp 7535;
BA_ "SigType" SG_ 2566661374 CtrlTemp 1;
BA_ "SPN" SG_ 2566661374 CtrlTemp 7529;
BA_ "SigType" SG_ 2566661374 Htr2 1;
BA_ "SPN" SG_ 2566661374 Htr2 7575;
BA_ "SigType" SG_ 2566661374 Temp2 1;
BA_ "SPN" SG_ 2566661374 Temp2 7574;
BA_ "SigType" SG_ 2566661374 Volume2 1;
BA_ "SPN" SG_ 2566661374 Volume2 7531;
BA_ "SigType" SG_ 2364598270 EngCyl24TimingOffset 1;
BA_ "SPN" SG_ 2364598270 EngCyl24TimingOffset 7379;
BA_ "SigType" SG_ 2364598270 EngCyl23TimingOffset 1;
BA_ "SPN" SG_ 2364598270 EngCyl23TimingOffset 7378;
BA_ "SigType" SG_ 2364598270 EngCyl22TimingOffset 1;
BA_ "SPN" SG_ 2364598270 EngCyl22TimingOffset 7377;
BA_ "SigType" SG_ 2364598270 EngCyl21TimingOffset 1;
BA_ "SPN" SG_ 2364598270 EngCyl21TimingOffset 7376;
BA_ "SigType" SG_ 2364598270 EngCyl20TimingOffset 1;
BA_ "SPN" SG_ 2364598270 EngCyl20TimingOffset 7375;
BA_ "SigType" SG_ 2364598270 EngCyl19TimingOffset 1;
BA_ "SPN" SG_ 2364598270 EngCyl19TimingOffset 7374;
BA_ "SigType" SG_ 2364598270 EngCyl18TimingOffset 1;
BA_ "SPN" SG_ 2364598270 EngCyl18TimingOffset 7373;
BA_ "SigType" SG_ 2364598270 EngCyl17TimingOffset 1;
BA_ "SPN" SG_ 2364598270 EngCyl17TimingOffset 7372;
BA_ "SigType" SG_ 2364598014 EngCyl16TimingOffset 1;
BA_ "SPN" SG_ 2364598014 EngCyl16TimingOffset 7371;
BA_ "SigType" SG_ 2364598014 EngCyl15TimingOffset 1;
BA_ "SPN" SG_ 2364598014 EngCyl15TimingOffset 7370;
BA_ "SigType" SG_ 2364598014 EngCyl14TimingOffset 1;
BA_ "SPN" SG_ 2364598014 EngCyl14TimingOffset 7369;
BA_ "SigType" SG_ 2364598014 EngCyl13TimingOffset 1;
BA_ "SPN" SG_ 2364598014 EngCyl13TimingOffset 7368;
BA_ "SigType" SG_ 2364598014 EngCyl12TimingOffset 1;
BA_ "SPN" SG_ 2364598014 EngCyl12TimingOffset 7367;
BA_ "SigType" SG_ 2364598014 EngCyl11TimingOffset 1;
BA_ "SPN" SG_ 2364598014 EngCyl11TimingOffset 7366;
BA_ "SigType" SG_ 2364598014 EngCyl10TimingOffset 1;
BA_ "SPN" SG_ 2364598014 EngCyl10TimingOffset 7365;
BA_ "SigType" SG_ 2364598014 EngCyl9TimingOffset 1;
BA_ "SPN" SG_ 2364598014 EngCyl9TimingOffset 7364;
BA_ "SigType" SG_ 2364597758 EngCyl8TimingOffset 1;
BA_ "SPN" SG_ 2364597758 EngCyl8TimingOffset 7363;
BA_ "SigType" SG_ 2364597758 EngCyl7TimingOffset 1;
BA_ "SPN" SG_ 2364597758 EngCyl7TimingOffset 7362;
BA_ "SigType" SG_ 2364597758 EngCyl6TimingOffset 1;
BA_ "SPN" SG_ 2364597758 EngCyl6TimingOffset 7361;
BA_ "SigType" SG_ 2364597758 EngCyl5TimingOffset 1;
BA_ "SPN" SG_ 2364597758 EngCyl5TimingOffset 7360;
BA_ "SigType" SG_ 2364597758 EngCyl4TimingOffset 1;
BA_ "SPN" SG_ 2364597758 EngCyl4TimingOffset 7359;
BA_ "SigType" SG_ 2364597758 EngCyl3TimingOffset 1;
BA_ "SPN" SG_ 2364597758 EngCyl3TimingOffset 7358;
BA_ "SigType" SG_ 2364597758 EngCyl2TimingOffset 1;
BA_ "SPN" SG_ 2364597758 EngCyl2TimingOffset 7357;
BA_ "SigType" SG_ 2364597758 EngCyl1TimingOffset 1;
BA_ "SPN" SG_ 2364597758 EngCyl1TimingOffset 7356;
BA_ "SigType" SG_ 2364593150 PrdctvCrsCtrlDrvlnDsnggInhibitRq 5;
BA_ "SPN" SG_ 2364593150 PrdctvCrsCtrlDrvlnDsnggInhibitRq 7430;
BA_ "SigType" SG_ 2364593150 VhclSpdCtrlOvrrideEventIndicator 5;
BA_ "SPN" SG_ 2364593150 VhclSpdCtrlOvrrideEventIndicator 7435;
BA_ "SigType" SG_ 2364593150 PrdctvCrsCtrlSpeedEventIndicator 5;
BA_ "SPN" SG_ 2364593150 PrdctvCrsCtrlSpeedEventIndicator 7434;
BA_ "SigType" SG_ 2364593150 PredictiveCruiseCtrlNextGrade 1;
BA_ "SPN" SG_ 2364593150 PredictiveCruiseCtrlNextGrade 7433;
BA_ "SigType" SG_ 2364593150 PredictiveCruiseCtrlPresentGrade 1;
BA_ "SPN" SG_ 2364593150 PredictiveCruiseCtrlPresentGrade 7432;
BA_ "SigType" SG_ 2364593150 PredictiveCruiseCtrlEventInRange 4;
BA_ "SPN" SG_ 2364593150 PredictiveCruiseCtrlEventInRange 7431;
BA_ "SigType" SG_ 2364593150 VehicleSpeedCtrlOverrideRq 5;
BA_ "SPN" SG_ 2364593150 VehicleSpeedCtrlOverrideRq 7429;
BA_ "SPN" SG_ 2364593150 PredictiveCruiseCtrlState 7317;
BA_ "SigType" SG_ 2364593150 PrdctiveCruiseCtrlSetSpeedOffset 1;
BA_ "SPN" SG_ 2364593150 PrdctiveCruiseCtrlSetSpeedOffset 7316;
BA_ "SigType" SG_ 2364592894 InAirSourceVlv 4;
BA_ "SPN" SG_ 2364592894 InAirSourceVlv 6330;
BA_ "SigType" SG_ 2364592894 EngCylHeadBypassActuator1Cmd 1;
BA_ "SPN" SG_ 2364592894 EngCylHeadBypassActuator1Cmd 7094;
BA_ "SPN" SG_ 2364592638 EngCylHdBypssActtr1OprtionStatus 7093;
BA_ "SigType" SG_ 2364592638 EngCylHeadBypassActuator1Pos 1;
BA_ "SPN" SG_ 2364592638 EngCylHeadBypassActuator1Pos 7092;
BA_ "SigType" SG_ 2364592638 EngCylHdBypssActuator1DesiredPos 1;
BA_ "SPN" SG_ 2364592638 EngCylHdBypssActuator1DesiredPos 7091;
BA_ "SigType" SG_ 2364592638 EngCylHeadBypassActuator1Temp 1;
BA_ "SPN" SG_ 2364592638 EngCylHeadBypassActuator1Temp 7090;
BA_ "SPN" SG_ 2364592638 EngCylHdBypssActuator1TempStatus 7089;
BA_ "SPN" SG_ 2364592638 EngCylHdBypssActtr1PrliminaryFMI 7088;
BA_ "SigType" SG_ 2364592382 EngCyl24ExcludeFromCombustionRq 5;
BA_ "SPN" SG_ 2364592382 EngCyl24ExcludeFromCombustionRq 7015;
BA_ "SigType" SG_ 2364592382 EngCyl23ExcludeFromCombustionRq 5;
BA_ "SPN" SG_ 2364592382 EngCyl23ExcludeFromCombustionRq 7014;
BA_ "SigType" SG_ 2364592382 EngCyl22ExcludeFromCombustionRq 5;
BA_ "SPN" SG_ 2364592382 EngCyl22ExcludeFromCombustionRq 7013;
BA_ "SigType" SG_ 2364592382 EngCyl21ExcludeFromCombustionRq 5;
BA_ "SPN" SG_ 2364592382 EngCyl21ExcludeFromCombustionRq 7012;
BA_ "SigType" SG_ 2364592382 EngCyl20ExcludeFromCombustionRq 5;
BA_ "SPN" SG_ 2364592382 EngCyl20ExcludeFromCombustionRq 7011;
BA_ "SigType" SG_ 2364592382 EngCyl19ExcludeFromCombustionRq 5;
BA_ "SPN" SG_ 2364592382 EngCyl19ExcludeFromCombustionRq 7010;
BA_ "SigType" SG_ 2364592382 EngCyl18ExcludeFromCombustionRq 5;
BA_ "SPN" SG_ 2364592382 EngCyl18ExcludeFromCombustionRq 7009;
BA_ "SigType" SG_ 2364592382 EngCyl17ExcludeFromCombustionRq 5;
BA_ "SPN" SG_ 2364592382 EngCyl17ExcludeFromCombustionRq 7008;
BA_ "SigType" SG_ 2364592382 EngCyl16ExcludeFromCombustionRq 5;
BA_ "SPN" SG_ 2364592382 EngCyl16ExcludeFromCombustionRq 7007;
BA_ "SigType" SG_ 2364592382 EngCyl15ExcludeFromCombustionRq 5;
BA_ "SPN" SG_ 2364592382 EngCyl15ExcludeFromCombustionRq 7006;
BA_ "SigType" SG_ 2364592382 EngCyl14ExcludeFromCombustionRq 5;
BA_ "SPN" SG_ 2364592382 EngCyl14ExcludeFromCombustionRq 7005;
BA_ "SigType" SG_ 2364592382 EngCyl13ExcludeFromCombustionRq 5;
BA_ "SPN" SG_ 2364592382 EngCyl13ExcludeFromCombustionRq 7004;
BA_ "SigType" SG_ 2364592382 EngCyl12ExcludeFromCombustionRq 5;
BA_ "SPN" SG_ 2364592382 EngCyl12ExcludeFromCombustionRq 7003;
BA_ "SigType" SG_ 2364592382 EngCyl11ExcludeFromCombustionRq 5;
BA_ "SPN" SG_ 2364592382 EngCyl11ExcludeFromCombustionRq 7002;
BA_ "SigType" SG_ 2364592382 EngCyl10ExcludeFromCombustionRq 5;
BA_ "SPN" SG_ 2364592382 EngCyl10ExcludeFromCombustionRq 7001;
BA_ "SigType" SG_ 2364592382 EngCyl9ExcludeFromCombustionRq 5;
BA_ "SPN" SG_ 2364592382 EngCyl9ExcludeFromCombustionRq 7000;
BA_ "SigType" SG_ 2364592382 EngCyl8ExcludeFromCombustionRq 5;
BA_ "SPN" SG_ 2364592382 EngCyl8ExcludeFromCombustionRq 6999;
BA_ "SigType" SG_ 2364592382 EngCyl7ExcludeFromCombustionRq 5;
BA_ "SPN" SG_ 2364592382 EngCyl7ExcludeFromCombustionRq 6998;
BA_ "SigType" SG_ 2364592382 EngCyl6ExcludeFromCombustionRq 5;
BA_ "SPN" SG_ 2364592382 EngCyl6ExcludeFromCombustionRq 6997;
BA_ "SigType" SG_ 2364592382 EngCyl5ExcludeFromCombustionRq 5;
BA_ "SPN" SG_ 2364592382 EngCyl5ExcludeFromCombustionRq 6996;
BA_ "SigType" SG_ 2364592382 EngCyl4ExcludeFromCombustionRq 5;
BA_ "SPN" SG_ 2364592382 EngCyl4ExcludeFromCombustionRq 6995;
BA_ "SigType" SG_ 2364592382 EngCyl3ExcludeFromCombustionRq 5;
BA_ "SPN" SG_ 2364592382 EngCyl3ExcludeFromCombustionRq 6994;
BA_ "SigType" SG_ 2364592382 EngCyl2ExcludeFromCombustionRq 5;
BA_ "SPN" SG_ 2364592382 EngCyl2ExcludeFromCombustionRq 6993;
BA_ "SigType" SG_ 2364592382 EngCyl1ExcludeFromCombustionRq 5;
BA_ "SPN" SG_ 2364592382 EngCyl1ExcludeFromCombustionRq 6992;
BA_ "SigType" SG_ 2364592382 NmbrOfEngCylndrsTExcldFrmCmbston 1;
BA_ "SPN" SG_ 2364592382 NmbrOfEngCylndrsTExcldFrmCmbston 6991;
BA_ "SigType" SG_ 2364567294 EngFlInjctnPump2FuelCtrlValveCmd 1;
BA_ "SPN" SG_ 2364567294 EngFlInjctnPump2FuelCtrlValveCmd 6720;
BA_ "SigType" SG_ 2364567294 EngFlInjctnPump1FuelCtrlValveCmd 1;
BA_ "SPN" SG_ 2364567294 EngFlInjctnPump1FuelCtrlValveCmd 6719;
BA_ "SigType" SG_ 2558918398 TransAutoNeutralEnableSw 5;
BA_ "SPN" SG_ 2558918398 TransAutoNeutralEnableSw 7694;
BA_ "SigType" SG_ 2558918398 AFTRegenEngSpdAllowedSw 4;
BA_ "SPN" SG_ 2558918398 AFTRegenEngSpdAllowedSw 7580;
BA_ "SigType" SG_ 2558918398 ElevatedEngSpdAllowedSw 4;
BA_ "SPN" SG_ 2558918398 ElevatedEngSpdAllowedSw 7579;
BA_ "SigType" SG_ 2558918398 PrdctvCriseCtrlMaxNegativeOffset 1;
BA_ "SPN" SG_ 2558918398 PrdctvCriseCtrlMaxNegativeOffset 7439;
BA_ "SigType" SG_ 2558918398 PrdctvCriseCtrlMaxPositiveOffset 1;
BA_ "SPN" SG_ 2558918398 PrdctvCriseCtrlMaxPositiveOffset 7438;
BA_ "SigType" SG_ 2558918398 PrdctiveCruiseCtrlDeactivationRq 4;
BA_ "SPN" SG_ 2558918398 PrdctiveCruiseCtrlDeactivationRq 7437;
BA_ "SigType" SG_ 2558918398 PredictiveCruiseCtrlEnableSwitch 4;
BA_ "SPN" SG_ 2558918398 PredictiveCruiseCtrlEnableSwitch 7436;
BA_ "SigType" SG_ 2558918398 HtExchngerDebrisPurgeForceSwitch 4;
BA_ "SPN" SG_ 2558918398 HtExchngerDebrisPurgeForceSwitch 7034;
BA_ "SigType" SG_ 2558918398 HtExchngrDbrisPurgeInhibitSwitch 4;
BA_ "SPN" SG_ 2558918398 HtExchngrDbrisPurgeInhibitSwitch 7033;
BA_ "SigType" SG_ 2558918398 SCROprtrInducementOverrideSwitch 5;
BA_ "SPN" SG_ 2558918398 SCROprtrInducementOverrideSwitch 6881;
BA_ "SigType" SG_ 2558918398 PerformanceBiasSelection 1;
BA_ "SPN" SG_ 2558918398 PerformanceBiasSelection 6874;
BA_ "SigType" SG_ 2558918398 EngFan2RequestedPercentSpeed 1;
BA_ "SPN" SG_ 2558918398 EngFan2RequestedPercentSpeed 6730;
BA_ "SigType" SG_ 2558852862 ExhVelocity 1;
BA_ "SPN" SG_ 2558852862 ExhVelocity 6829;
BA_ "SigType" SG_ 2558852862 ExhTemp 1;
BA_ "SPN" SG_ 2558852862 ExhTemp 6785;
BA_ "SigType" SG_ 2558852862 Dewpoint 5;
BA_ "SPN" SG_ 2558852862 Dewpoint 6784;
BA_ "SigType" SG_ 2558852862 RegenReq 5;
BA_ "SPN" SG_ 2558852862 RegenReq 6783;
BA_ "SigType" SG_ 2558852862 ShutdownReq 5;
BA_ "SPN" SG_ 2558852862 ShutdownReq 6782;
BA_ "SigType" SG_ 2558787326 PayloadCorrectionFactorCmd 1;
BA_ "SPN" SG_ 2558787326 PayloadCorrectionFactorCmd 6873;
BA_ "SigType" SG_ 2558787326 PayloadCalibCommandedWeight 1;
BA_ "SPN" SG_ 2558787326 PayloadCalibCommandedWeight 6872;
BA_ "SPN" SG_ 2558787326 PayloadCalibSetPointCmd 6871;
BA_ "SigType" SG_ 2558721790 SnsrEnableSetting 5;
BA_ "SPN" SG_ 2558721790 SnsrEnableSetting 7587;
BA_ "SigType" SG_ 2558721790 OverTempSetting 1;
BA_ "SPN" SG_ 2558721790 OverTempSetting 6978;
BA_ "SigType" SG_ 2558721790 OvrPrssPrcentageThresholdSetting 1;
BA_ "SPN" SG_ 2558721790 OvrPrssPrcentageThresholdSetting 6977;
BA_ "SigType" SG_ 2558721790 ExtrmUndrPrssPrcntgThrshldStting 1;
BA_ "SPN" SG_ 2558721790 ExtrmUndrPrssPrcntgThrshldStting 6976;
BA_ "SigType" SG_ 2558721790 UndrPrssPrcntageThresholdSetting 1;
BA_ "SPN" SG_ 2558721790 UndrPrssPrcntageThresholdSetting 6975;
BA_ "SigType" SG_ 2558721790 ColdInflationPressSetting 1;
BA_ "SPN" SG_ 2558721790 ColdInflationPressSetting 6974;
BA_ "SPN" SG_ 2558721790 TireLocation 6973;
BA_ "SPN" SG_ 2558656254 RqToPermitDEFDosingTestInjection 7516;
BA_ "SigType" SG_ 2558656254 RqToPermitDEFHydStiffnessCheck 5;
BA_ "SPN" SG_ 2558656254 RqToPermitDEFHydStiffnessCheck 7515;
BA_ "SigType" SG_ 2558656254 ThermalManagementInhReq 5;
BA_ "SPN" SG_ 2558656254 ThermalManagementInhReq 7331;
BA_ "SigType" SG_ 2558590718 ShutdownCmd 5;
BA_ "SPN" SG_ 2558590718 ShutdownCmd 7560;
BA_ "SigType" SG_ 2558590718 PropulsionDisableReq 5;
BA_ "SPN" SG_ 2558590718 PropulsionDisableReq 7558;
BA_ "SigType" SG_ 2558590718 HybrdSystmRgnrtvBrakingDisableRq 5;
BA_ "SPN" SG_ 2558590718 HybrdSystmRgnrtvBrakingDisableRq 7559;
BA_ "SigType" SG_ 2558590718 HybridSystemProtectionOverrideRq 5;
BA_ "SPN" SG_ 2558590718 HybridSystemProtectionOverrideRq 7557;
BA_ "SigType" SG_ 2350776062 EngTimingAdvance 1;
BA_ "SPN" SG_ 2350776062 EngTimingAdvance 7355;
BA_ "SPN" SG_ 2350710526 MessageChecksum 7042;
BA_ "SigType" SG_ 2350710526 TransRequestedTorque_TorqueLimit 1;
BA_ "SPN" SG_ 2350710526 TransRequestedTorque_TorqueLimit 7040;
BA_ "SigType" SG_ 2350710526 TransRequestedOutputShaftSpeed 1;
BA_ "GenSigStartValue" SG_ 2350710526 TransRequestedOutputShaftSpeed 2;
BA_ "SPN" SG_ 2350710526 TransRequestedOutputShaftSpeed 7039;
BA_ "SPN" SG_ 2350710526 MessageCounter 7041;
BA_ "SigType" SG_ 2350710526 TransOverrideCtrlModePriority 5;
BA_ "SPN" SG_ 2350710526 TransOverrideCtrlModePriority 7038;
BA_ "SigType" SG_ 2350710526 TransOverrideCtrlMode 5;
BA_ "SPN" SG_ 2350710526 TransOverrideCtrlMode 7037;
BA_ "SPN" SG_ 2582642430 ManufacturerSpecificInformation 3328;
BA_ "SigType" SG_ 2566801918 GroundBasedDirection 4;
BA_ "SPN" SG_ 2566801918 GroundBasedDirection 1861;
BA_ "SPN" SG_ 2566801918 GroundBasedImplementDistance 1860;
BA_ "SPN" SG_ 2566801918 GroundBasedImplementSpeed 1859;
BA_ "SigType" SG_ 2566801662 KeySwitchNOTOFF 4;
BA_ "SPN" SG_ 2566801662 KeySwitchNOTOFF 1865;
BA_ "SigType" SG_ 2566801662 WheelBasedDirection 4;
BA_ "SPN" SG_ 2566801662 WheelBasedDirection 1864;
BA_ "SPN" SG_ 2566801662 MaxTimeOfTractorPower 1866;
BA_ "SPN" SG_ 2566801662 WheelBasedDistance 1863;
BA_ "SPN" SG_ 2566801662 WheelBasedSpeed 1862;
BA_ "SigType" SG_ 2566801406 ImplementInWorkState 4;
BA_ "SPN" SG_ 2566801406 ImplementInWorkState 7447;
BA_ "SigType" SG_ 2566801406 ImplementTransportState 4;
BA_ "SPN" SG_ 2566801406 ImplementTransportState 1869;
BA_ "SigType" SG_ 2566801406 ImplementParkState 4;
BA_ "SPN" SG_ 2566801406 ImplementParkState 1870;
BA_ "SigType" SG_ 2566801406 ImplementWorkState 4;
BA_ "SPN" SG_ 2566801406 ImplementWorkState 1871;
BA_ "SigType" SG_ 2566801406 MaintainECUPower 4;
BA_ "SPN" SG_ 2566801406 MaintainECUPower 1867;
BA_ "SigType" SG_ 2566801406 MaintainAcuatorPower 4;
BA_ "SPN" SG_ 2566801406 MaintainAcuatorPower 1868;
BA_ "SPN" SG_ 2566801150 FrontDraft 1878;
BA_ "SPN" SG_ 2566801150 FrontNominalLowerLinkForce 1880;
BA_ "SigType" SG_ 2566801150 FrontHitchInworkIndication 4;
BA_ "SPN" SG_ 2566801150 FrontHitchInworkIndication 1876;
BA_ "SPN" SG_ 2566801150 FrontHitchPos 1872;
BA_ "SPN" SG_ 2566800894 RearHitchExit_reasonCode 5819;
BA_ "SPN" SG_ 2566800894 RearDraft 1879;
BA_ "SPN" SG_ 2566800894 RearNominalLowerLinkForce 1881;
BA_ "SigType" SG_ 2566800894 RearHitchInworkIndication 4;
BA_ "SPN" SG_ 2566800894 RearHitchInworkIndication 1877;
BA_ "SPN" SG_ 2566800894 RearHitchPos 1873;
BA_ "SPN" SG_ 2566800638 FrontPTOExit_reasonCode 5817;
BA_ "SPN" SG_ 2566800638 FrontHitchExit_reasonCode 5816;
BA_ "SigType" SG_ 2566800638 FrontPowerTakeOffEngagement 4;
BA_ "SPN" SG_ 2566800638 FrontPowerTakeOffEngagement 1888;
BA_ "SigType" SG_ 2566800638 FrontPowerTakeOffMode 4;
BA_ "SPN" SG_ 2566800638 FrontPowerTakeOffMode 1889;
BA_ "SigType" SG_ 2566800638 FrontPowerTakeOffEconomyMode 4;
BA_ "SPN" SG_ 2566800638 FrontPowerTakeOffEconomyMode 1891;
BA_ "SPN" SG_ 2566800638 FrontPTOOutputShaftSpeedSetPoint 1884;
BA_ "SPN" SG_ 2566800638 FrontPTOOutputShaftSpeed 1882;
BA_ "SPN" SG_ 2566800382 RearPTOExit_reasonCode 5820;
BA_ "SigType" SG_ 2566800382 RearPowerTakeOffEngagement 4;
BA_ "SPN" SG_ 2566800382 RearPowerTakeOffEngagement 2408;
BA_ "SigType" SG_ 2566800382 RearPowerTakeOffMode 4;
BA_ "SPN" SG_ 2566800382 RearPowerTakeOffMode 1890;
BA_ "SigType" SG_ 2566800382 RearPowerTakeOffEconomyMode 4;
BA_ "SPN" SG_ 2566800382 RearPowerTakeOffEconomyMode 1892;
BA_ "SPN" SG_ 2566800382 RearPTOOutputShaftSpeedSetPoint 1885;
BA_ "SPN" SG_ 2566800382 RearPTOOutputShaftSpeed 1883;
BA_ "SigType" SG_ 2566800126 FrontPowerTakeOffModeCmd 4;
BA_ "SPN" SG_ 2566800126 FrontPowerTakeOffModeCmd 1895;
BA_ "SigType" SG_ 2566800126 RearPowerTakeOffModeCmd 4;
BA_ "SPN" SG_ 2566800126 RearPowerTakeOffModeCmd 1896;
BA_ "SigType" SG_ 2566800126 FrontPowerTakeOffEconomyModeCmd 4;
BA_ "SPN" SG_ 2566800126 FrontPowerTakeOffEconomyModeCmd 1897;
BA_ "SigType" SG_ 2566800126 RearPowerTakeOffEconomyModeCmd 4;
BA_ "SPN" SG_ 2566800126 RearPowerTakeOffEconomyModeCmd 1898;
BA_ "SigType" SG_ 2566800126 FrontPowerTakeOffEngagementCmd 4;
BA_ "SPN" SG_ 2566800126 FrontPowerTakeOffEngagementCmd 1893;
BA_ "SigType" SG_ 2566800126 RearPowerTakeOffEngagementCmd 4;
BA_ "SPN" SG_ 2566800126 RearPowerTakeOffEngagementCmd 1894;
BA_ "SPN" SG_ 2566800126 RrPTOOutputShaftSpeedSetPointCmd 1887;
BA_ "SPN" SG_ 2566800126 FrntPTOOtptShaftSpeedSetPointCmd 1886;
BA_ "SPN" SG_ 2566800126 RearHitchPosCmd 1875;
BA_ "SPN" SG_ 2566800126 FrontHitchPosCmd 1874;
BA_ "SigType" SG_ 2566799358 AuxValve15FailSafeModeCmd 4;
BA_ "SPN" SG_ 2566799358 AuxValve15FailSafeModeCmd 2345;
BA_ "SPN" SG_ 2566799358 AuxValve15StateCmd 2344;
BA_ "SPN" SG_ 2566799358 AuxValve15PortFlowCmd 2343;
BA_ "SigType" SG_ 2566799102 AuxValve14FailSafeModeCmd 4;
BA_ "SPN" SG_ 2566799102 AuxValve14FailSafeModeCmd 2333;
BA_ "SPN" SG_ 2566799102 AuxValve14StateCmd 2332;
BA_ "SPN" SG_ 2566799102 AuxValve14PortFlowCmd 2331;
BA_ "SigType" SG_ 2566798846 AuxValve13FailSafeModeCmd 4;
BA_ "SPN" SG_ 2566798846 AuxValve13FailSafeModeCmd 2321;
BA_ "SPN" SG_ 2566798846 AuxValve13StateCmd 2320;
BA_ "SPN" SG_ 2566798846 AuxValve13PortFlowCmd 2319;
BA_ "SigType" SG_ 2566798590 AuxValve12FailSafeModeCmd 4;
BA_ "SPN" SG_ 2566798590 AuxValve12FailSafeModeCmd 2309;
BA_ "SPN" SG_ 2566798590 AuxValve12StateCmd 2308;
BA_ "SPN" SG_ 2566798590 AuxValve12PortFlowCmd 2307;
BA_ "SigType" SG_ 2566798334 AuxValve11FailSafeModeCmd 4;
BA_ "SPN" SG_ 2566798334 AuxValve11FailSafeModeCmd 2297;
BA_ "SPN" SG_ 2566798334 AuxValve11StateCmd 2296;
BA_ "SPN" SG_ 2566798334 AuxValve11PortFlowCmd 2295;
BA_ "SigType" SG_ 2566798078 AuxValve10FailSafeModeCmd 4;
BA_ "SPN" SG_ 2566798078 AuxValve10FailSafeModeCmd 2285;
BA_ "SPN" SG_ 2566798078 AuxValve10StateCmd 2284;
BA_ "SPN" SG_ 2566798078 AuxValve10PortFlowCmd 2283;
BA_ "SigType" SG_ 2566797822 AuxValve9FailSafeModeCmd 4;
BA_ "SPN" SG_ 2566797822 AuxValve9FailSafeModeCmd 2273;
BA_ "SPN" SG_ 2566797822 AuxValve9StateCmd 2272;
BA_ "SPN" SG_ 2566797822 AuxValve9PortFlowCmd 2271;
BA_ "SigType" SG_ 2566797566 AuxValve8FailSafeModeCmd 4;
BA_ "SPN" SG_ 2566797566 AuxValve8FailSafeModeCmd 2261;
BA_ "SPN" SG_ 2566797566 AuxValve8StateCmd 2260;
BA_ "SPN" SG_ 2566797566 AuxValve8PortFlowCmd 2259;
BA_ "SigType" SG_ 2566797310 AuxValve7FailSafeModeCmd 4;
BA_ "SPN" SG_ 2566797310 AuxValve7FailSafeModeCmd 1993;
BA_ "SPN" SG_ 2566797310 AuxValve7StateCmd 1992;
BA_ "SPN" SG_ 2566797310 AuxValve7PortFlowCmd 1991;
BA_ "SigType" SG_ 2566797054 AuxValve6FailSafeModeCmd 4;
BA_ "SPN" SG_ 2566797054 AuxValve6FailSafeModeCmd 1981;
BA_ "SPN" SG_ 2566797054 AuxValve6StateCmd 1980;
BA_ "SPN" SG_ 2566797054 AuxValve6PortFlowCmd 1979;
BA_ "SigType" SG_ 2566796798 AuxValve5FailSafeModeCmd 4;
BA_ "SPN" SG_ 2566796798 AuxValve5FailSafeModeCmd 1969;
BA_ "SPN" SG_ 2566796798 AuxValve5StateCmd 1968;
BA_ "SPN" SG_ 2566796798 AuxValve5PortFlowCmd 1967;
BA_ "SigType" SG_ 2566796542 AuxValve4FailSafeModeCmd 4;
BA_ "SPN" SG_ 2566796542 AuxValve4FailSafeModeCmd 1957;
BA_ "SPN" SG_ 2566796542 AuxValve4StateCmd 1956;
BA_ "SPN" SG_ 2566796542 AuxValve4PortFlowCmd 1955;
BA_ "SigType" SG_ 2566796286 AuxValve3FailSafeModeCmd 4;
BA_ "SPN" SG_ 2566796286 AuxValve3FailSafeModeCmd 1945;
BA_ "SPN" SG_ 2566796286 AuxValve3StateCmd 1944;
BA_ "SPN" SG_ 2566796286 AuxValve3PortFlowCmd 1943;
BA_ "SigType" SG_ 2566796030 AuxValve2FailSafeModeCmd 4;
BA_ "SPN" SG_ 2566796030 AuxValve2FailSafeModeCmd 1933;
BA_ "SPN" SG_ 2566796030 AuxValve2StateCmd 1932;
BA_ "SPN" SG_ 2566796030 AuxValve2PortFlowCmd 1931;
BA_ "SigType" SG_ 2566795774 AuxValve1FailSafeModeCmd 4;
BA_ "SPN" SG_ 2566795774 AuxValve1FailSafeModeCmd 1921;
BA_ "SPN" SG_ 2566795774 AuxValve1StateCmd 1920;
BA_ "SPN" SG_ 2566795774 AuxValve1PortFlowCmd 1919;
BA_ "SigType" SG_ 2566795518 AuxValve0FailSafeModeCmd 4;
BA_ "SPN" SG_ 2566795518 AuxValve0FailSafeModeCmd 1909;
BA_ "SPN" SG_ 2566795518 AuxValve0StateCmd 1908;
BA_ "SPN" SG_ 2566795518 AuxValve0PortFlowCmd 1907;
BA_ "SPN" SG_ 2566795262 AuxValve15ReturnPortPress 2342;
BA_ "SPN" SG_ 2566795262 AuxValve15RetractPortPress 2341;
BA_ "SPN" SG_ 2566795262 AuxValve15ExtendPortPress 2340;
BA_ "SPN" SG_ 2566795262 AxValve15RetractPortMeasuredFlow 2336;
BA_ "SPN" SG_ 2566795262 AuxValve15ExtendPortMeasuredFlow 2335;
BA_ "SPN" SG_ 2566795006 AuxValve14ReturnPortPress 2330;
BA_ "SPN" SG_ 2566795006 AuxValve14RetractPortPress 2329;
BA_ "SPN" SG_ 2566795006 AuxValve14ExtendPortPress 2328;
BA_ "SPN" SG_ 2566795006 AxValve14RetractPortMeasuredFlow 2324;
BA_ "SPN" SG_ 2566795006 AuxValve14ExtendPortMeasuredFlow 2323;
BA_ "SPN" SG_ 2566794750 AuxValve13ReturnPortPress 2318;
BA_ "SPN" SG_ 2566794750 AuxValve13RetractPortPress 2317;
BA_ "SPN" SG_ 2566794750 AuxValve13ExtendPortPress 2316;
BA_ "SPN" SG_ 2566794750 AxValve13RetractPortMeasuredFlow 2312;
BA_ "SPN" SG_ 2566794750 AuxValve13ExtendPortMeasuredFlow 2311;
BA_ "SPN" SG_ 2566794494 AuxValve12ReturnPortPress 2306;
BA_ "SPN" SG_ 2566794494 AuxValve12RetractPortPress 2305;
BA_ "SPN" SG_ 2566794494 AuxValve12ExtendPortPress 2304;
BA_ "SPN" SG_ 2566794494 AxValve12RetractPortMeasuredFlow 2300;
BA_ "SPN" SG_ 2566794494 AuxValve12ExtendPortMeasuredFlow 2299;
BA_ "SPN" SG_ 2566794238 AuxValve11ReturnPortPress 2294;
BA_ "SPN" SG_ 2566794238 AuxValve11RetractPortPress 2293;
BA_ "SPN" SG_ 2566794238 AuxValve11ExtendPortPress 2292;
BA_ "SPN" SG_ 2566794238 AxValve11RetractPortMeasuredFlow 2288;
BA_ "SPN" SG_ 2566794238 AuxValve11ExtendPortMeasuredFlow 2287;
BA_ "SPN" SG_ 2566793982 AuxValve10ReturnPortPress 2282;
BA_ "SPN" SG_ 2566793982 AuxValve10RetractPortPress 2281;
BA_ "SPN" SG_ 2566793982 AuxValve10ExtendPortPress 2280;
BA_ "SPN" SG_ 2566793982 AxValve10RetractPortMeasuredFlow 2276;
BA_ "SPN" SG_ 2566793982 AuxValve10ExtendPortMeasuredFlow 2275;
BA_ "SPN" SG_ 2566793726 AuxValve9ReturnPortPress 2270;
BA_ "SPN" SG_ 2566793726 AuxValve9RetractPortPress 2269;
BA_ "SPN" SG_ 2566793726 AuxValve9ExtendPortPress 2268;
BA_ "SPN" SG_ 2566793726 AuxValve9RetractPortMeasuredFlow 2264;
BA_ "SPN" SG_ 2566793726 AuxValve9ExtendPortMeasuredFlow 2263;
BA_ "SPN" SG_ 2566793470 AuxValve8ReturnPortPress 2258;
BA_ "SPN" SG_ 2566793470 AuxValve8RetractPortPress 2257;
BA_ "SPN" SG_ 2566793470 AuxValve8ExtendPortPress 2256;
BA_ "SPN" SG_ 2566793470 AuxValve8RetractPortMeasuredFlow 1996;
BA_ "SPN" SG_ 2566793470 AuxValve8ExtendPortMeasuredFlow 1995;
BA_ "SPN" SG_ 2566793214 AuxValve7ReturnPortPress 1990;
BA_ "SPN" SG_ 2566793214 AuxValve7RetractPortPress 1989;
BA_ "SPN" SG_ 2566793214 AuxValve7ExtendPortPress 1988;
BA_ "SPN" SG_ 2566793214 AuxValve7RetractPortMeasuredFlow 1984;
BA_ "SPN" SG_ 2566793214 AuxValve7ExtendPortMeasuredFlow 1983;
BA_ "SPN" SG_ 2566792958 AuxValve6ReturnPortPress 1978;
BA_ "SPN" SG_ 2566792958 AuxValve6RetractPortPress 1977;
BA_ "SPN" SG_ 2566792958 AuxValve6ExtendPortPress 1976;
BA_ "SPN" SG_ 2566792958 AuxValve6RetractPortMeasuredFlow 1972;
BA_ "SPN" SG_ 2566792958 AuxValve6ExtendPortMeasuredFlow 1971;
BA_ "SPN" SG_ 2566792702 AuxValve5ReturnPortPress 1966;
BA_ "SPN" SG_ 2566792702 AuxValve5RetractPortPress 1965;
BA_ "SPN" SG_ 2566792702 AuxValve5ExtendPortPress 1964;
BA_ "SPN" SG_ 2566792702 AuxValve5RetractPortMeasuredFlow 1960;
BA_ "SPN" SG_ 2566792702 AuxValve5ExtendPortMeasuredFlow 1959;
BA_ "SPN" SG_ 2566792446 AuxValve4ReturnPortPress 1954;
BA_ "SPN" SG_ 2566792446 AuxValve4RetractPortPress 1953;
BA_ "SPN" SG_ 2566792446 AuxValve4ExtendPortPress 1952;
BA_ "SPN" SG_ 2566792446 AuxValve4RetractPortMeasuredFlow 1948;
BA_ "SPN" SG_ 2566792446 AuxValve4ExtendPortMeasuredFlow 1947;
BA_ "SPN" SG_ 2566792190 AuxValve3ReturnPortPress 1942;
BA_ "SPN" SG_ 2566792190 AuxValve3RetractPortPress 1941;
BA_ "SPN" SG_ 2566792190 AuxValve3ExtendPortPress 1940;
BA_ "SPN" SG_ 2566792190 AuxValve3RetractPortMeasuredFlow 1936;
BA_ "SPN" SG_ 2566792190 AuxValve3ExtendPortMeasuredFlow 1935;
BA_ "SPN" SG_ 2566791934 AuxValve2ReturnPortPress 1930;
BA_ "SPN" SG_ 2566791934 AuxValve2RetractPortPress 1929;
BA_ "SPN" SG_ 2566791934 AuxValve2ExtendPortPress 1928;
BA_ "SPN" SG_ 2566791934 AuxValve2RetractPortMeasuredFlow 1924;
BA_ "SPN" SG_ 2566791934 AuxValve2ExtendPortMeasuredFlow 1923;
BA_ "SPN" SG_ 2566791678 AuxValve1ReturnPortPress 1918;
BA_ "SPN" SG_ 2566791678 AuxValve1RetractPortPress 1917;
BA_ "SPN" SG_ 2566791678 AuxValve1ExtendPortPress 1916;
BA_ "SPN" SG_ 2566791678 AuxValve1RetractPortMeasuredFlow 1912;
BA_ "SPN" SG_ 2566791678 AuxValve1ExtendPortMeasuredFlow 1911;
BA_ "SPN" SG_ 2566791422 AuxValve0ReturnPortPress 1906;
BA_ "SPN" SG_ 2566791422 AuxValve0RetractPortPress 1905;
BA_ "SPN" SG_ 2566791422 AuxValve0ExtendPortPress 1904;
BA_ "SPN" SG_ 2566791422 AuxValve0RetractPortMeasuredFlow 1900;
BA_ "SPN" SG_ 2566791422 AuxValve0ExtendPortMeasuredFlow 1899;
BA_ "SPN" SG_ 2566791166 AuxValve15Exit_reasonCode 5815;
BA_ "SigType" SG_ 2566791166 AuxValve15FailSafeMode 4;
BA_ "SPN" SG_ 2566791166 AuxValve15FailSafeMode 2346;
BA_ "SPN" SG_ 2566791166 AuxValve15State 2339;
BA_ "SPN" SG_ 2566791166 AuxValve15RetractPortEstFlow 2338;
BA_ "SPN" SG_ 2566791166 AuxValve15ExtendPortEstFlow 2337;
BA_ "SPN" SG_ 2566790910 AuxValve14Exit_reasonCode 5814;
BA_ "SigType" SG_ 2566790910 AuxValve14FailSafeMode 4;
BA_ "SPN" SG_ 2566790910 AuxValve14FailSafeMode 2334;
BA_ "SPN" SG_ 2566790910 AuxValve14State 2327;
BA_ "SPN" SG_ 2566790910 AuxValve14RetractPortEstFlow 2326;
BA_ "SPN" SG_ 2566790910 AuxValve14ExtendPortEstFlow 2325;
BA_ "SPN" SG_ 2566790654 AuxValve13Exit_reasonCode 5813;
BA_ "SigType" SG_ 2566790654 AuxValve13FailSafeMode 4;
BA_ "SPN" SG_ 2566790654 AuxValve13FailSafeMode 2322;
BA_ "SPN" SG_ 2566790654 AuxValve13State 2315;
BA_ "SPN" SG_ 2566790654 AuxValve13RetractPortEstFlow 2314;
BA_ "SPN" SG_ 2566790654 AuxValve13ExtendPortEstFlow 2313;
BA_ "SPN" SG_ 2566790398 AuxValve12Exit_reasonCode 5812;
BA_ "SigType" SG_ 2566790398 AuxValve12FailSafeMode 4;
BA_ "SPN" SG_ 2566790398 AuxValve12FailSafeMode 2310;
BA_ "SPN" SG_ 2566790398 AuxValve12State 2303;
BA_ "SPN" SG_ 2566790398 AuxValve12RetractPortEstFlow 2302;
BA_ "SPN" SG_ 2566790398 AuxValve12ExtendPortEstFlow 2301;
BA_ "SPN" SG_ 2566790142 AuxValve11Exit_reasonCode 5811;
BA_ "SigType" SG_ 2566790142 AuxValve11FailSafeMode 4;
BA_ "SPN" SG_ 2566790142 AuxValve11FailSafeMode 2298;
BA_ "SPN" SG_ 2566790142 AuxValve11State 2291;
BA_ "SPN" SG_ 2566790142 AuxValve11RetractPortEstFlow 2290;
BA_ "SPN" SG_ 2566790142 AuxValve11ExtendPortEstFlow 2289;
BA_ "SPN" SG_ 2566789886 AuxValve10Exit_reasonCode 5810;
BA_ "SigType" SG_ 2566789886 AuxValve10FailSafeMode 4;
BA_ "SPN" SG_ 2566789886 AuxValve10FailSafeMode 2286;
BA_ "SPN" SG_ 2566789886 AuxValve10State 2279;
BA_ "SPN" SG_ 2566789886 AuxValve10RetractPortEstFlow 2278;
BA_ "SPN" SG_ 2566789886 AuxValve10ExtendPortEstFlow 2277;
BA_ "SPN" SG_ 2566789630 AuxValve9Exit_reasonCode 5809;
BA_ "SigType" SG_ 2566789630 AuxValve9FailSafeMode 4;
BA_ "SPN" SG_ 2566789630 AuxValve9FailSafeMode 2274;
BA_ "SPN" SG_ 2566789630 AuxValve9State 2267;
BA_ "SPN" SG_ 2566789630 AuxValve9RetractPortEstFlow 2266;
BA_ "SPN" SG_ 2566789630 AuxValve9ExtendPortEstFlow 2265;
BA_ "SPN" SG_ 2566789374 AuxValve8Exit_reasonCode 5808;
BA_ "SigType" SG_ 2566789374 AuxValve8FailSafeMode 4;
BA_ "SPN" SG_ 2566789374 AuxValve8FailSafeMode 2262;
BA_ "SPN" SG_ 2566789374 AuxValve8State 1999;
BA_ "SPN" SG_ 2566789374 AuxValve8RetractPortEstFlow 1998;
BA_ "SPN" SG_ 2566789374 AuxValve8ExtendPortEstFlow 1997;
BA_ "SPN" SG_ 2566789118 AuxValve7Exit_reasonCode 5807;
BA_ "SigType" SG_ 2566789118 AuxValve7FailSafeMode 4;
BA_ "SPN" SG_ 2566789118 AuxValve7FailSafeMode 1994;
BA_ "SPN" SG_ 2566789118 AuxValve7State 1987;
BA_ "SPN" SG_ 2566789118 AuxValve7RetractPortEstFlow 1986;
BA_ "SPN" SG_ 2566789118 AuxValve7ExtendPortEstFlow 1985;
BA_ "SPN" SG_ 2566788862 AuxValve6Exit_reasonCode 5806;
BA_ "SigType" SG_ 2566788862 AuxValve6FailSafeMode 4;
BA_ "SPN" SG_ 2566788862 AuxValve6FailSafeMode 1982;
BA_ "SPN" SG_ 2566788862 AuxValve6State 1975;
BA_ "SPN" SG_ 2566788862 AuxValve6RetractPortEstFlow 1974;
BA_ "SPN" SG_ 2566788862 AuxValve6ExtendPortEstFlow 1973;
BA_ "SPN" SG_ 2566788606 AuxValve5Exit_reasonCode 5805;
BA_ "SigType" SG_ 2566788606 AuxValve5FailSafeMode 4;
BA_ "SPN" SG_ 2566788606 AuxValve5FailSafeMode 1970;
BA_ "SPN" SG_ 2566788606 AuxValve5State 1963;
BA_ "SPN" SG_ 2566788606 AuxValve5RetractPortEstFlow 1962;
BA_ "SPN" SG_ 2566788606 AuxValve5ExtendPortEstFlow 1961;
BA_ "SPN" SG_ 2566788350 AuxValve4Exit_reasonCode 5804;
BA_ "SigType" SG_ 2566788350 AuxValve4FailSafeMode 4;
BA_ "SPN" SG_ 2566788350 AuxValve4FailSafeMode 1958;
BA_ "SPN" SG_ 2566788350 AuxValve4State 1951;
BA_ "SPN" SG_ 2566788350 AuxValve4RetractPortEstFlow 1950;
BA_ "SPN" SG_ 2566788350 AuxValve4ExtendPortEstFlow 1949;
BA_ "SPN" SG_ 2566788094 AuxValve3Exit_reasonCode 5803;
BA_ "SigType" SG_ 2566788094 AuxValve3FailSafeMode 4;
BA_ "SPN" SG_ 2566788094 AuxValve3FailSafeMode 1946;
BA_ "SPN" SG_ 2566788094 AuxValve3State 1939;
BA_ "SPN" SG_ 2566788094 AuxValve3RetractPortEstFlow 1938;
BA_ "SPN" SG_ 2566788094 AuxValve3ExtendPortEstFlow 1937;
VAL_ 2566663422 TrlrBrkClprLnngClranceAxle5Right 3 "Not available / not applicable" 2 "Error" 1 "Caliper lining clearance is low" 0 "Caliper lining clearance is adequate" ;
VAL_ 2566663422 TrlrBrkClprLnngClaranceAxle5Left 3 "Not available / not applicable" 2 "Error" 1 "Caliper lining clearance is low" 0 "Caliper lining clearance is adequate" ;
VAL_ 2566663422 TrlrBrkClprLnngClranceAxle4Right 3 "Not available / not applicable" 2 "Error" 1 "Caliper lining clearance is low" 0 "Caliper lining clearance is adequate" ;
VAL_ 2566663422 TrlrBrkClprLnngClaranceAxle4Left 3 "Not available / not applicable" 2 "Error" 1 "Caliper lining clearance is low" 0 "Caliper lining clearance is adequate" ;
VAL_ 2566663422 TrlrBrkClprLnngClranceAxle3Right 3 "Not available / not applicable" 2 "Error" 1 "Caliper lining clearance is low" 0 "Caliper lining clearance is adequate" ;
VAL_ 2566663422 TrlrBrkClprLnngClaranceAxle3Left 3 "Not available / not applicable" 2 "Error" 1 "Caliper lining clearance is low" 0 "Caliper lining clearance is adequate" ;
VAL_ 2566663422 TrlrBrkClprLnngClranceAxle2Right 3 "Not available / not applicable" 2 "Error" 1 "Caliper lining clearance is low" 0 "Caliper lining clearance is adequate" ;
VAL_ 2566663422 TrlrBrkClprLnngClaranceAxle2Left 3 "Not available / not applicable" 2 "Error" 1 "Caliper lining clearance is low" 0 "Caliper lining clearance is adequate" ;
VAL_ 2566663422 TrlrBrkClprLnngClranceAxle1Right 3 "Not available / not applicable" 2 "Error" 1 "Caliper lining clearance is low" 0 "Caliper lining clearance is adequate" ;
VAL_ 2566663422 TrlrBrkClprLnngClaranceAxle1Left 3 "Not available / not applicable" 2 "Error" 1 "Caliper lining clearance is low" 0 "Caliper lining clearance is adequate" ;
VAL_ 2566663422 TrctrBrkClprLnngClrnceAxle5Right 3 "Not available / not applicable" 2 "Error" 1 "Caliper lining clearance is low" 0 "Caliper lining clearance is adequate" ;
VAL_ 2566663422 TrctrBrkClprLnngClranceAxle5Left 3 "Not available / not applicable" 2 "Error" 1 "Caliper lining clearance is low" 0 "Caliper lining clearance is adequate" ;
VAL_ 2566663422 TrctrBrkClprLnngClrnceAxle4Right 3 "Not available / not applicable" 2 "Error" 1 "Caliper lining clearance is low" 0 "Caliper lining clearance is adequate" ;
VAL_ 2566663422 TrctrBrkClprLnngClranceAxle4Left 3 "Not available / not applicable" 2 "Error" 1 "Caliper lining clearance is low" 0 "Caliper lining clearance is adequate" ;
VAL_ 2566663422 TrctrBrkClprLnngClrnceAxle3Right 3 "Not available / not applicable" 2 "Error" 1 "Caliper lining clearance is low" 0 "Caliper lining clearance is adequate" ;
VAL_ 2566663422 TrctrBrkClprLnngClranceAxle3Left 3 "Not available / not applicable" 2 "Error" 1 "Caliper lining clearance is low" 0 "Caliper lining clearance is adequate" ;
VAL_ 2566663422 TrctrBrkClprLnngClrnceAxle2Right 3 "Not available / not applicable" 2 "Error" 1 "Caliper lining clearance is low" 0 "Caliper lining clearance is adequate" ;
VAL_ 2566663422 TrctrBrkClprLnngClranceAxle2Left 3 "Not available / not applicable" 2 "Error" 1 "Caliper lining clearance is low" 0 "Caliper lining clearance is adequate" ;
VAL_ 2566663422 TrctrBrkClprLnngClrnceAxle1Right 3 "Not available / not applicable" 2 "Error" 1 "Caliper lining clearance is low" 0 "Caliper lining clearance is adequate" ;
VAL_ 2566663422 TrctrBrkClprLnngClranceAxle1Left 3 "Not available / not applicable" 2 "Error" 1 "Caliper lining clearance is low" 0 "Caliper lining clearance is adequate" ;
VAL_ 2566662654 LaneMarkQualityOnTheRightSide 7 "not available or not installed" 6 "error" 3 "perfect recognition of lane marks" 2 "good reliablity of detected lane marks" 1 "low reliablity of detected lane marks" 0 "no lane marks detected" ;
VAL_ 2566662654 LaneMarkQualityOnTheLeftSide 7 "not available or not installed" 6 "error" 3 "perfect recognition of lane marks" 2 "good reliablity of detected lane marks" 1 "low reliablity of detected lane marks" 0 "no lane marks detected" ;
VAL_ 2566662654 LaneDepartureAngleRight 255 "not available or not installed" 254 "error" 253 "reserved / not used" 252 "not reliable" 251 "not in range" ;
VAL_ 2566662654 LaneDepartureAngleLeft 255 "not available or not installed" 254 "error" 253 "reserved / not used" 252 "not reliable" 251 "not in range" ;
VAL_ 2566662654 RghtDstncTLnMrkFrmVehiclesMiddle 255 "not available or not installed" 254 "error" 253 "reserved / not used" 252 "not reliable" 251 "not in range" ;
VAL_ 2566662654 LftDstncTLnMrkFromVehiclesMiddle 255 "not available or not installed" 254 "error" 253 "reserved / not used" 252 "not reliable" 251 "not in range" ;
VAL_ 2364593150 PrdctvCrsCtrlDrvlnDsnggInhibitRq 2 "Reserved" 1 "Driveline Disengage Inhibit Request" 0 "No Inhibit Request" 3 "Don't care/take no action" ;
VAL_ 2364593150 VhclSpdCtrlOvrrideEventIndicator 3 "Not available" 2 "Reserved" 1 "Speed Control event is active" 0 "Speed Control event is not active" ;
VAL_ 2364593150 PrdctvCrsCtrlSpeedEventIndicator 3 "Not available" 2 "Decreased speed event is active" 1 "Increased speed event is active" 0 "No speed event is active" ;
VAL_ 2364593150 PredictiveCruiseCtrlEventInRange 3 "Not available" 2 "Error" 1 "PCC event in range" 0 "No PCC event in range" ;
VAL_ 2364593150 VehicleSpeedCtrlOverrideRq 3 "Don't care/take no action" 2 "Reserved" 1 "Speed control override requested" 0 "No speed control override requested" ;
VAL_ 2364593150 PredictiveCruiseCtrlState 15 "Not Available" 14 "Error" 8 "Enabled,  but not functional due to self test" 7 "Enabled,  but not functional due to inhibited by driver" 6 "Enabled,  but not functional due to vehicle speed below speed threshold" 5 "Enabled,  but not functional due to predicted path not available" 4 "Enabled,  but not functional due to road grade info not available" 3 "Enabled,  but not functional due to map position not available" 2 "Enabled,  but not functional due to vehicle position not available" 1 "Enabled" 0 "Disabled" ;
VAL_ 2364592894 InAirSourceVlv 3 "Not Available" 2 "Error" 1 "On" 0 "Off" ;
VAL_ 2364592638 EngCylHdBypssActtr1OprtionStatus 15 "Not available" 14 "Error" 6 "Calibration in Progress" 5 "Uncontrolled Shutdown Active" 4 "Controlled Shutdown Active" 3 "Derate Active" 2 "Alarm High Severity" 1 "Alarm" 0 "Normal" ;
VAL_ 2364592638 EngCylHdBypssActuator1TempStatus 7 "Not available" 6 "Error" 5 "Not Defined" 4 "Low Most severe" 3 "Low Least severe" 2 "In Range" 1 "High Least severe" 0 "High Most severe" ;
VAL_ 2364592382 EngCyl24ExcludeFromCombustionRq 1 "Include for Combustion" 0 "Exclude from Combustion" 3 "Not available/Do not care" 2 "Reserved" ;
VAL_ 2364592382 EngCyl23ExcludeFromCombustionRq 3 "Not available/Do not care" 2 "Reserved" 1 "Include for Combustion" 0 "Exclude from Combustion" ;
VAL_ 2364592382 EngCyl22ExcludeFromCombustionRq 3 "Not available/Do not care" 2 "Reserved" 1 "Include for Combustion" 0 "Exclude from Combustion" ;
VAL_ 2364592382 EngCyl21ExcludeFromCombustionRq 3 "Not available/Do not care" 2 "Reserved" 1 "Include for Combustion" 0 "Exclude from Combustion" ;
VAL_ 2364592382 EngCyl20ExcludeFromCombustionRq 3 "Not available/Do not care" 2 "Reserved" 1 "Include for Combustion" 0 "Exclude from Combustion" ;
VAL_ 2364592382 EngCyl19ExcludeFromCombustionRq 3 "Not available/Do not care" 2 "Reserved" 1 "Include for Combustion" 0 "Exclude from Combustion" ;
VAL_ 2364592382 EngCyl18ExcludeFromCombustionRq 3 "Not available/Do not care" 2 "Reserved" 1 "Include for Combustion" 0 "Exclude from Combustion" ;
VAL_ 2364592382 EngCyl17ExcludeFromCombustionRq 3 "Not available/Do not care" 2 "Reserved" 1 "Include for Combustion" 0 "Exclude from Combustion" ;
VAL_ 2364592382 EngCyl16ExcludeFromCombustionRq 3 "Not available/Do not care" 2 "Reserved" 1 "Include for Combustion" 0 "Exclude from Combustion" ;
VAL_ 2364592382 EngCyl15ExcludeFromCombustionRq 3 "Not available/Do not care" 2 "Reserved" 1 "Include for Combustion" 0 "Exclude from Combustion" ;
VAL_ 2364592382 EngCyl14ExcludeFromCombustionRq 3 "Not available/Do not care" 2 "Reserved" 1 "Include for Combustion" 0 "Exclude from Combustion" ;
VAL_ 2364592382 EngCyl13ExcludeFromCombustionRq 3 "Not available/Do not care" 2 "Reserved" 1 "Include for Combustion" 0 "Exclude from Combustion" ;
VAL_ 2364592382 EngCyl12ExcludeFromCombustionRq 3 "Not available/Do not care" 2 "Reserved" 1 "Include for Combustion" 0 "Exclude from Combustion" ;
VAL_ 2364592382 EngCyl11ExcludeFromCombustionRq 3 "Not available/Do not care" 2 "Reserved" 1 "Include for Combustion" 0 "Exclude from Combustion" ;
VAL_ 2364592382 EngCyl10ExcludeFromCombustionRq 3 "Not available/Do not care" 2 "Reserved" 1 "Include for Combustion" 0 "Exclude from Combustion" ;
VAL_ 2364592382 EngCyl9ExcludeFromCombustionRq 3 "Not available/Do not care" 2 "Reserved" 1 "Include for Combustion" 0 "Exclude from Combustion" ;
VAL_ 2364592382 EngCyl8ExcludeFromCombustionRq 3 "Not available/Do not care" 2 "Reserved" 1 "Include for Combustion" 0 "Exclude from Combustion" ;
VAL_ 2364592382 EngCyl7ExcludeFromCombustionRq 3 "Not available/Do not care" 2 "Reserved" 1 "Include for Combustion" 0 "Exclude from Combustion" ;
VAL_ 2364592382 EngCyl6ExcludeFromCombustionRq 3 "Not available/Do not care" 2 "Reserved" 1 "Include for Combustion" 0 "Exclude from Combustion" ;
VAL_ 2364592382 EngCyl5ExcludeFromCombustionRq 3 "Not available/Do not care" 2 "Reserved" 1 "Include for Combustion" 0 "Exclude from Combustion" ;
VAL_ 2364592382 EngCyl4ExcludeFromCombustionRq 3 "Not available/Do not care" 2 "Reserved" 1 "Include for Combustion" 0 "Exclude from Combustion" ;
VAL_ 2364592382 EngCyl3ExcludeFromCombustionRq 3 "Not available/Do not care" 2 "Reserved" 1 "Include for Combustion" 0 "Exclude from Combustion" ;
VAL_ 2364592382 EngCyl2ExcludeFromCombustionRq 3 "Not available/Do not care" 2 "Reserved" 1 "Include for Combustion" 0 "Exclude from Combustion" ;
VAL_ 2364592382 EngCyl1ExcludeFromCombustionRq 3 "Not available/Do not care" 2 "Reserved" 1 "Include for Combustion" 0 "Exclude from Combustion" ;
VAL_ 2558918398 TransAutoNeutralEnableSw 3 "Not Available" 2 "Error" 1 "On" 0 "Off" ;
VAL_ 2558918398 AFTRegenEngSpdAllowedSw 3 "Not Available" 2 "Error" 1 "Aftertreatment regeneration is allowed when engine speed exceeds regeneration threshold" 0 "Aftertreatment regeneration is not allowed when engine speed exceeds regeneration threshold" ;
VAL_ 2558918398 ElevatedEngSpdAllowedSw 3 "Not Available" 2 "Error" 1 "Allowed to elevate engine speed" 0 "Not allowed to elevate engine speed" ;
VAL_ 2558918398 PrdctiveCruiseCtrlDeactivationRq 3 "Not available" 2 "Error" 1 "Predictive cruise control is requested to be deactived" 0 "Predictive cruise control is not requested to be deactived" ;
VAL_ 2558918398 PredictiveCruiseCtrlEnableSwitch 3 "Not available" 2 "Error" 1 "Predictive cruise control is enabled" 0 "Predictive cruise control is not enabled" ;
VAL_ 2558918398 HtExchngerDebrisPurgeForceSwitch 3 "not available" 2 "error" 1 "active" 0 "not active" ;
VAL_ 2558918398 HtExchngrDbrisPurgeInhibitSwitch 3 "not available" 2 "error" 1 "active" 0 "not active" ;
VAL_ 2558918398 SCROprtrInducementOverrideSwitch 3 "Not Available" 2 "Error" 1 "On" 0 "Off" ;
VAL_ 2558852862 Dewpoint 3 "Not available" 2 "SAE reserved" 1 "Dewpoint has been reached" 0 "Dewpoint has not been reached" ;
VAL_ 2558852862 RegenReq 3 "Not available" 2 "SAE reserved" 1 "Regeneration requested" 0 "Regeneration not requested" ;
VAL_ 2558852862 ShutdownReq 3 "Not available" 2 "SAE reserved" 1 "Shutdown request active" 0 "Shutdown request not active" ;
VAL_ 2558787326 PayloadCalibSetPointCmd 15 "Not Available" 14 "Error" 13 "Reserved" 12 "Reset Calibration" 11 "Correction Point" 10 "End Point" 9 "Calibration Reference Point 9" 8 "Calibration Reference Point 8" 7 "Calibration Reference Point 7" 6 "Calibration Reference Point 6" 5 "Calibration Reference Point 5" 4 "Calibration Reference Point 4" 3 "Calibration Reference Point 3" 2 "Calibration Reference Point 2" 1 "Calibration Reference Point 1" 0 "Zero Point" ;
VAL_ 2558721790 SnsrEnableSetting 3 "Don't Care / Take No Action" 2 "Reserved / Not Defined" 1 "On / Enable" 0 "Off / Isolate / Disable" ;
VAL_ 2558656254 RqToPermitDEFDosingTestInjection 7 "don't care" 2 "urgent request to permit DEF Dosing Test Injection or test injection is running" 1 "request to permit DEF Dosing Test Injection or test injection is running" 0 "no request" ;
VAL_ 2558656254 RqToPermitDEFHydStiffnessCheck 3 "don't care" 2 "reserved" 1 "request to permit DEF hydraulic stiffness check or stiffness check is running" 0 "no request" ;
VAL_ 2558656254 ThermalManagementInhReq 3 "Not Available" 2 "Reserved for SAE assignment" 1 "Inhibit" 0 "Do not inhibit" ;
VAL_ 2558590718 ShutdownCmd 3 "Don't Care / Take No Action" 2 "Reserved" 1 "On" 0 "Off" ;
VAL_ 2558590718 PropulsionDisableReq 3 "Don't Care / Take No Action" 2 "Reserved" 1 "On" 0 "Off" ;
VAL_ 2558590718 HybrdSystmRgnrtvBrakingDisableRq 3 "Don't care / take no action" 2 "Reserved" 1 "Regenerative braking disable request is active" 0 "Regenerative braking disable request is not active" ;
VAL_ 2558590718 HybridSystemProtectionOverrideRq 3 "Don't care / take no action" 2 "Reserved" 1 "Active" 0 "Not active" ;
VAL_ 2350710526 TransOverrideCtrlModePriority 3 "Low priority" 2 "Medium priority" 1 "High priority" 0 "Highest priority" ;
VAL_ 2350710526 TransOverrideCtrlMode 3 "Speed/torque limit control" 2 "Torque control" 1 "Speed control" 0 "Override disabled" ;
VAL_ 2566801918 GroundBasedDirection 3 "Not available" 2 "Error indication" 1 "Forward" 0 "Reverse" ;
VAL_ 2566801662 KeySwitchNOTOFF 3 "Not available" 2 "Error indication" 1 "Key Switch Not Off" 0 "Key Switch Off" ;
VAL_ 2566801662 WheelBasedDirection 3 "Not available" 2 "Error indication" 1 "Forward" 0 "Reverse" ;
VAL_ 2566801406 ImplementInWorkState 3 "Not available" 2 "Error indication" 1 "Implement is 'in-work'" 0 "Implement is 'out of work'" ;
VAL_ 2566801406 ImplementTransportState 3 "Not available" 2 "Error indication" 1 "Implement may be transported" 0 "Implement may Not be transported " ;
VAL_ 2566801406 ImplementParkState 3 "Not available" 2 "Error indication" 1 "Implement may be disconnected" 0 "Implement may Not be disconnected " ;
VAL_ 2566801406 ImplementWorkState 3 "Not available" 2 "Error indication" 1 "Implement is ready for field work" 0 "Implement is Not ready for field work " ;
VAL_ 2566801406 MaintainECUPower 3 "Don't Care" 2 "Reserved " 1 "Requirement for 2 more seconds of ECU_PWR" 0 "No Further Requirement for ECU_PWR" ;
VAL_ 2566801406 MaintainAcuatorPower 3 "Don't Care" 2 "Reserved " 1 "Requirement for 2 more seconds of PWR" 0 "No Further Requirement for PWR" ;
VAL_ 2566801150 FrontHitchInworkIndication 3 "Not available" 2 "Error indication" 1 "Hitch position is in-work" 0 "Hitch position is out-of-work " ;
VAL_ 2566800894 RearHitchInworkIndication 3 "Not available" 2 "Error indication" 1 "Hitch position is in-work" 0 "Hitch position is out-of-work " ;
VAL_ 2566800638 FrontPowerTakeOffEngagement 3 "Not available" 2 "Error indication" 1 "Power take off engaged" 0 "Power take off disengaged" ;
VAL_ 2566800638 FrontPowerTakeOffMode 3 "Not available" 2 "Error indication" 1 "Power take off mode is 1000" 0 "Power take off mode is 540" ;
VAL_ 2566800638 FrontPowerTakeOffEconomyMode 3 "Not available" 2 "Error indication" 1 "Power take off economy mode is engaged" 0 "Power take off economy mode is disengaged" ;
VAL_ 2566800382 RearPowerTakeOffEngagement 3 "Not available" 2 "Error indication" 1 "Power take off engaged" 0 "Power take off disengaged" ;
VAL_ 2566800382 RearPowerTakeOffMode 3 "Not available" 2 "Error indication" 1 "Power take off mode is 1000" 0 "Power take off mode is 540" ;
VAL_ 2566800382 RearPowerTakeOffEconomyMode 3 "Not available" 2 "Error indication" 1 "Power take off economy mode is engaged" 0 "Power take off economy mode is disengaged" ;
VAL_ 2566800126 FrontPowerTakeOffModeCmd 3 "Don't Care" 2 "Reserved" 1 "Select 1000 rpm mode " 0 "Select 540 rpm mode" ;
VAL_ 2566800126 RearPowerTakeOffModeCmd 3 "Don't Care" 2 "Reserved" 1 "Select 1000 rpm mode " 0 "Select 540 rpm mode" ;
VAL_ 2566800126 FrontPowerTakeOffEconomyModeCmd 3 "Don't Care" 2 "Reserved" 1 "Engage Power take off‘s economy mode" 0 "Disengage Power take off‘s economy mode" ;
VAL_ 2566800126 RearPowerTakeOffEconomyModeCmd 3 "Don't Care" 2 "Reserved" 1 "Engage Power take off‘s economy mode" 0 "Disengage Power take off‘s economy mode" ;
VAL_ 2566800126 FrontPowerTakeOffEngagementCmd 3 "Don't Care" 2 "Reserved" 1 "Engage Power take off " 0 "Disengage Power take off" ;
VAL_ 2566800126 RearPowerTakeOffEngagementCmd 3 "Don't Care" 2 "Reserved" 1 "Engage Power take off " 0 "Disengage Power take off" ;
VAL_ 2566799358 AuxValve15FailSafeModeCmd 3 "Don't Care" 2 "Reserved" 1 "Float" 0 "Block" ;
VAL_ 2566799358 AuxValve15StateCmd 15 "Don't Care" 3 "Float" 2 "Retract" 1 "Extend" 0 "Block" ;
VAL_ 2566799102 AuxValve14FailSafeModeCmd 3 "Don't Care" 2 "Reserved" 1 "Float" 0 "Block" ;
VAL_ 2566799102 AuxValve14StateCmd 3 "Float" 2 "Retract" 1 "Extend" 0 "Block" 15 "Don't Care" ;
VAL_ 2566798846 AuxValve13FailSafeModeCmd 3 "Don't Care" 2 "Reserved" 1 "Float" 0 "Block" ;
VAL_ 2566798846 AuxValve13StateCmd 15 "Don't Care" 3 "Float" 2 "Retract" 1 "Extend" 0 "Block" ;
VAL_ 2566798590 AuxValve12FailSafeModeCmd 3 "Don't Care" 2 "Reserved" 1 "Float" 0 "Block" ;
VAL_ 2566798590 AuxValve12StateCmd 15 "Don't Care" 3 "Float" 2 "Retract" 1 "Extend" 0 "Block" ;
VAL_ 2566798334 AuxValve11FailSafeModeCmd 3 "Don't Care" 2 "Reserved" 1 "Float" 0 "Block" ;
VAL_ 2566798334 AuxValve11StateCmd 15 "Don't Care" 3 "Float" 2 "Retract" 1 "Extend" 0 "Block" ;
VAL_ 2566798078 AuxValve10FailSafeModeCmd 3 "Don't Care" 2 "Reserved" 1 "Float" 0 "Block" ;
VAL_ 2566798078 AuxValve10StateCmd 15 "Don't Care" 3 "Float" 2 "Retract" 1 "Extend" 0 "Block" ;
VAL_ 2566797822 AuxValve9FailSafeModeCmd 3 "Don't Care" 2 "Reserved" 1 "Float" 0 "Block" ;
VAL_ 2566797822 AuxValve9StateCmd 15 "Don't Care" 3 "Float" 2 "Retract" 1 "Extend" 0 "Block" ;
VAL_ 2566797566 AuxValve8FailSafeModeCmd 3 "Don't Care" 2 "Reserved" 1 "Float" 0 "Block" ;
VAL_ 2566797566 AuxValve8StateCmd 15 "Don't Care" 3 "Float" 2 "Retract" 1 "Extend" 0 "Block" ;
VAL_ 2566797310 AuxValve7FailSafeModeCmd 3 "Don't Care" 2 "Reserved" 1 "Float" 0 "Block" ;
VAL_ 2566797310 AuxValve7StateCmd 15 "Don't Care" 3 "Float" 2 "Retract" 1 "Extend" 0 "Block" ;
VAL_ 2566797054 AuxValve6FailSafeModeCmd 3 "Don't Care" 2 "Reserved" 1 "Float" 0 "Block" ;
VAL_ 2566797054 AuxValve6StateCmd 15 "Don't Care" 3 "Float" 2 "Retract" 1 "Extend" 0 "Block" ;
VAL_ 2566796798 AuxValve5FailSafeModeCmd 3 "Don't Care" 2 "Reserved" 1 "Float" 0 "Block" ;
VAL_ 2566796798 AuxValve5StateCmd 15 "Don't Care" 3 "Float" 2 "Retract" 1 "Extend" 0 "Block" ;
VAL_ 2566796542 AuxValve4FailSafeModeCmd 3 "Don't Care" 2 "Reserved" 1 "Float" 0 "Block" ;
VAL_ 2566796542 AuxValve4StateCmd 15 "Don't Care" 3 "Float" 2 "Retract" 1 "Extend" 0 "Block" ;
VAL_ 2566796286 AuxValve3FailSafeModeCmd 3 "Don't Care" 2 "Reserved" 1 "Float" 0 "Block" ;
VAL_ 2566796286 AuxValve3StateCmd 15 "Don't Care" 3 "Float" 2 "Retract" 1 "Extend" 0 "Block" ;
VAL_ 2566796030 AuxValve2FailSafeModeCmd 3 "Don't Care" 2 "Reserved" 1 "Float" 0 "Block" ;
VAL_ 2566796030 AuxValve2StateCmd 15 "Don't Care" 3 "Float" 2 "Retract" 1 "Extend" 0 "Block" ;
VAL_ 2566795774 AuxValve1FailSafeModeCmd 3 "Don't Care" 2 "Reserved" 1 "Float" 0 "Block" ;
VAL_ 2566795774 AuxValve1StateCmd 15 "Don't Care" 3 "Float" 2 "Retract" 1 "Extend" 0 "Block" ;
VAL_ 2566795518 AuxValve0FailSafeModeCmd 3 "Don't Care" 2 "Reserved" 1 "Float" 0 "Block" ;
VAL_ 2566795518 AuxValve0StateCmd 15 "Don't Care" 3 "Float" 2 "Retract" 1 "Extend" 0 "Block" ;
VAL_ 2566791166 AuxValve15FailSafeMode 3 "Not available" 2 "Error" 1 "Float" 0 "Block" ;
VAL_ 2566791166 AuxValve15State 15 "Don't Care" 3 "Floating" 2 "Retract" 1 "Extend" 0 "Blocked" ;
VAL_ 2566790910 AuxValve14FailSafeMode 3 "Not available" 2 "Error indication" 1 "Float" 0 "Block" ;
VAL_ 2566790910 AuxValve14State 15 "Don't Care" 3 "Floating" 2 "Retract" 1 "Extend" 0 "Blocked" ;
VAL_ 2566790654 AuxValve13FailSafeMode 3 "Not available" 2 "Error indication" 1 "Float" 0 "Block" ;
VAL_ 2566790654 AuxValve13State 1 "Extend" 0 "Blocked" 15 "Don't Care" 3 "Floating" 2 "Retract" ;
VAL_ 2566790398 AuxValve12FailSafeMode 3 "Not available" 2 "Error indication" 1 "Float" 0 "Block" ;
VAL_ 2566790398 AuxValve12State 15 "Don't Care" 3 "Floating" 2 "Retract" 1 "Extend" 0 "Blocked" ;
VAL_ 2566790142 AuxValve11FailSafeMode 3 "Not available" 2 "Error indication" 1 "Float" 0 "Block" ;
VAL_ 2566790142 AuxValve11State 15 "Don't Care" 3 "Floating" 2 "Retract" 1 "Extend" 0 "Blocked" ;
VAL_ 2566789886 AuxValve10FailSafeMode 3 "Not available" 2 "Error indication" 1 "Float" 0 "Block" ;
VAL_ 2566789886 AuxValve10State 15 "Don't Care" 3 "Floating" 2 "Retract" 1 "Extend" 0 "Blocked" ;
VAL_ 2566789630 AuxValve9FailSafeMode 3 "Not available" 2 "Error indication" 1 "Float" 0 "Block" ;
VAL_ 2566789630 AuxValve9State 15 "Don't Care" 3 "Floating" 2 "Retract" 1 "Extend" 0 "Blocked" ;
VAL_ 2566789374 AuxValve8FailSafeMode 3 "Not available" 2 "Error indication" 1 "Float" 0 "Block" ;
VAL_ 2566789374 AuxValve8State 15 "Don't Care" 3 "Floating" 2 "Retract" 1 "Extend" 0 "Blocked" ;
VAL_ 2566789118 AuxValve7FailSafeMode 3 "Not available" 2 "Error indication" 1 "Float" 0 "Block" ;
VAL_ 2566789118 AuxValve7State 15 "Don't Care" 3 "Floating" 2 "Retract" 1 "Extend" 0 "Blocked" ;
VAL_ 2566788862 AuxValve6FailSafeMode 3 "Not available" 2 "Error indication" 1 "Float" 0 "Block" ;
VAL_ 2566788862 AuxValve6State 15 "Don't Care" 3 "Floating" 2 "Retract" 1 "Extend" 0 "Blocked" ;
VAL_ 2566788606 AuxValve5FailSafeMode 3 "Not available" 2 "Error indication" 1 "Float" 0 "Block" ;
VAL_ 2566788606 AuxValve5State 15 "Don't Care" 3 "Floating" 2 "Retract" 1 "Extend" 0 "Blocked" ;
VAL_ 2566788350 AuxValve4FailSafeMode 3 "Not available" 2 "Error indication" 1 "Float" 0 "Block" ;
VAL_ 2566788350 AuxValve4State 15 "Don't Care" 3 "Floating" 2 "Retract" 1 "Extend" 0 "Blocked" ;
VAL_ 2566788094 AuxValve3FailSafeMode 3 "Not available" 2 "Error indication" 1 "Float" 0 "Block" ;
VAL_ 2566788094 AuxValve3State 15 "Don't Care" 3 "Floating" 2 "Retract" 1 "Extend" 0 "Blocked" ;
